VERSION ""

NS_ :

BS_:

BU_: ICC DVR EPC BBCM EAMP CMSM SBOX FLZCU_HCU_IC FLZCU_IC HCU_IC FLZCU_Signal_IC CGW TBOX BNCM CWC FRZCU

BO_ 1224 BMS_12: 16 CGW
 SG_ BMS_HvBattCellVoltMax_Num : 23|8@0+ (1,0) [0|250] ""  ICC
 SG_ BMS_HvBattCellVoltMax : 31|16@0+ (0.001,0) [0|15] "V"  ICC
 SG_ BMS_HvBattCellVoltMin_Num : 47|8@0+ (1,0) [0|250] ""  ICC
 SG_ BMS_HvBattCellVoltMin : 55|16@0+ (0.001,0) [0|15] "V"  ICC
 SG_ BMS_Chg_Sts : 87|4@0+ (1,0) [0|15] ""  ICC

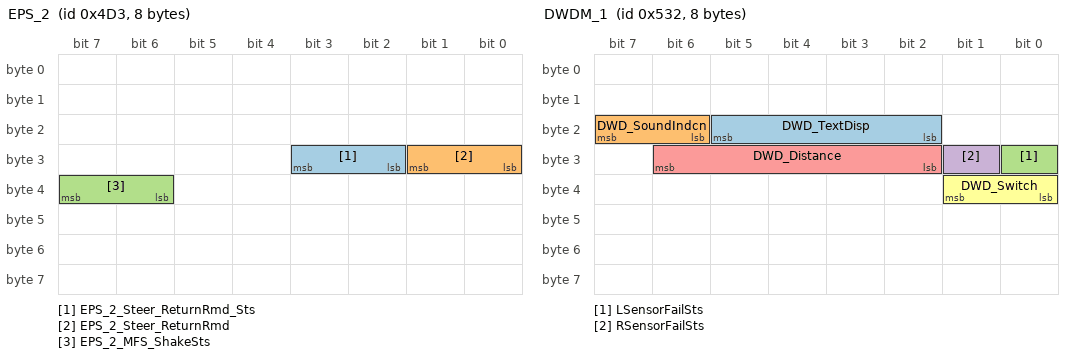
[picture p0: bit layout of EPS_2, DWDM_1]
BO_ 1235 EPS_2: 8 CGW
 SG_ EPS_2_Steer_ReturnRmd_Sts : 27|2@0+ (1,0) [0|3] ""  ICC
 SG_ EPS_2_Steer_ReturnRmd : 25|2@0+ (1,0) [0|3] ""  ICC
 SG_ EPS_2_MFS_ShakeSts : 39|2@0+ (1,0) [0|3] ""  ICC

BO_ 1330 DWDM_1: 8 CGW
 SG_ DWD_TextDisp : 21|4@0+ (1,0) [0|15] ""  ICC
 SG_ DWD_SoundIndcn : 23|2@0+ (1,0) [0|3] ""  ICC
 SG_ LSensorFailSts : 24|1@0+ (1,0) [0|1] ""  ICC
 SG_ RSensorFailSts : 25|1@0+ (1,0) [0|1] ""  ICC
 SG_ DWD_Distance : 30|5@0+ (1,0) [0|31] ""  ICC
 SG_ DWD_Switch : 33|2@0+ (1,0) [0|3] ""  ICC

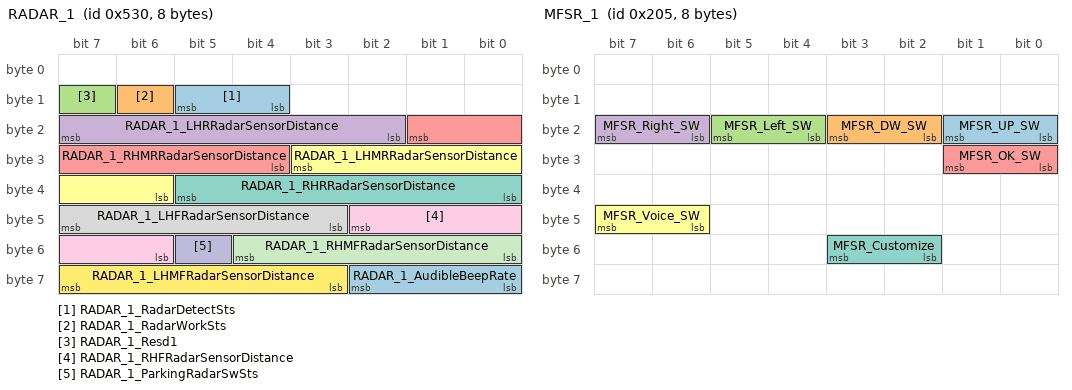
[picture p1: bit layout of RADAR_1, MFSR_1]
BO_ 1328 RADAR_1: 8 CGW
 SG_ RADAR_1_RadarDetectSts : 13|2@0+ (1,0) [0|3] "Bit"  ICC
 SG_ RADAR_1_RadarWorkSts : 14|1@0+ (1,0) [0|1] "Bit"  ICC
 SG_ RADAR_1_Resd1 : 15|1@0+ (1,0) [0|1] ""  ICC
 SG_ RADAR_1_LHRRadarSensorDistance : 23|6@0+ (5,25) [25|180] "Cm"  ICC
 SG_ RADAR_1_RHMRRadarSensorDistance : 17|6@0+ (5,25) [25|180] "Cm"  ICC
 SG_ RADAR_1_LHMRRadarSensorDistance : 27|6@0+ (5,25) [25|180] "Cm"  ICC
 SG_ RADAR_1_RHRRadarSensorDistance : 37|6@0+ (5,25) [25|180] "Cm"  ICC
 SG_ RADAR_1_LHFRadarSensorDistance : 47|5@0+ (5,25) [25|160] "Cm"  ICC
 SG_ RADAR_1_RHFRadarSensorDistance : 42|5@0+ (5,25) [25|160] "Cm"  ICC
 SG_ RADAR_1_ParkingRadarSwSts : 53|1@0+ (1,0) [0|1] "Bit"  ICC
 SG_ RADAR_1_RHMFRadarSensorDistance : 52|5@0+ (5,25) [25|160] "Cm"  ICC
 SG_ RADAR_1_LHMFRadarSensorDistance : 63|5@0+ (5,25) [25|160] "Cm"  ICC
 SG_ RADAR_1_AudibleBeepRate : 58|3@0+ (1,0) [0|7] "Bit"  ICC

BO_ 259 EMS_6: 16 CGW
 SG_ EMS_EngineSpeed_Actual : 39|16@0+ (0.25,0) [0|16383] "rpm"  ICC

BO_ 1234 FRZCU_11: 32 CGW
 SG_ FRZCU_FRSeatHeiFb : 23|7@0+ (1,-1) [-1|100] "%"  ICC,BBCM
 SG_ FRZCU_FRSeatLvlFb : 31|7@0+ (1,-1) [-1|100] "%"  ICC,BBCM
 SG_ FRZCU_FRSeatBackAgFb : 39|7@0+ (1,-1) [-1|100] "%"  ICC,BBCM
 SG_ FRZCU_FRSeatLegSpprtFb : 47|7@0+ (1,-1) [-1|100] "%"  ICC
 SG_ FRZCU_FRWinSts : 55|3@0+ (1,0) [0|7] ""  ICC
 SG_ FRZCU_RRWinSts : 52|3@0+ (1,0) [0|7] ""  ICC
 SG_ FRZCU_FRSeatLegRestAngleFb : 62|7@0+ (1,-1) [-1|100] "%"  ICC
 SG_ FRZCU_FRSeatCushFb : 86|7@0+ (1,-1) [-1|100] "%"  ICC,BBCM
 SG_ FRZCU_FRSeatNeedMemory : 105|2@0+ (1,0) [0|3] ""  ICC
 SG_ FRZCU_FRMemoryFb : 107|2@0+ (1,0) [0|3] ""  ICC
 SG_ FRZCU_FRRecoverFb : 109|2@0+ (1,0) [0|3] ""  ICC
 SG_ FRZCU_EasyEntryExitFb : 111|2@0+ (1,0) [0|3] ""  ICC
 SG_ FRZCU_EnjoyableSeatWarning : 113|2@0+ (1,0) [0|3] ""  ICC
 SG_ FRZCU_EnjoyableSeatSts : 115|2@0+ (1,0) [0|3] ""  ICC
 SG_ SeatHeatLevelsFR : 127|3@0+ (1,0) [0|7] ""  ICC
 SG_ SeatVentLevelsFR : 123|2@0+ (1,0) [0|3] ""  ICC
 SG_ SeatHeatLevelsRR : 151|3@0+ (1,0) [0|7] ""  ICC
 SG_ SeatVentLevelsRR : 147|2@0+ (1,0) [0|3] ""  ICC
 SG_ FRZCU_FRSeatFoldFb : 167|7@0+ (1,-1) [-1|100] "%"  ICC

BO_ 517 MFSR_1: 8 CGW
 SG_ MFSR_UP_SW : 17|2@0+ (1,0) [0|3] ""  ICC
 SG_ MFSR_DW_SW : 19|2@0+ (1,0) [0|3] ""  ICC
 SG_ MFSR_Left_SW : 21|2@0+ (1,0) [0|3] ""  ICC
 SG_ MFSR_Right_SW : 23|2@0+ (1,0) [0|3] ""  ICC
 SG_ MFSR_OK_SW : 25|2@0+ (1,0) [0|3] ""  ICC
 SG_ MFSR_Voice_SW : 47|2@0+ (1,0) [0|3] ""  ICC
 SG_ MFSR_Customize : 51|2@0+ (1,0) [0|3] ""  ICC

BO_ 1096 TMS_11: 32 CGW
 SG_ TMS_AutoDefogActiveSts : 37|1@0+ (1,0) [0|1] ""  ICC
 SG_ TMS_AirPurgeReminderSts : 17|2@0+ (1,0) [0|3] ""  ICC
 SG_ TMS_BT_Reduce_Wind_SpeedSts : 23|2@0+ (1,0) [0|3] "Bit"  ICC
 SG_ TMS_First_BlowingSts : 21|2@0+ (1,0) [0|3] "Bit"  ICC
 SG_ TMS_CirculationInTunnelsSts : 19|2@0+ (1,0) [0|3] "Bit"  ICC
 SG_ TMS_crosscountry_coolingSts : 29|2@0+ (1,0) [0|3] "Bit"  ICC
 SG_ TMS_ParkingAirConditioningStatus : 27|2@0+ (1,0) [0|3] "Bit"  ICC
 SG_ TMS_CoolantFillSts : 25|2@0+ (1,0) [0|3] "Bit"  ICC
 SG_ TMS_UVC_ControlSts : 39|2@0+ (1,0) [0|3] "Bit"  ICC
 SG_ TMS_UVC_LuminanceSts : 36|3@0+ (1,0) [0|7] "Bit"  ICC
 SG_ TMS_ICC_Lightoff_Sts : 33|2@0+ (1,0) [0|3] ""  ICC
 SG_ TMS_ICC_Memoff_Sts : 47|2@0+ (1,0) [0|3] ""  ICC
 SG_ TMS_keepwarmSet_TemperatureSts : 55|8@0+ (1,0) [0|254] "Bit"  ICC
 SG_ TMS_BiochemicalFuncSts : 95|2@0+ (1,0) [0|3] ""  ICC
 SG_ TMS_TimedVentilationSts : 97|2@0+ (1,0) [0|3] ""  ICC

BO_ 1240 TDU_9: 32 CGW
 SG_ TMS_CFSSwitchFb : 17|2@0+ (1,0) [0|3] ""  ICC
 SG_ TDU_CFSPosOneType : 21|4@0+ (1,0) [0|15] ""  ICC
 SG_ TDU_CFSPosTwoType : 27|4@0+ (1,0) [0|15] ""  ICC
 SG_ TDU_CFSPosThreeType : 31|4@0+ (1,0) [0|15] ""  ICC
 SG_ TDU_CFSRunOut : 39|4@0+ (1,0) [0|15] ""  ICC
 SG_ TMS_CFSShortWarn : 43|4@0+ (1,0) [0|15] ""  ICC
 SG_ TMS_CFSLevelSetFb : 47|4@0+ (1,0) [0|15] ""  ICC
 SG_ TMS_CFSPosSetFb : 49|2@0+ (1,0) [0|3] ""  ICC
 SG_ TMS_CFSPosOneLife : 63|8@0+ (1,0) [0|100] "%"  ICC
 SG_ TMS_CFSPosTwoLife : 87|8@0+ (1,0) [0|100] "%"  ICC
 SG_ TMS_CFSPosThreeLife : 95|8@0+ (1,0) [0|100] "%"  ICC
 SG_ TMS_PM25SwitchFb : 97|2@0+ (1,0) [0|3] ""  ICC
 SG_ TMS_ThrModeStsFb : 122|3@0+ (1,0) [0|6] ""  ICC
 SG_ TMS_ThrSetTempFb_C : 127|5@0+ (0.5,15.5) [15.5|30.5] "℃"  ICC
 SG_ TMS_ThrCLMSwitchFb : 145|2@0+ (1,0) [0|3] ""  ICC
 SG_ TMS_ThrAutoSwitchFb : 147|2@0+ (1,0) [0|3] ""  ICC
 SG_ TMS_ThrBlowSpeedLevelKeyStsFb : 151|4@0+ (1,0) [0|15] ""  ICC

BO_ 638 FRZCU_9: 16 CGW
 SG_ FRZCU_HoodSts : 45|2@0+ (1,0) [0|3] ""  ICC
 SG_ FRZCU_AuthenResult : 48|1@0+ (1,0) [0|1] ""  ICC
 SG_ FRZCU_PowerMode : 51|2@0+ (1,0) [0|3] ""  ICC
 SG_ FRZCU_TrunkSts : 53|2@0+ (1,0) [0|3] ""  ICC
 SG_ FRZCU_HandleSwitchStsFL : 57|2@0+ (1,0) [0|3] ""  ICC,BBCM
 SG_ FRZCU_HandleSwitchStsFR : 59|2@0+ (1,0) [0|3] ""  ICC,BBCM
 SG_ FRZCU_HandleSwitchStsRR : 61|2@0+ (1,0) [0|3] ""  ICC
 SG_ FRZCU_HandleSwitchStsRL : 63|2@0+ (1,0) [0|3] ""  ICC
 SG_ SeatLength_target_Passenger : 87|4@0+ (1,0) [0|15] ""  ICC
 SG_ SeatBackrest_target_Passenger : 95|5@0+ (1,0) [0|15] ""  ICC
 SG_ FRZCU_TrunkLockSts : 89|2@0+ (1,0) [0|3] ""  ICC
 SG_ FRZCU_HoodLockSts : 103|2@0+ (1,0) [0|3] ""  ICC
 SG_ FrontBackSpeedAdj_Cmd : 101|3@0+ (1,0) [0|7] ""  ICC
 SG_ FRZCU_GloveboxSW : 98|1@0+ (1,0) [0|1] ""  ICC
 SG_ FRZCU_FRReleaseLockSts : 111|3@0+ (1,0) [0|7] ""  ICC
 SG_ FRZCU_RRReleaseLockSts : 108|3@0+ (1,0) [0|7] ""  ICC
 SG_ FRZCU_PELockInKeyWarning : 105|1@0+ (1,0) [0|1] ""  ICC
 SG_ FRZCU_PowerOFFWarning : 118|1@0+ (1,0) [0|1] ""  ICC
 SG_ FRZCU_KeylessWarning : 116|1@0+ (1,0) [0|1] ""  ICC
 SG_ FRZCU_OTAPwrDwnReqFb : 113|2@0+ (1,0) [0|3] ""  ICC
 SG_ FRZCU_OTAPwrOnReqFb : 127|2@0+ (1,0) [0|3] ""  ICC

BO_ 949 PEPS_1: 16 CGW
 SG_ PEPS_InformationSource : 23|2@0+ (1,0) [0|3] ""  ICC,BBCM
 SG_ PEPS_OrderInformation : 21|4@0+ (1,0) [0|15] ""  ICC,BBCM
 SG_ PEPS_IDInformation : 31|4@0+ (1,0) [0|15] ""  ICC,BBCM
 SG_ PEPS_KeySts : 27|3@0+ (1,0) [0|7] ""  ICC,BBCM
 SG_ PEPS_ETRUnLockReq : 39|2@0+ (1,0) [0|3] ""  ICC,BBCM

BO_ 1028 PEPS_2: 16 CGW
 SG_ PEPS_WelcomeON : 17|2@0+ (1,0) [0|3] ""  ICC,BBCM
 SG_ PEPS_VehicleSearchReq : 19|2@0+ (1,0) [0|3] ""  ICC,BBCM
 SG_ PEPS_SATOReminder : 21|2@0+ (1,0) [0|3] ""  ICC,BBCM
 SG_ PEPS_PLGUnlockReq : 23|2@0+ (1,0) [0|3] ""  ICC,BBCM
 SG_ PEPS_RKETrunkSts : 25|2@0+ (1,0) [0|3] ""  ICC,BBCM
 SG_ PEPS_SSBInhibitCWCSts : 27|2@0+ (1,0) [0|3] ""  ICC,BBCM
 SG_ PEPS_WirelessChargingCtrSts : 29|2@0+ (1,0) [0|3] ""  ICC,BBCM
 SG_ PEPS_EmgyShutdown : 35|2@0+ (1,0) [0|3] ""  ICC,BBCM
 SG_ PEPS_SSBInputFailure : 37|2@0+ (1,0) [0|3] ""  ICC,BBCM
 SG_ PEPS_SmartSystemWarning1_1 : 39|2@0+ (1,0) [0|3] ""  ICC,BBCM
 SG_ PEPS_SmartSystemWarning2_2 : 41|2@0+ (1,0) [0|3] ""  ICC,BBCM
 SG_ PEPS_SmartSystemWarning3_1 : 43|2@0+ (1,0) [0|3] ""  ICC,BBCM
 SG_ PEPS_SmartSystemWarning3_2 : 45|2@0+ (1,0) [0|3] ""  ICC,BBCM
 SG_ PEPS_SmartSystemWarning4_2 : 47|2@0+ (1,0) [0|3] ""  ICC,BBCM
 SG_ PEPS_SmartSystemWarning4_3 : 49|2@0+ (1,0) [0|3] ""  ICC,BBCM
 SG_ PEPS_SystemWarning : 51|2@0+ (1,0) [0|3] ""  ICC,BBCM
 SG_ PEPS_BLTKeyPESts : 53|2@0+ (1,0) [0|3] ""  ICC,BBCM

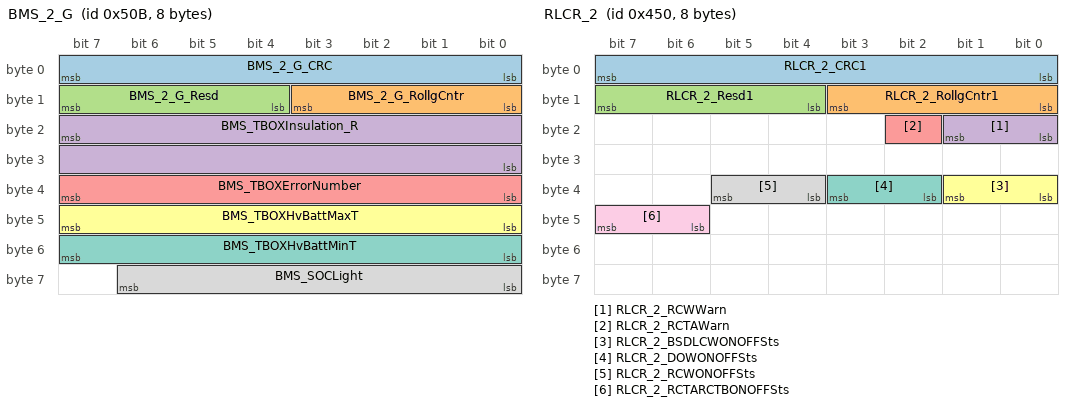
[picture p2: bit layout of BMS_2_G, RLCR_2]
BO_ 1291 BMS_2_G: 8 CGW
 SG_ BMS_2_G_CRC : 7|8@0+ (1,0) [0|255] ""  ICC
 SG_ BMS_2_G_RollgCntr : 11|4@0+ (1,0) [0|14] ""  ICC
 SG_ BMS_2_G_Resd : 15|4@0+ (1,0) [0|15] ""  ICC
 SG_ BMS_TBOXInsulation_R : 23|16@0+ (1,0) [0|60000] "kiloohm(kΩ)"  ICC
 SG_ BMS_TBOXErrorNumber : 39|8@0+ (1,0) [0|255] ""  ICC
 SG_ BMS_TBOXHvBattMaxT : 47|8@0+ (1,-40) [-40|210] "gradcelsius(°C)"  ICC
 SG_ BMS_TBOXHvBattMinT : 55|8@0+ (1,-40) [-40|210] "gradcelsius(°C)"  ICC
 SG_ BMS_SOCLight : 62|7@0+ (1,0) [0|100] "%"  ICC

BO_ 1104 RLCR_2: 8 CGW
 SG_ RLCR_2_CRC1 : 7|8@0+ (1,0) [0|255] ""  ICC
 SG_ RLCR_2_RollgCntr1 : 11|4@0+ (1,0) [0|14] ""  ICC
 SG_ RLCR_2_Resd1 : 15|4@0+ (1,0) [0|15] ""  ICC
 SG_ RLCR_2_RCWWarn : 17|2@0+ (1,0) [0|3] ""  ICC
 SG_ RLCR_2_RCTAWarn : 18|1@0+ (1,0) [0|1] ""  ICC
 SG_ RLCR_2_BSDLCWONOFFSts : 33|2@0+ (1,0) [0|3] ""  ICC
 SG_ RLCR_2_DOWONOFFSts : 35|2@0+ (1,0) [0|3] ""  ICC
 SG_ RLCR_2_RCWONOFFSts : 37|2@0+ (1,0) [0|3] ""  ICC
 SG_ RLCR_2_RCTARCTBONOFFSts : 47|2@0+ (1,0) [0|3] ""  ICC

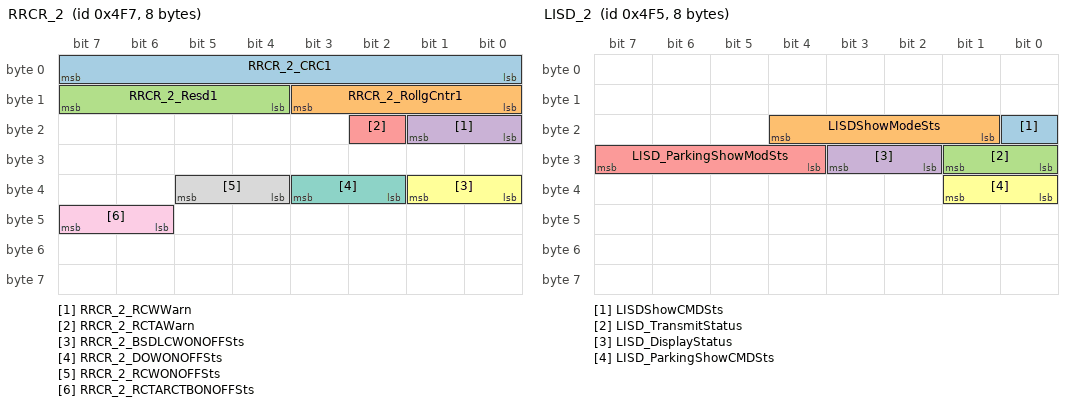
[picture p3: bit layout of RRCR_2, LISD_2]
BO_ 1271 RRCR_2: 8 CGW
 SG_ RRCR_2_CRC1 : 7|8@0+ (1,0) [0|255] ""  ICC
 SG_ RRCR_2_RollgCntr1 : 11|4@0+ (1,0) [0|14] ""  ICC
 SG_ RRCR_2_Resd1 : 15|4@0+ (1,0) [0|15] ""  ICC
 SG_ RRCR_2_RCWWarn : 17|2@0+ (1,0) [0|3] ""  ICC
 SG_ RRCR_2_RCTAWarn : 18|1@0+ (1,0) [0|1] ""  ICC
 SG_ RRCR_2_BSDLCWONOFFSts : 33|2@0+ (1,0) [0|3] ""  ICC
 SG_ RRCR_2_DOWONOFFSts : 35|2@0+ (1,0) [0|3] ""  ICC
 SG_ RRCR_2_RCWONOFFSts : 37|2@0+ (1,0) [0|3] ""  ICC
 SG_ RRCR_2_RCTARCTBONOFFSts : 47|2@0+ (1,0) [0|3] ""  ICC

BO_ 587 ONEBOX_4: 48 CGW
 SG_ IPB_SandABSSwSts_24Bh : 279|2@0+ (1,0) [0|3] ""  ICC
 SG_ IPB_SandABSAvl_24Bh : 277|2@0+ (1,0) [0|3] ""  ICC
 SG_ ONEBOX_4_LHFWheelSpeedRPM : 23|16@0+ (0.0625,0) [0|4095.875] "rpm"  ICC
 SG_ ONEBOX_4_RHFWheelSpeedRPM : 39|16@0+ (0.0625,0) [0|4095.875] "rpm"  ICC
 SG_ LHRWheelSpeedRPM : 55|16@0+ (0.0625,0) [0|4095.875] "rpm"  ICC
 SG_ RHRWheelSpeedRPM : 87|16@0+ (0.0625,0) [0|4095.875] "rpm"  ICC
 SG_ LHRPulseCounterFailSts : 106|1@0+ (1,0) [0|1] ""  ICC
 SG_ LHRPulseCounter : 103|13@0+ (1,0) [0|8191] "pulse"  ICC
 SG_ RHRPulseCounterFailSts : 122|1@0+ (1,0) [0|1] ""  ICC
 SG_ RHRPulseCounter : 119|13@0+ (1,0) [0|8191] "pulse"  ICC
 SG_ RHFPulseCounterFailSts : 154|1@0+ (1,0) [0|1] ""  ICC
 SG_ RHFPulseCounter : 151|13@0+ (1,0) [0|8191] "pulse"  ICC
 SG_ LHFPulseCounterFailSts : 170|1@0+ (1,0) [0|1] ""  ICC
 SG_ LHFPulseCounter : 167|13@0+ (1,0) [0|8191] "pulse"  ICC
 SG_ LHFWheelDriveDirection : 187|3@0+ (1,0) [0|7] ""  ICC
 SG_ RHFWheelDriveDirection : 219|3@0+ (1,0) [0|7] ""  ICC
 SG_ LHRWheelDriveDirection : 235|3@0+ (1,0) [0|7] ""  ICC
 SG_ RHRWheelDriveDirection : 251|3@0+ (1,0) [0|7] ""  ICC

BO_ 1338 FMCU_1_G: 8 CGW
 SG_ FMCU_ErrLvlDis : 19|3@0+ (1,0) [0|7] ""  ICC
 SG_ FMCU_SpdAct_EDR : 39|16@0+ (1,-32767) [-32767|32766] "rpm"  ICC

BO_ 777 ISGF_2: 8 CGW
 SG_ ISGF_ErrLvl : 20|4@0+ (1,0) [0|6] ""  ICC

BO_ 1403 RMCU_1_G: 8 CGW
 SG_ RMCU_ErrLvlDis : 19|3@0+ (1,0) [0|7] ""  ICC
 SG_ RMCU_Speed_EDR : 39|16@0+ (1,-32767) [-32767|32766] "rpm"  ICC

BO_ 1299 BMS_1_G: 8 CGW
 SG_ BMS_PackVoltageDis : 23|16@0+ (0.1,0) [0|1000] "volt(V)"  ICC
 SG_ BMS_PackCurrentDis : 39|16@0+ (0.1,-2047) [-2047|2047] "ampere(A)"  ICC

BO_ 1099 ISGF_4: 8 CGW
 SG_ ISGF_SysTempOvrInd : 40|1@0+ (1,0) [0|1] ""  ICC

BO_ 1130 TCU_23: 64 CGW
 SG_ TCU_23_GBFaultstatus : 23|2@0+ (1,0) [0|3] ""  ICC
 SG_ TCU_23_TeachInState : 30|3@0+ (1,0) [0|7] ""  ICC

BO_ 1180 ACU_1: 8 CGW
 SG_ New_Signal_49C_8 : 32|25@0+ (1,0) [0|33554431] ""  ICC
 SG_ New_Signal_49C_7 : 37|4@0+ (1,0) [0|15] ""  ICC
 SG_ New_Signal_49C_6 : 27|1@0+ (1,0) [0|1] ""  ICC
 SG_ New_Signal_49C_5 : 29|1@0+ (1,0) [0|1] ""  ICC
 SG_ New_Signal_49C_4 : 31|1@0+ (1,0) [0|1] ""  ICC
 SG_ New_Signal_49C_3 : 19|2@0+ (1,0) [0|3] ""  ICC
 SG_ New_Signal_49C_2 : 21|1@0+ (1,0) [0|1] ""  ICC
 SG_ New_Signal_49C_1 : 23|1@0+ (1,0) [0|1] ""  ICC
 SG_ ABM_1_Rollover_Status : 33|1@0+ (1,0) [0|1] ""  ICC
 SG_ ACU_1_Resd1 : 15|4@0+ (1,0) [0|15] ""  ICC
 SG_ ACU_1_RollgCntr1 : 11|4@0+ (1,0) [0|14] ""  ICC
 SG_ ACU_1_CRC1 : 7|8@0+ (1,0) [0|255] ""  ICC
 SG_ ACU_1_AirBagFailSts : 17|2@0+ (1,0) [0|3] ""  ICC
 SG_ ACU_1_ThdRowLBeltWarning : 20|1@0+ (1,0) [0|1] ""  ICC
 SG_ ACU_1_ThdRowRBeltWarning : 22|1@0+ (1,0) [0|1] ""  ICC
 SG_ ACU_1_PsngrSeatBeltWarning : 25|2@0+ (1,0) [0|3] ""  ICC
 SG_ ACU_1_SecRowLBeltWarning : 26|1@0+ (1,0) [0|1] ""  ICC
 SG_ ACU_1_SecRowMBeltWarning : 28|1@0+ (1,0) [0|1] ""  ICC
 SG_ ACU_1_SecRowRBeltWarning : 30|1@0+ (1,0) [0|1] ""  ICC
 SG_ ACU_1_PsngrSeatOccupiedSts : 39|2@0+ (1,0) [0|3] ""  ICC

BO_ 1248 FRZCU_TO_FLZCU: 48 CGW

BO_ 1341 BMS_44: 48 CGW
 SG_ BMS_44_PackPowerRealTime : 23|15@0+ (0.1,-1024) [-1024|1024] "kW"  ICC

BO_ 811 BMS_6: 16 CGW
 SG_ BMS_Chg_Sts : 87|4@0+ (1,0) [0|15] ""  ICC

BO_ 1269 LISD_2: 8 CGW
 SG_ LISDShowCMDSts : 16|1@0+ (1,0) [0|1] ""  ICC
 SG_ LISDShowModeSts : 20|4@0+ (1,0) [0|15] ""  ICC
 SG_ LISD_TransmitStatus : 25|2@0+ (1,0) [0|3] ""  ICC
 SG_ LISD_DisplayStatus : 27|2@0+ (1,0) [0|3] ""  ICC
 SG_ LISD_ParkingShowModSts : 31|4@0+ (1,0) [0|15] ""  ICC
 SG_ LISD_ParkingShowCMDSts : 33|2@0+ (1,0) [0|3] ""  ICC

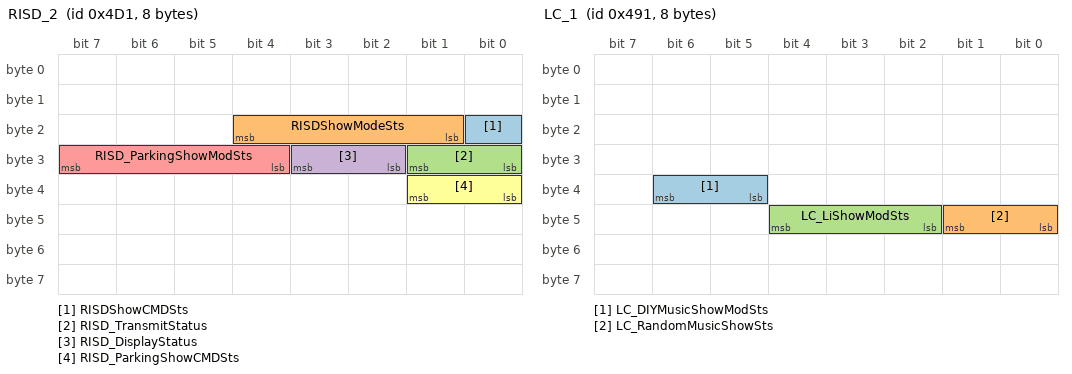
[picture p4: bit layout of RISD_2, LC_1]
BO_ 1233 RISD_2: 8 CGW
 SG_ RISDShowCMDSts : 16|1@0+ (1,0) [0|1] ""  ICC
 SG_ RISDShowModeSts : 20|4@0+ (1,0) [0|15] ""  ICC
 SG_ RISD_TransmitStatus : 25|2@0+ (1,0) [0|3] ""  ICC
 SG_ RISD_DisplayStatus : 27|2@0+ (1,0) [0|3] ""  ICC
 SG_ RISD_ParkingShowModSts : 31|4@0+ (1,0) [0|15] ""  ICC
 SG_ RISD_ParkingShowCMDSts : 33|2@0+ (1,0) [0|3] ""  ICC

BO_ 1169 LC_1: 8 CGW
 SG_ LC_DIYMusicShowModSts : 38|2@0+ (1,0) [0|3] ""  ICC
 SG_ LC_RandomMusicShowSts : 41|2@0+ (1,0) [0|3] ""  ICC
 SG_ LC_LiShowModSts : 44|3@0+ (1,0) [0|7] ""  ICC

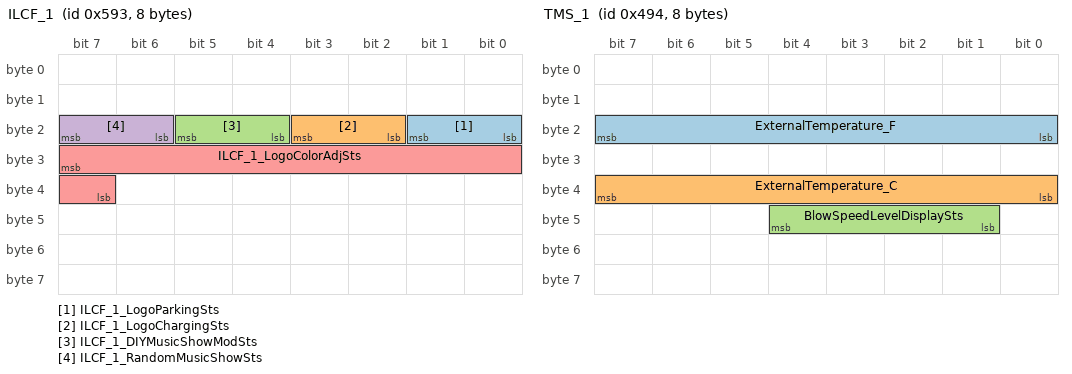
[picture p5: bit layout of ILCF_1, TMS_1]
BO_ 1427 ILCF_1: 8 CGW
 SG_ ILCF_1_LogoParkingSts : 17|2@0+ (1,0) [0|3] ""  ICC
 SG_ ILCF_1_LogoChargingSts : 19|2@0+ (1,0) [0|3] ""  ICC
 SG_ ILCF_1_DIYMusicShowModSts : 21|2@0+ (1,0) [0|3] ""  ICC
 SG_ ILCF_1_RandomMusicShowSts : 23|2@0+ (1,0) [0|3] ""  ICC
 SG_ ILCF_1_LogoColorAdjSts : 31|9@0+ (1,0) [0|511] ""  ICC

BO_ 821 ADS_5: 48 CGW
 SG_ ADS_5_CRC1 : 7|8@0+ (1,0) [0|255] ""  ICC
 SG_ ADS_5_RollgCntr1 : 11|4@0+ (1,0) [0|14] ""  ICC
 SG_ ADS_5_Resd1 : 15|4@0+ (1,0) [0|15] ""  ICC
 SG_ ADS_5_ILOASts : 18|3@0+ (1,0) [0|7] ""  ICC
 SG_ ADS_5_ICAQuitReason : 21|3@0+ (1,0) [0|7] ""  ICC
 SG_ ADS_5_ISLISt : 23|2@0+ (1,0) [0|3] ""  ICC
 SG_ ADS_5_ILOATextInfo : 28|2@0+ (1,0) [0|3] ""  ICC
 SG_ ADS_5_ILOAActdirection : 30|2@0+ (1,0) [0|3] ""  ICC
 SG_ ADS_5_LKS_warning : 31|1@0+ (1,0) [0|1] ""  ICC
 SG_ ADS_5_ISLIOverSpeedWarn : 34|2@0+ (1,0) [0|3] ""  ICC
 SG_ ADS_5_ISLISpeedLimitSign : 26|8@0+ (1,0) [0|255] ""  ICC
 SG_ ADS_5_EgoLeftLineHeatgAg : 32|9@0+ (0.004,-1.02) [-1.02|1.02] "Rad"  ICC
 SG_ ADS_5_EgoLeLineID : 51|1@0+ (1,0) [0|1] ""  ICC
 SG_ ADS_5_EgoLeLineColor : 53|2@0+ (1,0) [0|3] ""  ICC
 SG_ ADS_5_EgoLeLineTyp : 55|2@0+ (1,0) [0|3] ""  ICC
 SG_ ADS_5_EgoLeLineHozlDst : 48|9@0+ (0.1,-25) [-25|25] "m"  ICC
 SG_ ADS_5_CRC2 : 71|8@0+ (1,0) [0|255] ""  ICC
 SG_ ADS_5_RollgCntr2 : 75|4@0+ (1,0) [0|14] ""  ICC
 SG_ ADS_5_Resd2 : 79|4@0+ (1,0) [0|15] ""  ICC
 SG_ ADS_5_NeborLeLineID : 89|1@0+ (1,0) [0|1] ""  ICC
 SG_ ADS_5_NeborLeLineColor : 91|2@0+ (1,0) [0|3] ""  ICC
 SG_ ADS_5_NeborLeLineTyp : 93|2@0+ (1,0) [0|3] ""  ICC
 SG_ ADS_5_EgoLeLineCrvt : 87|10@0+ (6E-005,-0.0156) [-0.0156|0.0156] "1/m"  ICC
 SG_ ADS_5_NeborLeLineHozlDst : 88|9@0+ (0.1,-25) [-25|25] "m"  ICC
 SG_ ADS_5_NeborRiLineID : 113|1@0+ (1,0) [0|1] ""  ICC
 SG_ ADS_5_NeborRiLineColor : 115|2@0+ (1,0) [0|3] ""  ICC
 SG_ ADS_5_NeborRiLineTyp : 117|2@0+ (1,0) [0|3] ""  ICC
 SG_ ADS_5_NeborLeLineCrvt : 111|10@0+ (6E-005,-0.0156) [-0.0156|0.0156] "1/m"  ICC
 SG_ ADS_5_NeborRiLineHozlDst : 112|9@0+ (0.1,-25) [-25|25] "m"  ICC
 SG_ ADS_5_CRC3 : 135|8@0+ (1,0) [0|255] ""  ICC
 SG_ ADS_5_RollgCntr3 : 139|4@0+ (1,0) [0|14] ""  ICC
 SG_ ADS_5_Resd3 : 143|4@0+ (1,0) [0|15] ""  ICC
 SG_ ADS_5_ELKSettingSt : 153|2@0+ (1,0) [0|3] ""  ICC
 SG_ ADS_5_LDWLDPSnvtySet : 155|2@0+ (1,0) [0|3] ""  ICC
 SG_ ADS_5_LDWWarnType : 157|2@0+ (1,0) [0|3] ""  ICC
 SG_ ADS_5_NeborRiLineCrvt : 151|10@0+ (6E-005,-0.0156) [-0.0156|0.0156] "1/m"  ICC
 SG_ ADS_5_IESSwtSet : 161|2@0+ (1,0) [0|3] ""  ICC
 SG_ ADS_5_IHCSettingSt : 163|2@0+ (1,0) [0|3] ""  ICC
 SG_ ADS_5_ISLIWarningMod : 165|2@0+ (1,0) [0|3] ""  ICC
 SG_ ADS_5_ICAEnableBtnSts : 167|2@0+ (1,0) [0|3] ""  ICC
 SG_ ADS_5_FCM_Camera_textinfo : 175|2@0+ (1,0) [0|3] ""  ICC
 SG_ ADS_5_EgoRiLineID : 183|2@0+ (1,0) [0|1] ""  ICC
 SG_ ADS_5_EgoRiLineTyp : 169|2@0+ (1,0) [0|3] ""  ICC
 SG_ ADS_5_EgoRiLineColor : 181|2@0+ (1,0) [0|3] ""  ICC
 SG_ ADS_5_EgoRiLineHozlDst : 179|9@0+ (0.1,-25) [-25|25] "m"  ICC
 SG_ ADS_5_CRC4 : 199|8@0+ (1,0) [0|255] ""  ICC
 SG_ ADS_5_RollgCntr4 : 203|4@0+ (1,0) [0|14] ""  ICC
 SG_ ADS_5_Resd4 : 207|4@0+ (1,0) [0|15] ""  ICC
 SG_ ADS_5_EgoRightLineHeatgAg : 215|9@0+ (0.004,-1.02) [-1.02|1.02] "Rad"  ICC
 SG_ ADS_5_EgoRiLineCrvt : 222|10@0+ (6E-005,-0.0156) [-0.0156|0.0156] "1/m"  ICC
 SG_ ADS_5_NeborLeftLineHeatgAg : 228|9@0+ (0.004,-1.02) [-1.02|1.02] "Rad"  ICC
 SG_ ADS_5_NeborRightLineHeatgAg : 235|9@0+ (0.004,-1.02) [-1.02|1.02] "Rad"  ICC

BO_ 819 ADS_4: 48 CGW
 SG_ ADS_4_CRC1 : 7|8@0+ (1,0) [0|255] ""  ICC
 SG_ ADS_4_RollgCntr1 : 11|4@0+ (1,0) [0|14] ""  ICC
 SG_ ADS_4_Resd1 : 15|4@0+ (1,0) [0|15] ""  ICC
 SG_ ADS_4_AEBStatus : 19|3@0+ (1,0) [0|7] ""  ICC
 SG_ ADS_4_ACCSts : 23|4@0+ (1,0) [0|15] ""  ICC
 SG_ ADS_4_TimeGapSet : 26|3@0+ (1,0) [0|7] ""  ICC
 SG_ ADS_4_FcwMode : 29|3@0+ (1,0) [0|7] ""  ICC
 SG_ ADS_4_AEBReqType : 16|3@0+ (1,0) [0|7] ""  ICC
 SG_ ADS_4_SetSpd : 39|8@0+ (1,0) [0|255] "kph"  ICC
 SG_ ADS_4_DAIStatus : 41|2@0+ (1,0) [0|3] ""  ICC
 SG_ ADS_4_ACCTextMessage : 45|4@0+ (1,0) [0|15] ""  ICC
 SG_ ADS_4_LongiTakeOverReq : 46|1@0+ (1,0) [0|1] ""  ICC
 SG_ ADS_4_SetSpdUnit : 47|1@0+ (1,0) [0|1] ""  ICC
 SG_ ADS_4_GoNotifier : 50|3@0+ (1,0) [0|7] ""  ICC
 SG_ ADS_4_DAISts : 52|2@0+ (1,0) [0|3] ""  ICC
 SG_ ADS_4_Radar_textinfo : 55|3@0+ (1,0) [0|7] ""  ICC
 SG_ ADS_4_SCF_PopoverReq : 57|1@0+ (1,0) [0|1] ""  ICC
 SG_ ADS_4_DrvrCfmSCFDispFb : 58|1@0+ (1,0) [0|1] ""  ICC
 SG_ ADS_4_SCF_SpdLimUnit : 60|2@0+ (1,0) [0|3] ""  ICC
 SG_ ADS_4_SCF_SpdLimSts : 63|3@0+ (1,0) [0|7] ""  ICC
 SG_ ADS_4_CRC2 : 71|8@0+ (1,0) [0|255] ""  ICC
 SG_ ADS_4_RollgCntr2 : 75|4@0+ (1,0) [0|14] ""  ICC
 SG_ ADS_4_Resd2 : 79|4@0+ (1,0) [0|15] ""  ICC
 SG_ ADS_4_ACCObjTyp : 83|4@0+ (1,0) [0|15] ""  ICC
 SG_ ADS_4_FrntFarObjTyp : 87|4@0+ (1,0) [0|15] ""  ICC
 SG_ ADS_4_ACCObjLgtDstX : 95|8@0+ (0.5,0) [0|127] "m"  ICC
 SG_ ADS_4_FrntFarObjID : 107|1@0+ (1,0) [0|1] ""  ICC
 SG_ ADS_4_Resd : 108|1@0+ (1,0) [0|1] ""  ICC
 SG_ ADS_4_ACCObjID : 109|1@0+ (1,0) [0|1] ""  ICC
 SG_ ADS_4_ACCObjHozDstY : 103|10@0+ (0.1,-50) [-50|50] "m"  ICC
 SG_ ADS_4_FrntFarObjHozDstY : 105|10@0+ (0.1,-50) [-50|50] "m"  ICC
 SG_ ADS_4_FrntFarObjLgtDstX : 127|8@0+ (0.5,0) [0|127] "m"  ICC
 SG_ ADS_4_CRC3 : 135|8@0+ (1,0) [0|255] ""  ICC
 SG_ ADS_4_RollgCntr3 : 139|4@0+ (1,0) [0|14] ""  ICC
 SG_ ADS_4_Resd3 : 143|4@0+ (1,0) [0|15] ""  ICC
 SG_ ADS_4_Resd_1 : 146|1@0+ (1,0) [0|1] ""  ICC
 SG_ ADS_4_LeObjID : 147|1@0+ (1,0) [0|1] ""  ICC
 SG_ ADS_4_LeObjTyp : 151|4@0+ (1,0) [0|15] ""  ICC
 SG_ ADS_4_LeObjHozDstY : 145|10@0+ (0.1,-50) [-50|50] "m"  ICC
 SG_ ADS_4_LeObjLgtDstX : 167|8@0+ (0.5,0) [0|127] "m"  ICC
 SG_ ADS_4_RiObjID : 171|1@0+ (1,0) [0|1] ""  ICC
 SG_ ADS_4_RiObjTyp : 175|4@0+ (1,0) [0|15] ""  ICC
 SG_ ADS_4_RiObjHozDstY : 169|10@0+ (0.1,-50) [-50|50] "m"  ICC
 SG_ ADS_4_RiObjLgtDstX : 191|8@0+ (0.5,0) [0|127] "m"  ICC
 SG_ ADS_4_CRC4 : 199|8@0+ (1,0) [0|255] ""  ICC
 SG_ ADS_4_RollgCntr4 : 203|4@0+ (1,0) [0|14] ""  ICC
 SG_ ADS_4_Resd4 : 207|4@0+ (1,0) [0|15] ""  ICC
 SG_ ADS_4_SCFSwtSet : 210|2@0+ (1,0) [0|3] ""  ICC
 SG_ ADS_4_AEBSettingSt : 212|2@0+ (1,0) [0|3] ""  ICC
 SG_ ADS_4_FCWSettingSt : 215|3@0+ (1,0) [0|7] ""  ICC
 SG_ ADS_4_DAISwtSet : 223|2@0+ (1,0) [0|3] ""  ICC
 SG_ ADS_4_CruiseAccelerateSts : 221|2@0+ (1,0) [0|3] ""  ICC

BO_ 1172 TMS_1: 8 CGW
 SG_ ExternalTemperature_F : 23|8@0+ (1,-67) [-67|158] "°F"  ICC,EPC
 SG_ ExternalTemperature_C : 39|8@0+ (0.5,-40) [-40|85] "°C"  ICC,EPC
 SG_ BlowSpeedLevelDisplaySts : 44|4@0+ (1,0) [0|15] ""  ICC,EAMP

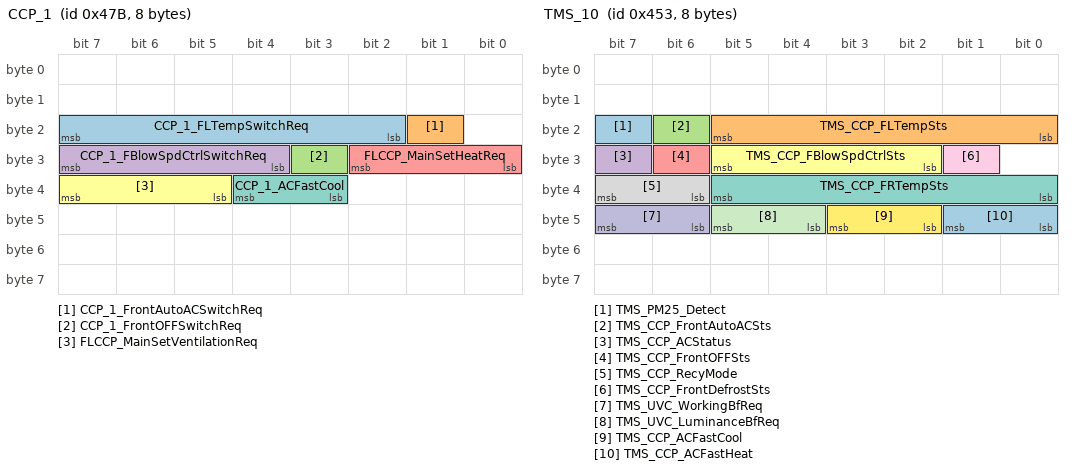
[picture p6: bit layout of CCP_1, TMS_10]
BO_ 1147 CCP_1: 8 CGW
 SG_ CCP_1_FLTempSwitchReq : 23|6@0+ (0.5,15.5) [15.5|30.5] "℃"  ICC
 SG_ CCP_1_FrontAutoACSwitchReq : 17|1@0+ (1,0) [0|1] ""  ICC
 SG_ CCP_1_FrontOFFSwitchReq : 27|1@0+ (1,0) [0|1] ""  ICC
 SG_ CCP_1_FBlowSpdCtrlSwitchReq : 31|4@0+ (1,0) [0|15] ""  ICC
 SG_ FLCCP_MainSetHeatReq : 26|3@0+ (1,0) [0|7] ""  ICC
 SG_ FLCCP_MainSetVentilationReq : 39|3@0+ (1,0) [0|7] ""  ICC
 SG_ CCP_1_ACFastCool : 36|2@0+ (1,0) [0|3] ""  ICC

BO_ 1107 TMS_10: 8 CGW
 SG_ TMS_PM25_Detect : 23|1@0+ (1,0) [0|1] ""  ICC
 SG_ TMS_CCP_FLTempSts : 21|6@0+ (0.5,15.5) [15.5|30.5] "℃"  ICC
 SG_ TMS_CCP_FrontAutoACSts : 22|1@0+ (1,0) [0|1] ""  ICC
 SG_ TMS_CCP_ACStatus : 31|1@0+ (1,0) [0|1] ""  ICC
 SG_ TMS_CCP_FrontOFFSts : 30|1@0+ (1,0) [0|1] ""  ICC
 SG_ TMS_CCP_FBlowSpdCtrlSts : 29|4@0+ (1,0) [0|15] ""  ICC
 SG_ TMS_CCP_FRTempSts : 37|6@0+ (0.5,15.5) [15.5|30.5] "℃"  ICC
 SG_ TMS_CCP_RecyMode : 39|2@0+ (1,0) [0|3] ""  ICC
 SG_ TMS_CCP_FrontDefrostSts : 25|1@0+ (1,0) [0|1] ""  ICC
 SG_ TMS_UVC_WorkingBfReq : 47|2@0+ (1,0) [0|3] ""  ICC
 SG_ TMS_UVC_LuminanceBfReq : 45|2@0+ (1,0) [0|3] ""  ICC
 SG_ TMS_CCP_ACFastCool : 43|2@0+ (1,0) [0|3] ""  ICC
 SG_ TMS_CCP_ACFastHeat : 41|2@0+ (1,0) [0|3] ""  ICC

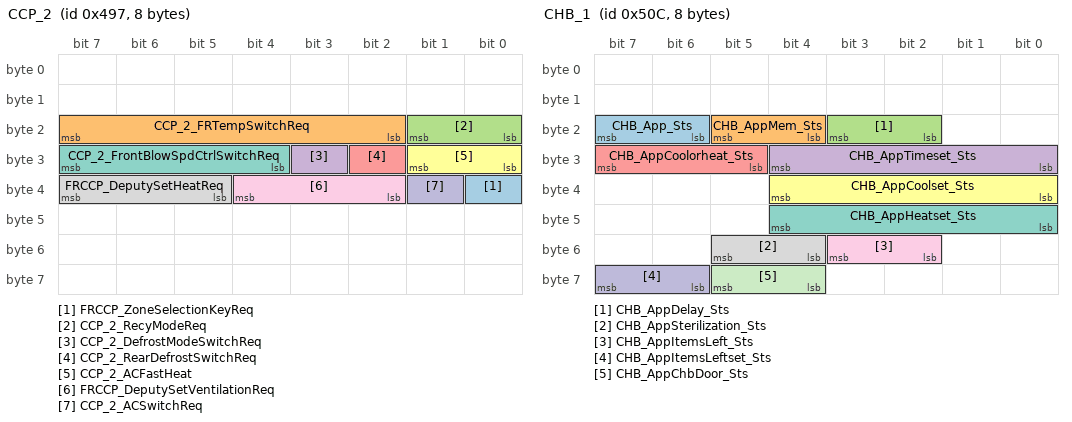
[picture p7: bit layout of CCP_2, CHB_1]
BO_ 1175 CCP_2: 8 CGW
 SG_ FRCCP_ZoneSelectionKeyReq : 32|1@0+ (1,0) [0|1] ""  ICC
 SG_ CCP_2_FRTempSwitchReq : 23|6@0+ (0.5,15.5) [15.5|30.5] "℃"  ICC
 SG_ CCP_2_RecyModeReq : 17|2@0+ (1,0) [0|3] ""  ICC
 SG_ CCP_2_DefrostModeSwitchReq : 27|1@0+ (1,0) [0|1] ""  ICC
 SG_ CCP_2_RearDefrostSwitchReq : 26|1@0+ (1,0) [0|1] ""  ICC
 SG_ CCP_2_ACFastHeat : 25|2@0+ (1,0) [0|3] ""  ICC
 SG_ CCP_2_FrontBlowSpdCtrlSwitchReq : 31|4@0+ (1,0) [0|15] ""  ICC
 SG_ FRCCP_DeputySetHeatReq : 39|3@0+ (1,0) [0|7] ""  ICC
 SG_ FRCCP_DeputySetVentilationReq : 36|3@0+ (1,0) [0|7] ""  ICC
 SG_ CCP_2_ACSwitchReq : 33|1@0+ (1,0) [0|1] ""  ICC

BO_ 1292 CHB_1: 8 CGW
 SG_ CHB_App_Sts : 23|2@0+ (1,0) [0|3] ""  ICC
 SG_ CHB_AppMem_Sts : 21|2@0+ (1,0) [0|3] ""  ICC
 SG_ CHB_AppDelay_Sts : 19|2@0+ (1,0) [0|3] ""  ICC
 SG_ CHB_AppTimeset_Sts : 28|5@0+ (1,0) [0|31] "h"  ICC
 SG_ CHB_AppCoolorheat_Sts : 31|3@0+ (1,0) [0|7] ""  ICC
 SG_ CHB_AppCoolset_Sts : 36|5@0+ (1,0) [0|31] ""  ICC
 SG_ CHB_AppHeatset_Sts : 44|5@0+ (1,0) [0|31] ""  ICC
 SG_ CHB_AppSterilization_Sts : 53|2@0+ (1,0) [0|3] ""  ICC
 SG_ CHB_AppItemsLeft_Sts : 51|2@0+ (1,0) [0|3] ""  ICC
 SG_ CHB_AppItemsLeftset_Sts : 63|2@0+ (1,0) [0|3] ""  ICC
 SG_ CHB_AppChbDoor_Sts : 61|2@0+ (1,0) [0|3] ""  ICC

BO_ 1241 EMS_4_G: 8 CGW
 SG_ FuelTankLidSystemFailureSts : 43|1@0+ (1,0) [0|1] ""  ICC
 SG_ FuelTankPressureConditionReached : 45|2@0+ (1,0) [0|3] ""  ICC

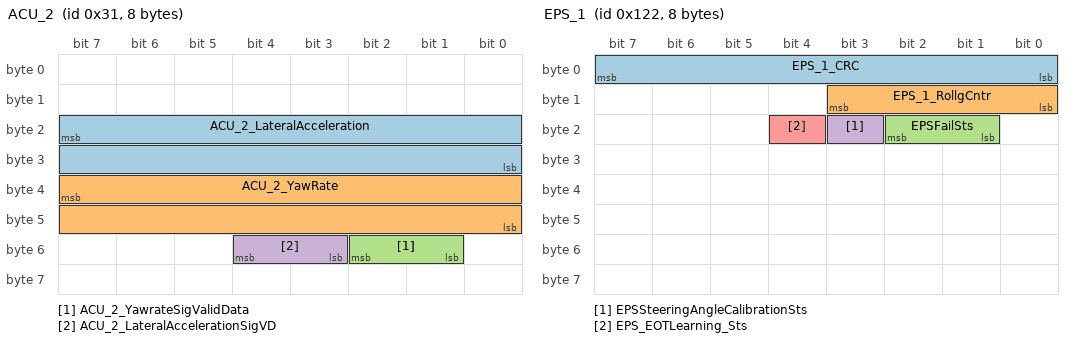
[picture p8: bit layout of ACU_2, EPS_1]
BO_ 49 ACU_2: 8 CGW
 SG_ ACU_2_LateralAcceleration : 23|16@0+ (0.001,-2) [-2|2] "g"  ICC
 SG_ ACU_2_YawRate : 39|16@0+ (0.01,-180) [-180|180] "deg/sec"  ICC
 SG_ ACU_2_YawrateSigValidData : 50|2@0+ (1,0) [0|3] ""  ICC
 SG_ ACU_2_LateralAccelerationSigVD : 52|2@0+ (1,0) [0|3] ""  ICC

BO_ 1024 FRZCU_13: 64 CGW
 SG_ FRZCU_QueenSeatPosSts : 80|1@0+ (1,0) [0|1] ""  ICC
 SG_ FRZCU_ADSLightFltSts : 63|2@0+ (1,0) [0|3] ""  ICC
 SG_ FRZCU_ADSLightSts : 49|2@0+ (1,0) [0|3] ""  ICC
 SG_ FRZCU_QueenSeatEnterSts : 57|2@0+ (1,0) [0|3] ""  ICC
 SG_ FRZCU_QueenSeatMovFailCause : 87|4@0+ (1,0) [0|15] ""  ICC
 SG_ FRZCU_QueenSeatSts : 83|2@0+ (1,0) [0|3] ""  BBCM,ICC
 SG_ FRZCU_PasgerSeatMovFailCause : 61|4@0+ (1,0) [0|15] ""  ICC
 SG_ CSunshadeSts : 23|3@0+ (1,0) [0|7] ""  ICC
 SG_ CSunshadePercentSts : 20|4@0+ (1,0) [0|15] ""  ICC
 SG_ FRZCU_SeatHeatLvlFR2 : 31|4@0+ (1,0) [0|15] ""  ICC
 SG_ FRZCU_SeatVentLvlFR2 : 27|4@0+ (1,0) [0|15] ""  ICC
 SG_ FRZCU_SeatVentLvlRR2 : 39|4@0+ (1,0) [0|15] ""  ICC
 SG_ FRZCU_SeatHeatLvlRR2 : 35|4@0+ (1,0) [0|15] ""  ICC
 SG_ FRZCU_ContainerlightSts : 47|2@0+ (1,0) [0|3] ""  ICC
 SG_ FRZCU_FRWinThermalSts : 45|1@0+ (1,0) [0|1] ""  ICC
 SG_ FRZCU_RRWinThermalSts : 44|1@0+ (1,0) [0|1] ""  ICC
 SG_ FRZCU_CSunshadeThermalSts : 43|1@0+ (1,0) [0|1] ""  ICC

BO_ 1182 CDU_OBC_3: 48 CGW
 SG_ OBC_InnerDischgVolt : 348|13@0+ (0.1,0) [0|800] "V"  ICC
 SG_ OBC_InnerDischgCurr : 343|10@0+ (0.1,0) [0|100] "A"  ICC
 SG_ OBC_ElectronicLockSts : 242|3@0+ (1,0) [0|4] ""  ICC
 SG_ OBC_WorkingMode : 251|4@0+ (1,0) [0|15] ""  ICC
 SG_ OBC_OutDischgCurr : 367|10@0+ (0.1,0) [0|100] "A"  ICC
 SG_ OBC_OutDischgVolt : 372|13@0+ (0.1,0) [0|800] "V"  ICC

BO_ 290 EPS_1: 8 CGW
 SG_ EPS_1_CRC : 7|8@0+ (1,0) [0|255] ""  ICC
 SG_ EPS_1_RollgCntr : 11|4@0+ (1,0) [0|14] ""  ICC
 SG_ EPSFailSts : 18|2@0+ (1,0) [0|3] ""  ICC
 SG_ EPSSteeringAngleCalibrationSts : 19|1@0+ (1,0) [0|1] ""  ICC
 SG_ EPS_EOTLearning_Sts : 20|1@0+ (1,0) [0|1] ""  ICC

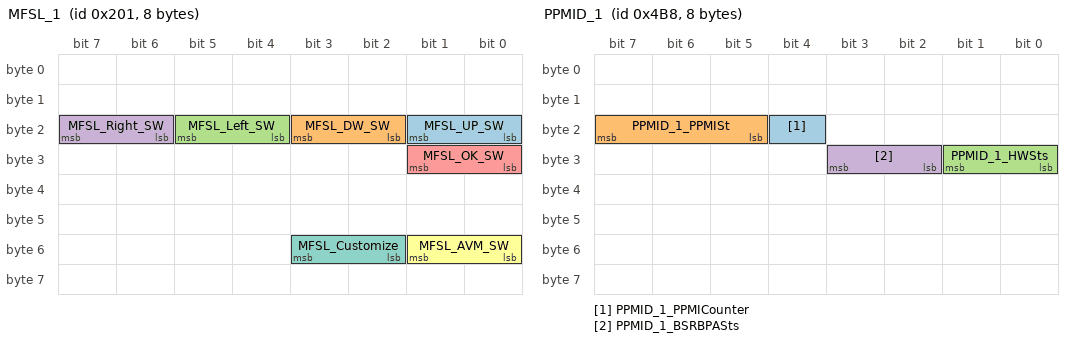
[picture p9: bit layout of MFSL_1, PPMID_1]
BO_ 513 MFSL_1: 8 CGW
 SG_ MFSL_UP_SW : 17|2@0+ (1,0) [0|3] ""  ICC
 SG_ MFSL_DW_SW : 19|2@0+ (1,0) [0|3] ""  ICC
 SG_ MFSL_Left_SW : 21|2@0+ (1,0) [0|3] ""  ICC
 SG_ MFSL_Right_SW : 23|2@0+ (1,0) [0|3] ""  ICC
 SG_ MFSL_OK_SW : 25|2@0+ (1,0) [0|3] ""  ICC
 SG_ MFSL_AVM_SW : 49|2@0+ (1,0) [0|3] ""  ICC
 SG_ MFSL_Customize : 51|2@0+ (1,0) [0|3] ""  ICC

BO_ 1152 TBOX_8: 16 CGW
 SG_ TBOX_PetmodeSetTemperature : 118|5@0+ (0.5,15.5) [15.5|30.5] "℃"  ICC

BO_ 1208 PPMID_1: 8 CGW
 SG_ PPMID_1_PPMICounter : 20|1@0+ (1,0) [0|1] ""  ICC
 SG_ PPMID_1_PPMISt : 23|3@0+ (1,0) [0|7] ""  ICC
 SG_ PPMID_1_HWSts : 25|2@0+ (1,0) [0|3] ""  ICC
 SG_ PPMID_1_BSRBPASts : 27|2@0+ (1,0) [0|3] ""  ICC

BO_ 794 ADS_COM_3: 24 CGW
 SG_ ADS_3_ICAStatus : 23|3@0+ (1,0) [0|7] ""  ICC
 SG_ ADS_3_ICATextinfo : 19|4@0+ (1,0) [0|15] ""  ICC
 SG_ ADS_3_ACCSts : 31|4@0+ (1,0) [0|15] ""  ICC
 SG_ ADS_3_DriverHandsoffWarning : 27|3@0+ (1,0) [0|7] ""  ICC
 SG_ ADS_3_LKSMod : 36|2@0+ (1,0) [0|3] ""  ICC
 SG_ ADS_3_LKSSts : 34|3@0+ (1,0) [0|7] ""  ICC
 SG_ ADS_3_ELKSts : 47|3@0+ (1,0) [0|7] ""  ICC
 SG_ ADS_3_LKSLeftTrackingSt : 44|2@0+ (1,0) [0|3] ""  ICC
 SG_ ADS_3_LKSRightTrackingSt : 42|2@0+ (1,0) [0|3] ""  ICC
 SG_ ADS_3_ELKLeftActiveSt : 55|2@0+ (1,0) [0|3] ""  ICC
 SG_ ADS_3_ELKRightActiveSt : 53|2@0+ (1,0) [0|3] ""  ICC

BO_ 1155 ASU_3: 16 CGW
 SG_ ASU_3_horizontalSts : 55|2@0+ (1,0) [0|3] ""  ICC
 SG_ ASU_3_horizontalmodeFb : 58|3@0+ (1,0) [0|7] ""  ICC

BO_ 1164 CDU_5: 64 CGW
 SG_ OBC_DischgSts : 123|3@0+ (1,0) [0|3] ""  ICC

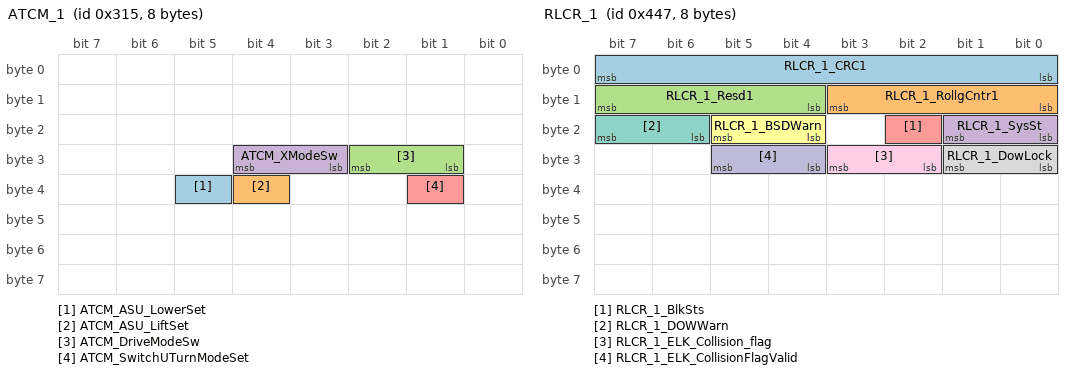
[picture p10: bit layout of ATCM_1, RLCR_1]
BO_ 789 ATCM_1: 8 CGW
 SG_ ATCM_ASU_LowerSet : 37|1@0+ (1,0) [0|1] ""  ICC
 SG_ ATCM_ASU_LiftSet : 36|1@0+ (1,0) [0|1] ""  ICC
 SG_ ATCM_DriveModeSw : 26|2@0+ (1,0) [0|3] ""  ICC
 SG_ ATCM_XModeSw : 28|2@0+ (1,0) [0|3] ""  ICC
 SG_ ATCM_SwitchUTurnModeSet : 33|1@0+ (1,0) [0|1] ""  ICC

BO_ 1214 BNCM_16: 32 CGW
 SG_ BNCM_16_CRC1 : 7|8@0+ (1,0) [0|255] ""  ICC
 SG_ BNCM_16_RollgCntr1 : 11|4@0+ (1,0) [0|14] ""  ICC
 SG_ BNCM_16_Resd1 : 15|4@0+ (1,0) [0|15] ""  ICC
 SG_ BNCM_16_CMD : 23|16@0+ (1,0) [0|65535] ""  ICC
 SG_ BNCM_16_PDU1 : 39|64@0+ (1,0) [0|1.84467440737096E+019] ""  ICC
 SG_ BNCM_16_PDU2 : 103|64@0+ (1,0) [0|1.84467440737096E+019] ""  ICC
 SG_ BNCM_16_PDU3 : 167|64@0+ (1,0) [0|1.84467440737096E+019] ""  ICC
 SG_ BNCM_16_PDU4 : 231|32@0+ (1,0) [0|4294967295] ""  ICC

BO_ 1095 RLCR_1: 8 CGW
 SG_ RLCR_1_CRC1 : 7|8@0+ (1,0) [0|255] ""  ICC
 SG_ RLCR_1_RollgCntr1 : 11|4@0+ (1,0) [0|14] ""  ICC
 SG_ RLCR_1_Resd1 : 15|4@0+ (1,0) [0|15] ""  ICC
 SG_ RLCR_1_SysSt : 17|2@0+ (1,0) [0|3] ""  ICC
 SG_ RLCR_1_BlkSts : 18|1@0+ (1,0) [0|1] ""  ICC
 SG_ RLCR_1_BSDWarn : 21|2@0+ (1,0) [0|3] ""  ICC
 SG_ RLCR_1_DOWWarn : 23|2@0+ (1,0) [0|3] ""  ICC
 SG_ RLCR_1_DowLock : 25|2@0+ (1,0) [0|3] ""  ICC
 SG_ RLCR_1_ELK_Collision_flag : 27|2@0+ (1,0) [0|3] ""  ICC
 SG_ RLCR_1_ELK_CollisionFlagValid : 29|2@0+ (1,0) [0|3] ""  ICC

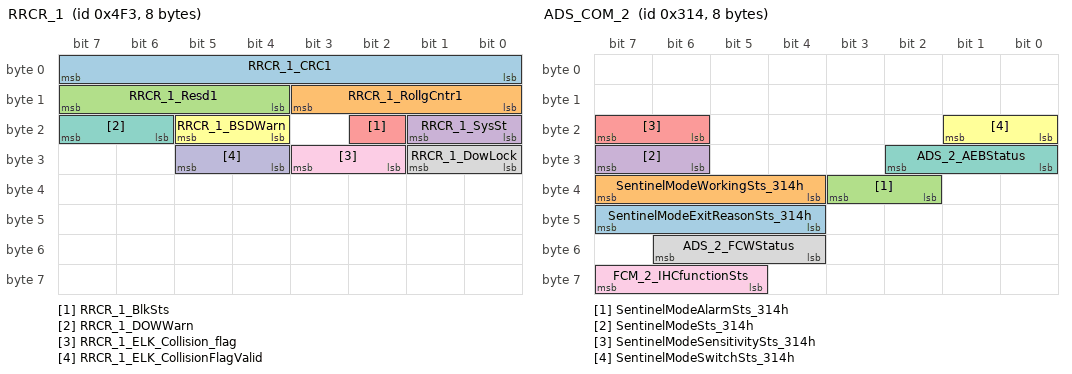
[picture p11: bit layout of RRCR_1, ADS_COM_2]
BO_ 1267 RRCR_1: 8 CGW
 SG_ RRCR_1_CRC1 : 7|8@0+ (1,0) [0|255] ""  ICC
 SG_ RRCR_1_RollgCntr1 : 11|4@0+ (1,0) [0|14] ""  ICC
 SG_ RRCR_1_Resd1 : 15|4@0+ (1,0) [0|15] ""  ICC
 SG_ RRCR_1_SysSt : 17|2@0+ (1,0) [0|3] ""  ICC
 SG_ RRCR_1_BlkSts : 18|1@0+ (1,0) [0|1] ""  ICC
 SG_ RRCR_1_BSDWarn : 21|2@0+ (1,0) [0|3] ""  ICC
 SG_ RRCR_1_DOWWarn : 23|2@0+ (1,0) [0|3] ""  ICC
 SG_ RRCR_1_DowLock : 25|2@0+ (1,0) [0|3] ""  ICC
 SG_ RRCR_1_ELK_Collision_flag : 27|2@0+ (1,0) [0|3] ""  ICC
 SG_ RRCR_1_ELK_CollisionFlagValid : 29|2@0+ (1,0) [0|3] ""  ICC

BO_ 788 ADS_COM_2: 8 CGW
 SG_ SentinelModeExitReasonSts_314h : 47|4@0+ (1,0) [0|15] ""  ICC
 SG_ SentinelModeWorkingSts_314h : 39|4@0+ (1,0) [0|15] ""  ICC
 SG_ SentinelModeAlarmSts_314h : 35|2@0+ (1,0) [0|3] ""  ICC
 SG_ SentinelModeSts_314h : 31|2@0+ (1,0) [0|3] ""  ICC
 SG_ SentinelModeSensitivitySts_314h : 23|2@0+ (1,0) [0|3] ""  ICC
 SG_ SentinelModeSwitchSts_314h : 17|2@0+ (1,0) [0|3] ""  ICC
 SG_ ADS_2_AEBStatus : 26|3@0+ (1,0) [0|6] ""  ICC
 SG_ ADS_2_FCWStatus : 54|3@0+ (1,0) [0|7] ""  ICC
 SG_ FCM_2_IHCfunctionSts : 63|3@0+ (1,0) [0|7] ""  ICC

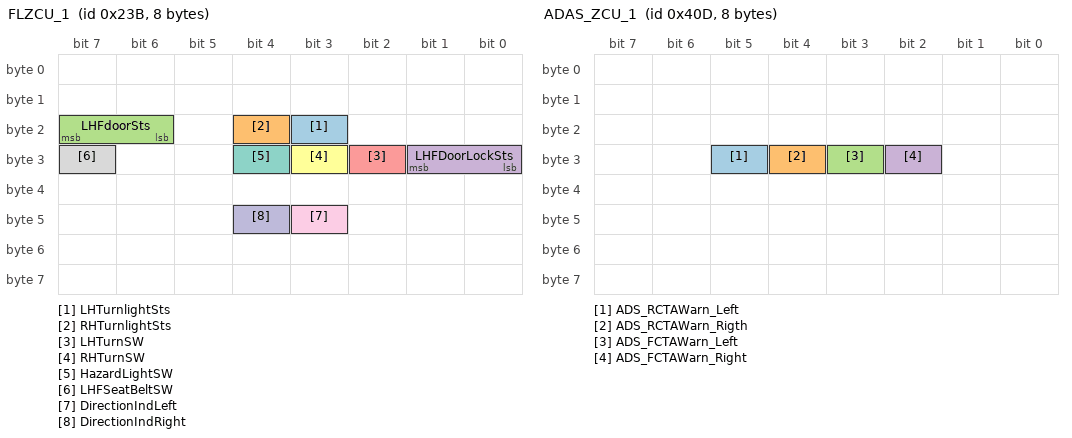
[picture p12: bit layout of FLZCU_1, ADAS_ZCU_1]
BO_ 571 FLZCU_1: 8 FLZCU_HCU_IC
 SG_ LHTurnlightSts : 19|1@0+ (1,0) [0|1] ""  ICC,DVR
 SG_ RHTurnlightSts : 20|1@0+ (1,0) [0|1] ""  ICC,DVR
 SG_ LHFdoorSts : 23|2@0+ (1,0) [0|3] ""  ICC,EPC,BBCM,CMSM
 SG_ LHFDoorLockSts : 25|2@0+ (1,0) [0|3] ""  ICC,EPC,BBCM
 SG_ LHTurnSW : 26|1@0+ (1,0) [0|1] ""  ICC
 SG_ RHTurnSW : 27|1@0+ (1,0) [0|1] ""  ICC
 SG_ HazardLightSW : 28|1@0+ (1,0) [0|1] ""  ICC
 SG_ LHFSeatBeltSW : 31|1@0+ (1,0) [0|1] ""  ICC
 SG_ DirectionIndLeft : 43|1@0+ (1,0) [0|1] ""  ICC
 SG_ DirectionIndRight : 44|1@0+ (1,0) [0|1] ""  ICC

BO_ 699 RZCU_2: 8 FLZCU_HCU_IC
 SG_ LHRdoorSts : 21|2@0+ (1,0) [0|3] ""  ICC,EPC,BBCM,CMSM

BO_ 787 FRZCU_14: 16 CGW
 SG_ ChrgHoodSts : 23|1@0+ (1,0) [0|1] ""  ICC
 SG_ FRZCU_FRSitPosnSts : 22|2@0+ (1,0) [0|3] ""  ICC

BO_ 524 ADS_6: 48 CGW
 SG_ New_Signal_20C_1 : 28|37@0+ (1,0) [0|137438953471] ""  ICC
 SG_ New_Signal_20C : 16|1@0+ (1,0) [0|0] ""  ICC
 SG_ ADS_6_CRC1 : 7|8@0+ (1,0) [0|255] ""  ICC
 SG_ ADS_6_RollgCntr1 : 11|4@0+ (1,0) [0|14] ""  ICC
 SG_ ADS_6_Resd1 : 15|4@0+ (1,0) [0|15] ""  ICC
 SG_ ADS_6_AVM_FuncSts : 23|2@0+ (1,0) [0|3] ""  ICC
 SG_ ADS_6_AVM_ButtonClick : 21|2@0+ (1,0) [0|1] ""  ICC
 SG_ ADS_6_Customize_buttonsFB : 19|3@0+ (1,0) [0|7] ""  ICC
 SG_ ADS_6_PAS_AudioTone : 31|3@0+ (1,0) [0|7] ""  ICC

BO_ 572 ONEBOX_7: 48 CGW
 SG_ ONEBOX_7_TAB_HighTemp : 49|1@0+ (1,0) [0|1] ""  ICC
 SG_ ONEBOX_7_TAB_Active : 51|2@0+ (1,0) [0|3] ""  ICC
 SG_ ONEBOX_7_BSW_Active : 60|2@0+ (1,0) [0|3] ""  ICC
 SG_ ONEBOX_7_iCCO_TgtVel : 151|8@0+ (0.1,0) [0|20] ""  ICC

BO_ 1212 VCU_3_G: 8 FLZCU_HCU_IC
 SG_ VCU_3_G_ActWheelTorqueFA : 23|16@0+ (1,-32768) [-32768|32767] "NM"  ICC
 SG_ VCU_3_G_ActWheelTorqueRA : 39|16@0+ (1,-32768) [-32768|32767] "NM"  ICC

BO_ 783 ADS_COM_1: 8 CGW
 SG_ ADCC_SysReadySts : 43|1@0+ (1,0) [0|1] ""  ICC

BO_ 1110 IMMO_ICC_11: 8 CGW
 SG_ IMMO_Chall_ICC : 7|64@0+ (1,0) [0|1.84467440737096E+019] ""  ICC

BO_ 1149 IMMO_VCC_12: 8 CGW
 SG_ IMMO_Teach_VCC : 7|64@0+ (1,0) [0|1.84467440737096E+019] ""  ICC

BO_ 1037 ADAS_ZCU_1: 8 CGW
 SG_ ADS_RCTAWarn_Left : 29|1@0+ (1,0) [0|1] ""  ICC
 SG_ ADS_RCTAWarn_Rigth : 28|1@0+ (1,0) [0|1] ""  ICC
 SG_ ADS_FCTAWarn_Left : 27|1@0+ (1,0) [0|1] ""  ICC
 SG_ ADS_FCTAWarn_Right : 26|1@0+ (1,0) [0|1] ""  ICC

BO_ 943 CSA_3: 32 CGW
 SG_ Fraxlebearingrate : 199|8@0+ (1,0) [0|100] "%"  ICC
 SG_ CSA_3_CRC1 : 7|8@0+ (1,0) [0|255] ""  ICC
 SG_ CSA_3_RollgCntr1 : 11|4@0+ (1,0) [0|14] ""  ICC
 SG_ CSA_3_Resd1 : 15|4@0+ (1,0) [0|15] ""  ICC
 SG_ FlwheelBearing : 23|12@0+ (0.001,0) [0|4.095] "t"  ICC
 SG_ FrwheelBearing : 27|12@0+ (0.001,0) [0|4.095] "t"  ICC
 SG_ BlwheelBearing : 47|12@0+ (0.001,0) [0|4.095] "t"  ICC
 SG_ BrwheelBearing : 51|12@0+ (0.001,0) [0|4.095] "t"  ICC
 SG_ CSA_3_CRC2 : 71|8@0+ (1,0) [0|255] ""  ICC
 SG_ CSA_3_RollgCntr2 : 75|4@0+ (1,0) [0|14] ""  ICC
 SG_ VehicleBearing_kg : 87|12@0+ (1,0) [0|4095] "kg"  ICC
 SG_ VehicleBearing_lb : 91|14@0+ (1,0) [0|16383] "lb"  ICC
 SG_ GoodsWeight_kg : 109|12@0+ (1,0) [0|4095] "kg"  ICC
 SG_ Goods_Weight_Ratio : 113|10@0+ (0.1,0) [0|100] "%"  ICC
 SG_ CSA_3_CRC3 : 135|8@0+ (1,0) [0|255] ""  ICC
 SG_ CSA_3_RollgCntr3 : 139|4@0+ (1,0) [0|14] ""  ICC
 SG_ CSA_3_Resd3 : 143|4@0+ (1,0) [0|15] ""  ICC
 SG_ GoodsWeight_lb : 151|14@0+ (1,0) [0|16383] "lb"  ICC
 SG_ OverWeightValue_kg : 153|12@0+ (1,0) [0|4095] "kg"  ICC
 SG_ OverWeightValue_lb : 173|14@0+ (1,0) [0|16383] "lb"  ICC
 SG_ OverWeightRatio : 191|3@0+ (1,0) [0|7] "%"  ICC
 SG_ OverWeightWarning : 188|1@0+ (1,0) [0|1] ""  ICC
 SG_ OverLoadWarnShieldSetFed : 187|2@0+ (1,0) [0|3] ""  ICC

BO_ 1120 FLZCU_3: 8 FLZCU_HCU_IC
 SG_ RLHS_2_AmbBrightness : 19|12@0+ (20,0) [0|81880] "Lux"  ICC
 SG_ RLHS_LiSwithReason : 49|2@0+ (1,0) [0|3] ""  ICC

BO_ 850 ASU_6: 32 CGW
 SG_ ASU_trekthrough_352h : 47|2@0+ (1,0) [0|3] ""  ICC
 SG_ ASU_undergroundmode_352h : 45|2@0+ (1,0) [0|3] ""  ICC
 SG_ ASU_inflate_352h : 43|2@0+ (1,0) [0|3] ""  ICC
 SG_ ASU_6_HMIFailFb_JT : 23|4@0+ (1,0) [0|15] ""  ICC

BO_ 1199 TCM_1: 8 CGW
 SG_ TCM_1_TrailerSts : 16|1@0+ (1,0) [0|1] ""  ICC

BO_TX_BU_ 571 : FLZCU_HCU_IC,FLZCU_IC,FLZCU_Signal_IC;
BO_TX_BU_ 699 : FLZCU_HCU_IC,FLZCU_IC,FLZCU_Signal_IC;
BO_TX_BU_ 787 : CGW,FRZCU;
BO_TX_BU_ 1212 : FLZCU_HCU_IC,HCU_IC;
BO_TX_BU_ 1120 : FLZCU_HCU_IC,FLZCU_IC,FLZCU_Signal_IC;
CM_ SG_ 1224 BMS_HvBattCellVoltMax_Num "highest voltage cell number";
CM_ SG_ 1224 BMS_HvBattCellVoltMax "highest cell voltage";
CM_ SG_ 1224 BMS_HvBattCellVoltMin_Num "lowest voltage cell number";
CM_ SG_ 1224 BMS_HvBattCellVoltMin "lowest cell voltage";
CM_ SG_ 1224 BMS_Chg_Sts "BMS_Chg_Sts";
CM_ SG_ 1235 EPS_2_Steer_ReturnRmd_Sts "Steer  wheeel return Sts(捷途D01）";
CM_ SG_ 1235 EPS_2_Steer_ReturnRmd "Steer  wheeel return remind(捷途D01）";
CM_ SG_ 1235 EPS_2_MFS_ShakeSts "方向盘震动反馈(捷途D01）";
CM_ SG_ 1330 DWD_TextDisp "报警提示内容";
CM_ SG_ 1330 DWD_SoundIndcn "报警声音提示";
CM_ SG_ 1330 LSensorFailSts "0x0：传感器正常
0x1：传感器故障";
CM_ SG_ 1330 RSensorFailSts "0x0：传感器正常
0x1：传感器故障";
CM_ SG_ 1330 DWD_Distance "报警距离分段";
CM_ SG_ 1330 DWD_Switch "涉水雷达开关状态";
CM_ SG_ 1328 RADAR_1_RadarDetectSts "雷达探测状态
当发01，IHU_以前探头音讯蜂鸣扬声器；
当发10，IHU_以后探头音讯蜂鸣扬声器
ICM_接收此信号，但前_后探头均用一种音讯蜂鸣。";
CM_ SG_ 1328 RADAR_1_RadarWorkSts "雷达系统工作状态
1、Active:当打开PAS_开关或打到倒文件，雷达模块开始工作，此时发1，
IHU_接收到后即便用户未打开IHU，也会通过此信号自动点亮屏幕；
2、Not_Active:当不在倒档且PAS_开关关闭，或者车速大于15km_h_时，发0(Not_Active)。
3、自检提示音:雷达工作状态位由0_变化为1_时，仪表根据探头状态信息发出相应提示音，如果探头有故障则长鸣2_秒提示探头故障，如果探头没有故障则鸣叫，0.5_秒提示雷达进入工作状态。";
CM_ SG_ 1328 RADAR_1_Resd1 "Profile1A:E2E Reserved";
CM_ SG_ 1328 RADAR_1_LHRRadarSensorDistance "左后探头信息
自检故障:发送Sensor_Err
自检正常或雷达待机:发送0x3
E正常测距:距离=(D)*5+25
无障碍物:发送0x3E
0x20~0x3D:无效数据";
CM_ SG_ 1328 RADAR_1_RHMRRadarSensorDistance "右中后探头信息
自检故障:发送Sensor_Err
自检正常或雷达待机:发送0x3
E正常测距:距离=(D)*5+25
无障碍物:发送0x3E
0x20~0x3D:无效数据";
CM_ SG_ 1328 RADAR_1_LHMRRadarSensorDistance "左中后探头信息
自检故障:发送Sensor_Err
自检正常或雷达待机:发送0x3
E正常测距:距离=(D)*5+25
无障碍物:发送0x3E
0x20~0x3D:无效数据";
CM_ SG_ 1328 RADAR_1_RHRRadarSensorDistance "右后探头信息
自检故障:发送Sensor_Err
自检正常或雷达待机:发送0x3
E正常测距:距离=(D)*5+25
无障碍物:发送0x3E
0x20~0x3D:无效数据";
CM_ SG_ 1328 RADAR_1_LHFRadarSensorDistance "左前探头信息
自检故障:发送Sensor_Err
自检正常或雷达待机:发送0x3
E正常测距:距离=(D)*5+25
无障碍物:发送0x1E
0x20~0x3D:无效数据";
CM_ SG_ 1328 RADAR_1_RHFRadarSensorDistance "右前探头信息
自检故障:发送Sensor_Err
自检正常或雷达待机:发送0x3
E正常测距:距离=(D)*5+25
无障碍物:发送0x1E
0x20~0x3D:无效数据";
CM_ SG_ 1328 RADAR_1_RHMFRadarSensorDistance "右中前探头信息
自检故障:发送Sensor_Err
自检正常或雷达待机:发送0x1E
正常测距:距离=(D)*5+25
无障碍物:发送0x1E
低配雷达(后4_探头):发送0x1E
0x1C~0x1D:无效数据";
CM_ SG_ 1328 RADAR_1_LHMFRadarSensorDistance "左中前探头信息
自检故障:发送Sensor_Err
自检正常或雷达待机:发送0x1E
正常测距:距离=(D)*5+25
无障碍物:发送0x1E
低配雷达(后4_探头):发送0x1E
0x1C~0x1D:无效数据";
CM_ SG_ 1328 RADAR_1_AudibleBeepRate "报警频率
1、自检过程或雷达待机时发送Startup
2、进入测距模式后:发送频率信息
3、自检提示音见
RadarWorkSts_详细说明";
CM_ SG_ 259 EMS_EngineSpeed_Actual "PHEV:Actual Engine speed send by EMS to HCU";
CM_ SG_ 1234 FRZCU_FRSeatHeiFb "副驾座椅高度调节目标位置";
CM_ SG_ 1234 FRZCU_FRSeatLvlFb "副驾座椅水平调节目标值";
CM_ SG_ 1234 FRZCU_FRSeatBackAgFb "副驾座椅靠背角度调节目标值";
CM_ SG_ 1234 FRZCU_FRSeatLegSpprtFb "副驾座椅腿托";
CM_ SG_ 1234 FRZCU_FRWinSts "右前车窗运行状态反馈";
CM_ SG_ 1234 FRZCU_RRWinSts "右后车窗运行状态反馈";
CM_ SG_ 1234 FRZCU_FRSeatLegRestAngleFb "副驾座椅腿托延伸调节目标";
CM_ SG_ 1234 FRZCU_FRSeatCushFb "副驾座椅坐垫角度调节目标";
CM_ SG_ 1234 FRZCU_FRSeatNeedMemory "副驾座椅记忆弹框请求";
CM_ SG_ 1234 FRZCU_FRMemoryFb "副驾记忆保存状态";
CM_ SG_ 1234 FRZCU_FRRecoverFb "副驾记忆恢复状态";
CM_ SG_ 1234 FRZCU_EasyEntryExitFb "副驾便捷进入\离车";
CM_ SG_ 1234 FRZCU_EnjoyableSeatWarning "一键尊享警示提示";
CM_ SG_ 1234 FRZCU_EnjoyableSeatSts "一键尊享状态反馈";
CM_ SG_ 1234 SeatHeatLevelsFR "座椅加热-副驾";
CM_ SG_ 1234 SeatVentLevelsFR "座椅通风-副驾";
CM_ SG_ 1234 SeatHeatLevelsRR "座椅加热-二排右侧";
CM_ SG_ 1234 SeatVentLevelsRR "座椅通风-二排右侧";
CM_ SG_ 1234 FRZCU_FRSeatFoldFb "副驾座椅放倒调节目标";
CM_ SG_ 517 MFSR_Voice_SW "语音唤醒";
CM_ SG_ 1096 TMS_AirPurgeReminderSts "空气净化提醒开关状态";
CM_ SG_ 1096 TMS_BT_Reduce_Wind_SpeedSts "蓝牙通话降低风速状态";
CM_ SG_ 1096 TMS_First_BlowingSts "空调启动时第一口风状态";
CM_ SG_ 1096 TMS_CirculationInTunnelsSts "隧道内循环状态";
CM_ SG_ 1096 TMS_crosscountry_coolingSts "越野散热状态";
CM_ SG_ 1096 TMS_ParkingAirConditioningStatus "驻车空调状态工作状态";
CM_ SG_ 1096 TMS_CoolantFillSts "一键除气";
CM_ SG_ 1096 TMS_UVC_ControlSts "UVC控制反馈";
CM_ SG_ 1096 TMS_UVC_LuminanceSts "UVC亮度反馈";
CM_ SG_ 1096 TMS_ICC_Lightoff_Sts "香氛氛围灯开关状态";
CM_ SG_ 1096 TMS_ICC_Memoff_Sts "香氛记忆开关状态";
CM_ SG_ 1096 TMS_keepwarmSet_TemperatureSts "恒温模式温度设置";
CM_ SG_ 1096 TMS_BiochemicalFuncSts "生化功能开关反馈";
CM_ SG_ 1096 TMS_TimedVentilationSts "大屏定时换气开关状态反馈";
CM_ SG_ 1240 TMS_CFSSwitchFb "香氛系统开关设置反馈";
CM_ SG_ 1240 TDU_CFSPosOneType "香氛位置1香型";
CM_ SG_ 1240 TDU_CFSPosTwoType "香氛位置2香型";
CM_ SG_ 1240 TDU_CFSPosThreeType "香氛位置3香型";
CM_ SG_ 1240 TDU_CFSRunOut "香氛已用完提醒";
CM_ SG_ 1240 TMS_CFSShortWarn "香氛不足提醒";
CM_ SG_ 1240 TMS_CFSLevelSetFb "香氛工作浓度";
CM_ SG_ 1240 TMS_CFSPosSetFb "香氛工作位置反馈";
CM_ SG_ 1240 TMS_CFSPosOneLife "通道一香氛寿命";
CM_ SG_ 1240 TMS_CFSPosTwoLife "通道二香氛寿命";
CM_ SG_ 1240 TMS_CFSPosThreeLife "通道三香氛寿命";
CM_ SG_ 1240 TMS_PM25SwitchFb "PM2.5状态反馈";
CM_ SG_ 1240 TMS_ThrModeStsFb "三排模式反馈";
CM_ SG_ 1240 TMS_ThrSetTempFb_C "三排温度反馈";
CM_ SG_ 1240 TMS_ThrCLMSwitchFb "三排空调状态反馈";
CM_ SG_ 1240 TMS_ThrAutoSwitchFb "空调自动状态显示";
CM_ SG_ 1240 TMS_ThrBlowSpeedLevelKeyStsFb "三排鼓风机档位";
CM_ SG_ 638 FRZCU_HoodSts "前舱盖状态";
CM_ SG_ 638 FRZCU_PowerMode "低压电源状态";
CM_ SG_ 638 SeatLength_target_Passenger "座椅水平位置调节";
CM_ SG_ 638 SeatBackrest_target_Passenger "座椅靠背角度调节";
CM_ SG_ 638 FrontBackSpeedAdj_Cmd "Front_Back_Speed_Adjust_Command
座椅前后调节速度信号";
CM_ SG_ 638 FRZCU_GloveboxSW "上报手套箱开关状态";
CM_ SG_ 638 FRZCU_FRReleaseLockSts "右前电释放状态
0x0:None
0x1:已释放
0x2:释放中
0x3:已复位
0x4:复位中";
CM_ SG_ 638 FRZCU_RRReleaseLockSts "右后电释放状态
0x0:None
0x1:已释放
0x2:释放中
0x3:已复位
0x4:复位中";
CM_ SG_ 638 FRZCU_PELockInKeyWarning "PE闭锁车内有钥匙提醒";
CM_ SG_ 638 FRZCU_PowerOFFWarning "电源下电提醒";
CM_ SG_ 638 FRZCU_KeylessWarning "无合法钥匙提醒";
CM_ SG_ 638 FRZCU_OTAPwrDwnReqFb "OTA_Power_Down_Request_FeedBack";
CM_ SG_ 638 FRZCU_OTAPwrOnReqFb "OTA_Power_On_Request_FeedBack";
CM_ SG_ 949 PEPS_InformationSource "To_show_the_lock/unlock_information_is_from_Smart_or_RKE_.";
CM_ SG_ 949 PEPS_OrderInformation "PEPS_do_not_add_any_additional_logic._Just_reflect_the_status_of_the_switch_state.";
CM_ SG_ 949 PEPS_KeySts "PEPS钥匙位置状态";
CM_ SG_ 949 PEPS_ETRUnLockReq "尾门靠近解锁请求";
CM_ SG_ 1028 PEPS_WelcomeON "welcome_light_request
迎宾开启请求";
CM_ SG_ 1028 PEPS_VehicleSearchReq "寻车请VehicleSearchRequest
寻车请求";
CM_ SG_ 1028 PEPS_SATOReminder "Easy_trunk_function_start_light
进入后备箱区域激活ETR功能闪灯信号";
CM_ SG_ 1028 PEPS_PLGUnlockReq "PLG解锁指令";
CM_ SG_ 1028 PEPS_RKETrunkSts "实体钥匙尾门按键";
CM_ SG_ 1028 PEPS_SSBInhibitCWCSts "OFF档时点按SSB，发送1值。
OFF档，CWC接收到SSBInhibitCWCSts=1后屏蔽无线充电功能；";
CM_ SG_ 1028 PEPS_WirelessChargingCtrSts "发送1时，PEPS处于搜索遥控钥匙的状态，无线充电功能应关闭";
CM_ SG_ 1028 PEPS_EmgyShutdown "Emergency_shut_down._If_happen_,Send_three_frame_continuous_signal_1
此信号代表发生过紧急熄火功能。如果没发生都是发0，如果发生了，连续发3帧1出来。";
CM_ SG_ 1028 PEPS_SSBInputFailure "The_warning_indicator_the_SSB_is_faulty";
CM_ SG_ 1028 PEPS_SmartSystemWarning1_1 "非OFF档关门钥匙不在车内报警";
CM_ SG_ 1028 PEPS_SmartSystemWarning2_2 "车速无钥匙报警";
CM_ SG_ 1028 PEPS_SmartSystemWarning3_1 "钥匙电池电量低报警";
CM_ SG_ 1028 PEPS_SmartSystemWarning3_2 "用于SSB启动时，非P档时启动报警";
CM_ SG_ 1028 PEPS_SmartSystemWarning4_2 "用于SSB启动时，未踩刹车提醒报警";
CM_ SG_ 1028 PEPS_SmartSystemWarning4_3 "下电不在P档报警";
CM_ SG_ 1028 PEPS_SystemWarning "PEPS系统故障提醒";
CM_ SG_ 1028 PEPS_BLTKeyPESts "蓝牙钥匙的PE功能开启关闭状态信号";
CM_ SG_ 1291 BMS_2_G_CRC "Profile1A:E2E CRC (SAE J1850 CRC-8) for 8 Bytes
DataID:0x0075";
CM_ SG_ 1291 BMS_2_G_RollgCntr "Profile1A:E2E Rolling message counter(the maximum value of Alive counter is 14)";
CM_ SG_ 1291 BMS_2_G_Resd "Profile1A:E2E Reserved";
CM_ SG_ 1291 BMS_TBOXInsulation_R "insulation resistance";
CM_ SG_ 1291 BMS_TBOXErrorNumber "BMS Error Numbers";
CM_ SG_ 1291 BMS_TBOXHvBattMaxT "battery max temperature";
CM_ SG_ 1291 BMS_TBOXHvBattMinT "battery min temperature";
CM_ SG_ 1291 BMS_SOCLight "BMS_SOCLight
SOC电量显示（仪表显示）";
CM_ SG_ 1104 RLCR_2_CRC1 "Profile1A:E2E CRC (SAE J1850 CRC-8) for 8 Bytes
DataID:0x0045";
CM_ SG_ 1104 RLCR_2_RollgCntr1 "Profile1A:E2E Rolling message counter(the maximum value of Alive counter is 14)";
CM_ SG_ 1104 RLCR_2_Resd1 "Profile1A:E2E Reserved";
CM_ SG_ 1104 RLCR_2_RCWWarn "Rear Collision Warning Warning";
CM_ SG_ 1104 RLCR_2_RCTAWarn "RCTA Warning（高配不发）";
CM_ SG_ 1104 RLCR_2_BSDLCWONOFFSts "BSD/LCA Switch status";
CM_ SG_ 1104 RLCR_2_DOWONOFFSts "Door open warning Switch status";
CM_ SG_ 1104 RLCR_2_RCWONOFFSts "Rear Collision Warning Switch Status";
CM_ SG_ 1104 RLCR_2_RCTARCTBONOFFSts "RCTA/RCTB Switch status（高配不发，低配无0x2）";
CM_ SG_ 1271 RRCR_2_CRC1 "Profile1A:E2E CRC (SAE J1850 CRC-8) for 8 Bytes
DataID:0x0047";
CM_ SG_ 1271 RRCR_2_RollgCntr1 "Profile1A:E2E Rolling message counter(the maximum value of Alive counter is 14)";
CM_ SG_ 1271 RRCR_2_Resd1 "Profile1A:E2E Reserved";
CM_ SG_ 1271 RRCR_2_RCWWarn "Rear Collision Warning Warning";
CM_ SG_ 1271 RRCR_2_RCTAWarn "FCTA Warning";
CM_ SG_ 1271 RRCR_2_BSDLCWONOFFSts "BSD/LCA Switch status";
CM_ SG_ 1271 RRCR_2_DOWONOFFSts "Door open warning Switch status";
CM_ SG_ 1271 RRCR_2_RCWONOFFSts "Rear Collision Warning Switch Status";
CM_ SG_ 1271 RRCR_2_RCTARCTBONOFFSts "RCTA/RCTB Switch status";
CM_ SG_ 587 ONEBOX_4_LHFWheelSpeedRPM "left front Wheel Speed(the unit is RPM)";
CM_ SG_ 587 ONEBOX_4_RHFWheelSpeedRPM "right front  Wheel Speed(the unit is RPM)";
CM_ SG_ 587 LHRWheelSpeedRPM "Left Rear Wheel Speed(the unit is RPM)";
CM_ SG_ 587 RHRWheelSpeedRPM "right Rear  Wheel Speed(the unit is RPM)";
CM_ SG_ 587 LHRPulseCounterFailSts "left rear wheel Pulse Counter Fail Status";
CM_ SG_ 587 LHRPulseCounter "left rear wheel Pulse Counter";
CM_ SG_ 587 RHRPulseCounterFailSts "right rear wheel Pulse Counter FailSts";
CM_ SG_ 587 RHRPulseCounter "right rear wheel Pulse Counter";
CM_ SG_ 587 RHFPulseCounterFailSts "right front wheel Pulse Counter FailSts";
CM_ SG_ 587 RHFPulseCounter "right front wheel Pulse Counter";
CM_ SG_ 587 LHFPulseCounterFailSts "left front wheel Pulse Counter FailSts";
CM_ SG_ 587 LHFPulseCounter "left front wheel Pulse Counter";
CM_ SG_ 587 LHFWheelDriveDirection "left front Wheel Drive Direction";
CM_ SG_ 587 RHFWheelDriveDirection "right front Wheel Speed Drive Direction";
CM_ SG_ 587 LHRWheelDriveDirection "left rear Wheel Speed Drive Direction";
CM_ SG_ 587 RHRWheelDriveDirection "right rear Wheel Speed Drive Direction";
CM_ SG_ 1338 FMCU_ErrLvlDis "Error Level";
CM_ SG_ 1338 FMCU_SpdAct_EDR "FMCU motor actual speed";
CM_ SG_ 777 ISGF_ErrLvl "Error Level";
CM_ SG_ 1403 RMCU_ErrLvlDis "Error Level";
CM_ SG_ 1403 RMCU_Speed_EDR "RMCU motor actual speed";
CM_ SG_ 1299 BMS_PackVoltageDis "Battery Voltage（高压后的表显电压，不上高压发0）";
CM_ SG_ 1299 BMS_PackCurrentDis "Battery Current(direction:discharge+ charge -)";
CM_ SG_ 1099 ISGF_SysTempOvrInd "Indicator of overheat warning lamp（捷途D01不使用）";
CM_ SG_ 1130 TCU_23_GBFaultstatus "Activation gearbox error Lamp, only for ICM including LCD to light LED and LCD. This signal should be sent with “AGErrorLamp” simultaneously";
CM_ SG_ 1130 TCU_23_TeachInState "TCU自学习状态";
CM_ SG_ 1180 ACU_1_ThdRowLBeltWarning "With Occupancy detection：
Third row (left) safety belt status
0x0:not occupied/occupied and fastened
0x1:occupied and not fastened 
Without Occupancy detection：
0x0:Seat belt is fastened
0x1:Seat belt is not fastened";
CM_ SG_ 1180 ACU_1_ThdRowRBeltWarning "With Occupancy detection：
Third row (right) safety belt status
0x0:not occupied/occupied and fastened
0x1:occupied and not fastened 
Without Occupancy detection：
0x0:Seat belt is fastened
0x1:Seat belt is not fastened";
CM_ SG_ 1180 ACU_1_PsngrSeatBeltWarning "In addition to the corresponding value sent by ACU with copilot safety belt alarm, the signal sent by ACU without alarm configuration sends the startup value.
The signal is judged in combination with SBR";
CM_ SG_ 1180 ACU_1_SecRowLBeltWarning "With Occupancy detection：
Second row (left) safety belt status
0x0:not occupied/occupied and fastened
0x1:occupied and not fastened 
Without Occupancy detection：
0x0:Seat belt is fastened
0x1:Seat belt is not fastened";
CM_ SG_ 1180 ACU_1_SecRowMBeltWarning "With Occupancy detection：
Second row (middle) safety belt status
0x0:not occupied/occupied and fastened
0x1:occupied and not fastened 
Without Occupancy detection：
0x0:Seat belt is fastened
0x1:Seat belt is not fastened";
CM_ SG_ 1180 ACU_1_SecRowRBeltWarning "With Occupancy detection：
Second row (right) safety belt status
0x0:not occupied/occupied and fastened
0x1:occupied and not fastened 
Without Occupancy detection：
0x0:Seat belt is fastened
0x1:Seat belt is not fastened";
CM_ SG_ 1180 ACU_1_PsngrSeatOccupiedSts "副驾座椅占位状态，0为未占位，1为占位
E03：国内\国际非欧盟一、二阶段都体现，类欧盟\欧盟不分阶段都体现；
E0Y：国内\国际非欧盟，类欧盟\欧盟都体现；
0x2:open circuit (03仅欧盟、类欧盟做，0Y都做)
0x3:short circuit (03仅欧盟、类欧盟做，0Y都做)";
CM_ SG_ 1341 BMS_44_PackPowerRealTime "捷途新增动力电池包实时功率";
CM_ SG_ 811 BMS_Chg_Sts "BMS_Chg_Sts";
CM_ SG_ 1269 LISDShowCMDSts "ISD灯光开启状态";
CM_ SG_ 1269 LISDShowModeSts "ISD灯光模式状态";
CM_ SG_ 1269 LISD_TransmitStatus "灯具反馈信息：反馈当前数据帧是否接收成功、数据校验是否正确、图片显示是否成功。";
CM_ SG_ 1269 LISD_DisplayStatus "灯具反馈信息：反馈当前图片显示状态。";
CM_ SG_ 1269 LISD_ParkingShowModSts "LISD驻车动画状态反馈";
CM_ SG_ 1269 LISD_ParkingShowCMDSts "驻车动画开关反馈";
CM_ SG_ 1233 RISDShowCMDSts "ISD灯光开启状态";
CM_ SG_ 1233 RISDShowModeSts "ISD灯光模式状态";
CM_ SG_ 1233 RISD_TransmitStatus "灯具反馈信息：反馈当前数据帧是否接收成功、数据校验是否正确、图片显示是否成功。";
CM_ SG_ 1233 RISD_DisplayStatus "灯具反馈信息：反馈当前图片显示状态。";
CM_ SG_ 1233 RISD_ParkingShowModSts "RISD驻车动画状态反馈";
CM_ SG_ 1233 RISD_ParkingShowCMDSts "驻车动画开关反馈";
CM_ SG_ 1169 LC_DIYMusicShowModSts "固定灯光秀状态反馈信号";
CM_ SG_ 1169 LC_RandomMusicShowSts "随机灯光秀状态反馈信号";
CM_ SG_ 1169 LC_LiShowModSts "解闭锁模式状态反馈信号";
CM_ SG_ 1427 ILCF_1_LogoParkingSts "前LOGO驻车点亮开关状态反馈";
CM_ SG_ 1427 ILCF_1_LogoChargingSts "前LOGO充电灯效开关状态反馈";
CM_ SG_ 1427 ILCF_1_DIYMusicShowModSts "固定灯光秀状态反馈信号";
CM_ SG_ 1427 ILCF_1_RandomMusicShowSts "随机灯光秀状态反馈信号";
CM_ SG_ 1427 ILCF_1_LogoColorAdjSts "Logo灯颜色设置反馈，1-256分别对应256种颜色";
CM_ SG_ 821 ADS_5_CRC1 "Profile1A:E2E CRC (SAE J1850 CRC-8) for 8 Bytes
DataID:No ASIL requirements.Not configure
CRC Reserved.";
CM_ SG_ 821 ADS_5_RollgCntr1 "Profile1A:E2E Rolling message counter(the maximum value of Alive counter is 14)";
CM_ SG_ 821 ADS_5_Resd1 "Profile1A:E2E Reserved";
CM_ SG_ 821 ADS_5_ILOASts "智慧躲闪功能执行状态";
CM_ SG_ 821 ADS_5_ICAQuitReason "ICA 退出原因";
CM_ SG_ 821 ADS_5_ISLISt "超速报警功能状态";
CM_ SG_ 821 ADS_5_ILOATextInfo "智慧躲闪提示信息";
CM_ SG_ 821 ADS_5_ILOAActdirection "智慧躲闪方向";
CM_ SG_ 821 ADS_5_LKS_warning "LKS声音报警信号";
CM_ SG_ 821 ADS_5_ISLIOverSpeedWarn "超速报警状态";
CM_ SG_ 821 ADS_5_ISLISpeedLimitSign "限速标志值";
CM_ SG_ 821 ADS_5_EgoLeftLineHeatgAg "自车中心线与本车道
 车道线的夹角";
CM_ SG_ 821 ADS_5_EgoLeLineID "左侧车道线有效信号";
CM_ SG_ 821 ADS_5_EgoLeLineColor "本车道左侧车道线颜色";
CM_ SG_ 821 ADS_5_EgoLeLineTyp "本车道左侧车道线类型";
CM_ SG_ 821 ADS_5_EgoLeLineHozlDst "自车中心线与本车道左侧车道线横向距离";
CM_ SG_ 821 ADS_5_CRC2 "Profile1A:E2E CRC (SAE J1850 CRC-8) for 8 Bytes
DataID:No ASIL requirements.Not configure
CRC Reserved.";
CM_ SG_ 821 ADS_5_RollgCntr2 "Profile1A:E2E Rolling message counter(the maximum value of Alive counter is 14)";
CM_ SG_ 821 ADS_5_Resd2 "Profile1A:E2E Reserved";
CM_ SG_ 821 ADS_5_NeborLeLineID "左侧相邻车道线有效信号";
CM_ SG_ 821 ADS_5_NeborLeLineColor "左侧相邻车道线颜色";
CM_ SG_ 821 ADS_5_NeborLeLineTyp "左侧相邻车道线类型";
CM_ SG_ 821 ADS_5_EgoLeLineCrvt "本车道左侧车道线曲率";
CM_ SG_ 821 ADS_5_NeborLeLineHozlDst "自车中心线与左侧相邻车 
 道线横向距离";
CM_ SG_ 821 ADS_5_NeborRiLineID "右侧相邻车道线有效信号";
CM_ SG_ 821 ADS_5_NeborRiLineColor "右侧相邻车道线颜色";
CM_ SG_ 821 ADS_5_NeborRiLineTyp "右侧相邻车道线类型";
CM_ SG_ 821 ADS_5_NeborLeLineCrvt "左侧相邻车道线曲率";
CM_ SG_ 821 ADS_5_NeborRiLineHozlDst "自车中心线与右侧相邻车 
 道线横向距离";
CM_ SG_ 821 ADS_5_CRC3 "Profile1A:E2E CRC (SAE J1850 CRC-8) for 8 Bytes
DataID:No ASIL requirements.Not configure
CRC Reserved.";
CM_ SG_ 821 ADS_5_RollgCntr3 "Profile1A:E2E Rolling message counter(the maximum value of Alive counter is 14)";
CM_ SG_ 821 ADS_5_Resd3 "Profile1A:E2E Reserved";
CM_ SG_ 821 ADS_5_ELKSettingSt "ELK功能设置状态反馈";
CM_ SG_ 821 ADS_5_LDWLDPSnvtySet "车道偏离敏感度反馈";
CM_ SG_ 821 ADS_5_LDWWarnType "LDW/LDP报警方式反馈";
CM_ SG_ 821 ADS_5_NeborRiLineCrvt "右侧相邻车道线曲率";
CM_ SG_ 821 ADS_5_IESSwtSet "智慧躲闪反馈开关（预留默认开）";
CM_ SG_ 821 ADS_5_IHCSettingSt "智能远光辅助开关反馈";
CM_ SG_ 821 ADS_5_ISLIWarningMod "智能限速提醒方式反馈";
CM_ SG_ 821 ADS_5_ICAEnableBtnSts "ICA功能使能开关反馈（车道居中辅助）";
CM_ SG_ 821 ADS_5_EgoRiLineID "右侧车道线有效信号";
CM_ SG_ 821 ADS_5_EgoRiLineTyp "本车道右侧车道线类型";
CM_ SG_ 821 ADS_5_EgoRiLineColor "本车道右侧车道线颜色";
CM_ SG_ 821 ADS_5_EgoRiLineHozlDst "自车中心线与本车道右侧车道线横向距离";
CM_ SG_ 821 ADS_5_CRC4 "Profile1A:E2E CRC (SAE J1850 CRC-8) for 8 Bytes
DataID:No ASIL requirements.Not configure
CRC Reserved.";
CM_ SG_ 821 ADS_5_RollgCntr4 "Profile1A:E2E Rolling message counter(the maximum value of Alive counter is 14)";
CM_ SG_ 821 ADS_5_Resd4 "Profile1A:E2E Reserved";
CM_ SG_ 821 ADS_5_EgoRightLineHeatgAg "自车中心线与本车道右侧车道线的夹角";
CM_ SG_ 821 ADS_5_EgoRiLineCrvt "本车道右侧车道线曲率";
CM_ SG_ 821 ADS_5_NeborLeftLineHeatgAg "自车中心线与相邻车道左侧车道线的夹角";
CM_ SG_ 821 ADS_5_NeborRightLineHeatgAg "自车中心线与相邻车道右侧车道线的夹角";
CM_ SG_ 819 ADS_4_CRC1 "Profile1A:E2E CRC (SAE J1850 CRC-8) for 8 Bytes
DataID:No ASIL requirements.Not configure
CRC Reserved.";
CM_ SG_ 819 ADS_4_RollgCntr1 "Profile1A:E2E Rolling message counter(the maximum value of Alive counter is 14)";
CM_ SG_ 819 ADS_4_Resd1 "Profile1A:E2E Reserved";
CM_ SG_ 819 ADS_4_AEBStatus "AEB功能状态";
CM_ SG_ 819 ADS_4_ACCSts "ACC功能状态";
CM_ SG_ 819 ADS_4_TimeGapSet "跟车时距";
CM_ SG_ 819 ADS_4_FcwMode "FCW功能状态";
CM_ SG_ 819 ADS_4_AEBReqType "AEB请求类型";
CM_ SG_ 819 ADS_4_SetSpd "巡航车速";
CM_ SG_ 819 ADS_4_DAIStatus "起步提醒功能状态";
CM_ SG_ 819 ADS_4_ACCTextMessage "ACC提示信息";
CM_ SG_ 819 ADS_4_LongiTakeOverReq "接管请求";
CM_ SG_ 819 ADS_4_SetSpdUnit "巡航车速单位";
CM_ SG_ 819 ADS_4_GoNotifier "起步提醒文言";
CM_ SG_ 819 ADS_4_DAISts "起步提醒功能执行状态";
CM_ SG_ 819 ADS_4_Radar_textinfo "雷达提示信息";
CM_ SG_ 819 ADS_4_SCF_PopoverReq "智能限速辅助弹窗提醒";
CM_ SG_ 819 ADS_4_DrvrCfmSCFDispFb "SCF 驾驶员确认信号 （确认后，setspeed变为摄像头限速值）";
CM_ SG_ 819 ADS_4_SCF_SpdLimUnit "智能限速辅助单位";
CM_ SG_ 819 ADS_4_SCF_SpdLimSts "智能限速辅助功能状态";
CM_ SG_ 819 ADS_4_CRC2 "Profile1A:E2E CRC (SAE J1850 CRC-8) for 8 Bytes
DataID:No ASIL requirements.Not configure
CRC Reserved.";
CM_ SG_ 819 ADS_4_RollgCntr2 "Profile1A:E2E Rolling message counter(the maximum value of Alive counter is 14)";
CM_ SG_ 819 ADS_4_Resd2 "Profile1A:E2E Reserved";
CM_ SG_ 819 ADS_4_ACCObjTyp "跟车目标类型";
CM_ SG_ 819 ADS_4_FrntFarObjTyp "前前车目标类型";
CM_ SG_ 819 ADS_4_ACCObjLgtDstX "跟车目标纵向距离";
CM_ SG_ 819 ADS_4_FrntFarObjID "前前车有效性";
CM_ SG_ 819 ADS_4_ACCObjID "跟车目标有效性";
CM_ SG_ 819 ADS_4_ACCObjHozDstY "跟车目标横向距离";
CM_ SG_ 819 ADS_4_FrntFarObjHozDstY "前前车横向距离";
CM_ SG_ 819 ADS_4_FrntFarObjLgtDstX "前前车纵向距离";
CM_ SG_ 819 ADS_4_CRC3 "Profile1A:E2E CRC (SAE J1850 CRC-8) for 8 Bytes
DataID:No ASIL requirements.Not configure
CRC Reserved.";
CM_ SG_ 819 ADS_4_RollgCntr3 "Profile1A:E2E Rolling message counter(the maximum value of Alive counter is 14)";
CM_ SG_ 819 ADS_4_Resd3 "Profile1A:E2E Reserved";
CM_ SG_ 819 ADS_4_LeObjID "左边车辆类型有效性";
CM_ SG_ 819 ADS_4_LeObjTyp "左边车辆类型";
CM_ SG_ 819 ADS_4_LeObjHozDstY "左边车辆横向距离";
CM_ SG_ 819 ADS_4_LeObjLgtDstX "左边车辆纵向距离";
CM_ SG_ 819 ADS_4_RiObjID "右边车辆类型有效性";
CM_ SG_ 819 ADS_4_RiObjTyp "右边车辆类型";
CM_ SG_ 819 ADS_4_RiObjHozDstY "右边车辆横向距离";
CM_ SG_ 819 ADS_4_RiObjLgtDstX "右边车辆纵向距离";
CM_ SG_ 819 ADS_4_CRC4 "Profile1A:E2E CRC (SAE J1850 CRC-8) for 8 Bytes
DataID:No ASIL requirements.Not configure
CRC Reserved.";
CM_ SG_ 819 ADS_4_RollgCntr4 "Profile1A:E2E Rolling message counter(the maximum value of Alive counter is 14)";
CM_ SG_ 819 ADS_4_Resd4 "Profile1A:E2E Reserved";
CM_ SG_ 819 ADS_4_SCFSwtSet "智能限速辅助反馈开关（预留默认开）";
CM_ SG_ 819 ADS_4_AEBSettingSt "AEB功能设置状态反馈";
CM_ SG_ 819 ADS_4_FCWSettingSt "FCW功能设置状态反馈";
CM_ SG_ 819 ADS_4_DAISwtSet "驶离提醒开关（预留默认开）";
CM_ SG_ 819 ADS_4_CruiseAccelerateSts "巡航跟车加减速状态指示，低配用于HMI显示";
CM_ SG_ 1172 ExternalTemperature_F "External_temperature（F）（外部温度（华氏度））";
CM_ SG_ 1172 ExternalTemperature_C "External_temperature（℃）
Invalid:_When_external_temperature_is_fail,_the_signal_value_is_0xFE.";
CM_ SG_ 1172 BlowSpeedLevelDisplaySts "Blow_Speed_Level_feedback
鼓风机档位
0xB:Auto后面要加这个属性";
CM_ SG_ 1147 CCP_1_FLTempSwitchReq "按下触摸到抬起一次，20ms信号有效的时候连发3帧，后期周期间隔100ms，按照当前状态发送";
CM_ SG_ 1147 CCP_1_FrontAutoACSwitchReq "前排自动功能";
CM_ SG_ 1147 CCP_1_FrontOFFSwitchReq "前排空调关闭";
CM_ SG_ 1147 CCP_1_FBlowSpdCtrlSwitchReq "前排风速";
CM_ SG_ 1147 FLCCP_MainSetHeatReq "主驾座椅加热";
CM_ SG_ 1147 FLCCP_MainSetVentilationReq "主驾座椅通风";
CM_ SG_ 1147 CCP_1_ACFastCool "一键制冷请求";
CM_ SG_ 1107 TMS_CCP_FLTempSts "前排左侧温度设置";
CM_ SG_ 1107 TMS_CCP_FrontAutoACSts "前排自动功能";
CM_ SG_ 1107 TMS_CCP_ACStatus "ACStatus
AC_状态";
CM_ SG_ 1107 TMS_CCP_FrontOFFSts "空调关闭";
CM_ SG_ 1107 TMS_CCP_FBlowSpdCtrlSts "前排风速设置";
CM_ SG_ 1107 TMS_CCP_FRTempSts "前排右侧温度设置";
CM_ SG_ 1107 TMS_CCP_RecyMode "内外循环";
CM_ SG_ 1107 TMS_CCP_FrontDefrostSts "前除霜";
CM_ SG_ 1107 TMS_UVC_WorkingBfReq "紫外线杀菌灯请求";
CM_ SG_ 1107 TMS_UVC_LuminanceBfReq "紫外线杀菌灯强度请求";
CM_ SG_ 1107 TMS_CCP_ACFastCool "一键制冷反馈";
CM_ SG_ 1107 TMS_CCP_ACFastHeat "一键制热反馈";
CM_ SG_ 1175 CCP_2_FRTempSwitchReq "同上";
CM_ SG_ 1175 CCP_2_RecyModeReq "内外循环";
CM_ SG_ 1175 CCP_2_DefrostModeSwitchReq "前除霜";
CM_ SG_ 1175 CCP_2_RearDefrostSwitchReq "后除霜请求";
CM_ SG_ 1175 CCP_2_ACFastHeat "一键制热请求";
CM_ SG_ 1175 CCP_2_FrontBlowSpdCtrlSwitchReq "前排风速";
CM_ SG_ 1175 FRCCP_DeputySetHeatReq "副驾座椅加热";
CM_ SG_ 1175 FRCCP_DeputySetVentilationReq "副驾座椅通风";
CM_ SG_ 1175 CCP_2_ACSwitchReq "AC开关请求";
CM_ SG_ 1292 CHB_App_Sts "冰箱开关状态（捷途预留）";
CM_ SG_ 1292 CHB_AppMem_Sts "记忆开关状态";
CM_ SG_ 1292 CHB_AppDelay_Sts "延时开关状态";
CM_ SG_ 1292 CHB_AppTimeset_Sts "延时时间设置";
CM_ SG_ 1292 CHB_AppCoolorheat_Sts "制冷制热选择状态
冰箱工作模式（捷途使用）
0x0：无请求
0x1：制冷
0x2：制热
0x3：关
0x4：冷饮模式
0x5：冰淇淋模式
0x6：温奶模式
0x7：热饮模式";
CM_ SG_ 1292 CHB_AppCoolset_Sts "制冷温度设置
0xE~0x19:-18℃~-7℃（捷途预留）
0x1~0xD:-6℃~6℃（捷途使用）";
CM_ SG_ 1292 CHB_AppHeatset_Sts "制热温度调节设置";
CM_ SG_ 1292 CHB_AppSterilization_Sts "杀菌开关状态";
CM_ SG_ 1292 CHB_AppItemsLeft_Sts "物品遗留开关状态";
CM_ SG_ 1292 CHB_AppItemsLeftset_Sts "冰箱是否检测到物品的状态";
CM_ SG_ 1292 CHB_AppChbDoor_Sts "冰箱是门开关状态反馈信号";
CM_ SG_ 1241 FuelTankLidSystemFailureSts "加油小门系统故障信号";
CM_ SG_ 1241 FuelTankPressureConditionReached "油箱压力状态信号";
CM_ SG_ 49 ACU_2_LateralAcceleration "Lateral acceleration signal
Sensor accuracy：0.0027680342857143g";
CM_ SG_ 49 ACU_2_YawRate "Yaw rate signal
Sensor accuracy：0.122189236 deg/s";
CM_ SG_ 49 ACU_2_YawrateSigValidData "Signal state for yawrate";
CM_ SG_ 49 ACU_2_LateralAccelerationSigVD "If hasn’t been calibrated, after initialization, this signal ‘s value is always 10(invalid).";
CM_ SG_ 1024 CSunshadeSts "天幕遮阳帘实际状态
(大屏动效-可显示开启和关闭的动画)";
CM_ SG_ 1024 CSunshadePercentSts "天幕遮阳帘开度百分比状态";
CM_ SG_ 1024 FRZCU_SeatHeatLvlFR2 "副驾座椅加热状态--捷途使用";
CM_ SG_ 1024 FRZCU_SeatVentLvlFR2 "副驾座椅通风状态--捷途使用";
CM_ SG_ 1024 FRZCU_SeatVentLvlRR2 "二排右侧座椅通风状态--捷途使用";
CM_ SG_ 1024 FRZCU_SeatHeatLvlRR2 "二排右侧座椅加热状态--捷途使用";
CM_ SG_ 1024 FRZCU_ContainerlightSts "货箱灯状态反馈（D01P)";
CM_ SG_ 1024 FRZCU_FRWinThermalSts "右前车窗热保护状态
0：未触发热保护
1：热保护触发中";
CM_ SG_ 1024 FRZCU_RRWinThermalSts "右后车窗热保护状态
0：未触发热保护
1：热保护触发中";
CM_ SG_ 1024 FRZCU_CSunshadeThermalSts "天幕遮阳帘热保护状态
0：未触发热保护
1：热保护触发中";
CM_ SG_ 1182 OBC_ElectronicLockSts "Electronic Lock Sts";
CM_ SG_ 1182 OBC_WorkingMode "OBC working states";
CM_ SG_ 290 EPS_1_CRC "Profile1A:E2E CRC (SAE J1850 CRC-8) for 8 Bytes
DataID:0x002E";
CM_ SG_ 290 EPS_1_RollgCntr "Profile1A:E2E Rolling message counter(the maximum value of Alive counter is 14)";
CM_ SG_ 290 EPSFailSts "EPS Fail Status";
CM_ SG_ 290 EPSSteeringAngleCalibrationSts "EPS Steering Angle Calibration Status";
CM_ SG_ 290 EPS_EOTLearning_Sts "Indicates the status of EPS EOT(end of travel) learning, displayed on the DMC(ICM)";
CM_ SG_ 1152 TBOX_PetmodeSetTemperature "宠物模式远程空调温度设置";
CM_ SG_ 1208 PPMID_1_PPMICounter "PPMI counter/寿命计数状态";
CM_ SG_ 1208 PPMID_1_PPMISt "PPMI status/ PPMI是否有故障";
CM_ SG_ 1208 PPMID_1_HWSts "Haptic Warning(HWA) /  震动触觉提醒";
CM_ SG_ 1208 PPMID_1_BSRBPASts "Belt slack reduction(BSR) / 织带间隙消除
Belt parking assist(BPA) / 织带辅助回收";
CM_ SG_ 794 ADS_3_ICAStatus "ICA状态信号";
CM_ SG_ 794 ADS_3_ICATextinfo "ICA状态信号（文本提示）";
CM_ SG_ 794 ADS_3_ACCSts "ACC状态信号";
CM_ SG_ 794 ADS_3_DriverHandsoffWarning "驾驶员脱手报警请求";
CM_ SG_ 794 ADS_3_LKSMod "LDW LDP激活模式状态";
CM_ SG_ 794 ADS_3_LKSSts "LKS状态信号";
CM_ SG_ 794 ADS_3_ELKSts "ELK状态信号";
CM_ SG_ 794 ADS_3_LKSLeftTrackingSt "LDW LDP左侧车道线激活状态";
CM_ SG_ 794 ADS_3_LKSRightTrackingSt "LDW LDP右侧车道线激活状态";
CM_ SG_ 794 ADS_3_ELKLeftActiveSt "ELK左侧车道线激活状态";
CM_ SG_ 794 ADS_3_ELKRightActiveSt "ELK右侧车道线激活状态";
CM_ SG_ 1155 ASU_3_horizontalSts "露营找平开关状态
0x1:ON开关开启
0x2:OFF开关关闭";
CM_ SG_ 1155 ASU_3_horizontalmodeFb "露营找平模式反馈
0x0:Not Active条件不满足，未激活
0x1:Working找平中
0x2:Complete找平完成
0x3:Abort找平中断
0x4:Failure找平失败";
CM_ SG_ 1164 OBC_DischgSts "（新增OBC中控屏使用外放电电流显示）
0x0:NoDischarge
0x1:Discharging(外放电)
0x2:Discharging-Interior(内放电)
0x3:Discharging_AND_Discharging-Interior(内外放电同时进行)";
CM_ SG_ 789 ATCM_DriveModeSw "驾驶模式状态
（正旋一次共发送4帧信号：
三帧0×1加一帧0×0
反旋一次共发送4帧信号：
三帧0×2加一帧0×0
信号周期20ms/帧）";
CM_ SG_ 789 ATCM_XModeSw "X模式状态";
CM_ SG_ 789 ATCM_SwitchUTurnModeSet "极限掉头开关/坦克掉头
（点击一次共发送3帧信号：
三帧0×1）";
CM_ SG_ 1214 BNCM_16_CRC1 "Profile1A:E2E CRC (SAE J1850 CRC-8) for 8 Bytes
DataID:No ASIL requirements.Not configure
CRC Reserved.";
CM_ SG_ 1214 BNCM_16_RollgCntr1 "Profile1A:E2E Rolling message counter(the maximum value of Alive counter is 14)要求启动计数，每发一帧计数一次，到最大值14之后从0重新计数，防止有两个连续单帧的情况发生";
CM_ SG_ 1214 BNCM_16_Resd1 "Profile1A:E2E Reserved";
CM_ SG_ 1095 RLCR_1_CRC1 "Profile1A:E2E CRC (SAE J1850 CRC-8) for 8 Bytes
DataID:0x0044";
CM_ SG_ 1095 RLCR_1_RollgCntr1 "Profile1A:E2E Rolling message counter(the maximum value of Alive counter is 14)";
CM_ SG_ 1095 RLCR_1_Resd1 "Profile1A:E2E Reserved";
CM_ SG_ 1095 RLCR_1_SysSt "System self-test State";
CM_ SG_ 1095 RLCR_1_BlkSts "Blockage Status";
CM_ SG_ 1095 RLCR_1_BSDWarn "BSD/LCA Warning";
CM_ SG_ 1095 RLCR_1_DOWWarn "Door open warning Warning";
CM_ SG_ 1095 RLCR_1_DowLock "Door locking Warning（功能预留不发）";
CM_ SG_ 1267 RRCR_1_CRC1 "Profile1A:E2E CRC (SAE J1850 CRC-8) for 8 Bytes
DataID:0x0046";
CM_ SG_ 1267 RRCR_1_RollgCntr1 "Profile1A:E2E Rolling message counter(the maximum value of Alive counter is 14)";
CM_ SG_ 1267 RRCR_1_Resd1 "Profile1A:E2E Reserved";
CM_ SG_ 1267 RRCR_1_SysSt "System self-test State";
CM_ SG_ 1267 RRCR_1_BlkSts "Blockage Status";
CM_ SG_ 1267 RRCR_1_BSDWarn "BSD/LCA Warning";
CM_ SG_ 1267 RRCR_1_DOWWarn "Door open warning Warning";
CM_ SG_ 1267 RRCR_1_DowLock "Door locking Warning（功能预留不发）";
CM_ SG_ 788 ADS_2_AEBStatus "AEB状态信号
以下为平台化库数据内容
0x0:OFF
0x1:ON
0x2:Failure
0x3:no_active(0x3:available捷途使用)
0x4:active
0x5:pre-fill
0x6 blindness(捷途使用)";
CM_ SG_ 788 ADS_2_FCWStatus "FCW状态信号";
CM_ SG_ 788 FCM_2_IHCfunctionSts "远近光自动切换功能状态";
CM_ SG_ 571 LHTurnlightSts "转向灯-左";
CM_ SG_ 571 RHTurnlightSts "转向灯-右";
CM_ SG_ 571 LHFDoorLockSts "主驾门锁";
CM_ SG_ 571 LHTurnSW "左转向开关，打开发1；关闭发0，默认发0";
CM_ SG_ 571 RHTurnSW "右转向开关，打开发1；关闭发0，默认发0";
CM_ SG_ 571 HazardLightSW "带自锁的开关，按照危险灯状态发送；不带自锁的开关，发送危险灯状态";
CM_ SG_ 571 LHFSeatBeltSW "安全带检测开关，0为未插入，1为插入";
CM_ SG_ 571 DirectionIndLeft "当左转向灯闪烁时一直发1，转向灯熄灭时一直发0.";
CM_ SG_ 571 DirectionIndRight "当右转向灯闪烁时一直发1，转向灯熄灭时一直发0.";
CM_ SG_ 699 LHRdoorSts "左后门状态";
CM_ SG_ 787 ChrgHoodSts "充电口盖状态反馈
股份FLZCU0x33E发，捷途由FRZCU发";
CM_ SG_ 787 FRZCU_FRSitPosnSts "副驾座椅记忆位置反馈";
CM_ SG_ 524 ADS_6_CRC1 "Profile1A:E2E CRC (SAE J1850 CRC-8) for 8 Bytes
DataID:0x00F9";
CM_ SG_ 524 ADS_6_RollgCntr1 "Profile1A:E2E Rolling message counter(the maximum value of Alive counter is 14)";
CM_ SG_ 524 ADS_6_Resd1 "Profile1A:E2E Reserved";
CM_ SG_ 524 ADS_6_AVM_FuncSts "AVM当前激活状态";
CM_ SG_ 524 ADS_6_AVM_ButtonClick "AVM按键音请求";
CM_ SG_ 524 ADS_6_Customize_buttonsFB "自定义按键大屏设置设置项反馈
0x4:记忆泊车";
CM_ SG_ 524 ADS_6_PAS_AudioTone "倒车雷达报警声音";
CM_ SG_ 572 ONEBOX_7_TAB_HighTemp "坦克转弯工作温度过高";
CM_ SG_ 572 ONEBOX_7_TAB_Active "IPB反馈TAB状态";
CM_ SG_ 572 ONEBOX_7_BSW_Active "智能擦盘状态反馈信号";
CM_ SG_ 572 ONEBOX_7_iCCO_TgtVel "iCCO功能目标车速";
CM_ SG_ 1212 VCU_3_G_ActWheelTorqueFA "Actual wheel torque at FA前轮轮端实际扭矩";
CM_ SG_ 1212 VCU_3_G_ActWheelTorqueRA "Actual wheel torque at RA后轮轮端实际扭矩";
CM_ SG_ 783 ADCC_SysReadySts "ADAS系统状态";
CM_ SG_ 943 CSA_3_CRC1 "Profile1A:E2E CRC (SAE J1850 CRC-8) for 8 Bytes
DataID:Reserved";
CM_ SG_ 943 CSA_3_RollgCntr1 "Profile1A:E2E Rolling message counter(the maximum value of Alive counter is 14)";
CM_ SG_ 943 CSA_3_Resd1 "Profile1A:E2E Reserved";
CM_ SG_ 943 FlwheelBearing "持续发送左前轮载荷值(吨)";
CM_ SG_ 943 FrwheelBearing "持续发送右前轮载荷值(吨)";
CM_ SG_ 943 BlwheelBearing "持续发送左后轮载荷值(吨)";
CM_ SG_ 943 BrwheelBearing "持续发送右后轮载荷值(吨)";
CM_ SG_ 943 CSA_3_CRC2 "Profile1A:E2E CRC (SAE J1850 CRC-8) for 8 Bytes
DataID:Reserved";
CM_ SG_ 943 CSA_3_RollgCntr2 "Profile1A:E2E Rolling message counter(the maximum value of Alive counter is 14)";
CM_ SG_ 943 VehicleBearing_kg "持续发送整车重量(kg)";
CM_ SG_ 943 VehicleBearing_lb "持续发送整车重量(lb)";
CM_ SG_ 943 GoodsWeight_kg "持续发送货物重量(kg)";
CM_ SG_ 943 Goods_Weight_Ratio "持续发送货物重量百分比(%)";
CM_ SG_ 943 CSA_3_CRC3 "Profile1A:E2E CRC (SAE J1850 CRC-8) for 8 Bytes
DataID:Reserved";
CM_ SG_ 943 CSA_3_RollgCntr3 "Profile1A:E2E Rolling message counter(the maximum value of Alive counter is 14)";
CM_ SG_ 943 CSA_3_Resd3 "Profile1A:E2E Reserved";
CM_ SG_ 943 GoodsWeight_lb "持续发送货物重量(lb)";
CM_ SG_ 943 OverWeightValue_kg "持续发送超重值（kg)";
CM_ SG_ 943 OverWeightValue_lb "持续发送超重值（lb)";
CM_ SG_ 943 OverWeightRatio "持续发送超重百公比(%)";
CM_ SG_ 943 OverWeightWarning "超重时发送超重报警信号";
CM_ SG_ 943 OverLoadWarnShieldSetFed "大屏重量报警屏蔽软开关反馈信号";
CM_ SG_ 1120 RLHS_2_AmbBrightness "顶向光";
CM_ SG_ 1120 RLHS_LiSwithReason "开关灯切换原因
RLS_ LightSwithReason";
CM_ SG_ 850 ASU_6_HMIFailFb_JT "0x0:无状态，不显示
0x1:悬架调节已锁定，请先解除锁定
0x2:尾门未关闭，载物模式已退出
0x3:悬架高度调节已禁用
0x4:悬架软硬调节已禁用
0x5:当前海拔过高，悬架高度调节已禁用
0x6~0xF:reserved";
CM_ SG_ 1199 TCM_1_TrailerSts "Trailer Status send by TCM. Vehicle can use this information to turn off/on some assistance like Park Distance Control. Furthermore it might be used to turn off the fog light on the vehicle when a trailer is connected (at least in germany, there is a law saying that the vehicles fog lamp must not be turned on when a trailer is connected - only the fog of the trailer should be turned on).";
BA_DEF_ BO_  "GenMsgCycleTimeFast" INT 0 50000;
BA_DEF_ BO_  "GenMsgNrOfRepetition" INT 0 999999;
BA_DEF_ BO_  "GenMsgDelayTime" INT 0 1000;
BA_DEF_ BO_  "VFrameFormat" ENUM  "StandardCAN","ExtendedCAN","reserved","reserved","reserved","reserved","reserved","reserved","reserved","reserved","reserved","reserved","reserved","reserved","StandardCAN_FD","ExtendedCAN_FD";
BA_DEF_ BO_  "GenMsgILSupport" ENUM  "No","Yes";
BA_DEF_ BO_  "NmMessage" ENUM  "No","Yes";
BA_DEF_ BO_  "GenMsgSendType" ENUM  "Cycle","Event","IfActive","CE","CA","NoMsgSendType";
BA_DEF_ BO_  "GenMsgCycleTime" INT 0 50000;
BA_DEF_ BO_  "CANFD_BRS" INT 0 1;
BA_DEF_ BO_  "NmAsrMessage" ENUM  "No","Yes";
BA_DEF_ BO_  "GRC_ASIL" ENUM  "vector_leerstring","QM","A","B","C","D";
BA_DEF_ BO_  "GRC_History" STRING ;
BA_DEF_ SG_  "GenSigStartValue" FLOAT 0 100000000000;
BA_DEF_ SG_  "GenSigInactiveValue" INT 0 100000;
BA_DEF_ SG_  "GenSigInvalidValue" INT 0 251610920;
BA_DEF_ SG_  "GenSigSendType" ENUM  "Cycle","OnChange","OnWrite","IfActive","OnChangeWithRepetition","OnWriteWithRepetition","IfActiveWithRepetition","NoSigSendType","OnChangeAndIfActive","OnChangeAndIfActiveWithRepetition","CA","CE","Event";
BA_DEF_ SG_  "GRC_Sig_ASIL" ENUM  "vector_leerstring","QM","A","B","C","D";
BA_DEF_ SG_  "E2EDataId" INT 0 0;
BA_DEF_ SG_  "E2EProfile" STRING ;
BA_DEF_ SG_  "E2EDataLength" INT 0 512;
BA_DEF_DEF_  "GenMsgCycleTimeFast" 0;
BA_DEF_DEF_  "GenMsgNrOfRepetition" 0;
BA_DEF_DEF_  "GenMsgDelayTime" 0;
BA_DEF_DEF_  "VFrameFormat" "StandardCAN";
BA_DEF_DEF_  "GenMsgILSupport" "No";
BA_DEF_DEF_  "NmMessage" "No";
BA_DEF_DEF_  "GenMsgSendType" "NoMsgSendType";
BA_DEF_DEF_  "GenMsgCycleTime" 0;
BA_DEF_DEF_  "CANFD_BRS" 0;
BA_DEF_DEF_  "NmAsrMessage" "No";
BA_DEF_DEF_  "GRC_ASIL" "";
BA_DEF_DEF_  "GRC_History" "";
BA_DEF_DEF_  "GenSigStartValue" 0;
BA_DEF_DEF_  "GenSigInactiveValue" 0;
BA_DEF_DEF_  "GenSigInvalidValue" 0;
BA_DEF_DEF_  "GenSigSendType" "NoSigSendType";
BA_DEF_DEF_  "GRC_Sig_ASIL" "";
BA_DEF_DEF_  "E2EDataId" 0;
BA_DEF_DEF_  "E2EProfile" "";
BA_DEF_DEF_  "E2EDataLength" 0;
BA_ "GRC_History" BO_ 1224 "[{'approvedBy':'贾少辉','author':'吴慧','changesComments':'同步EP网段，补充BMS_Chg_Sts初始值为0x0','date':'2024/12/14','ecu':'BMS_12(0x4C8)','ecuName':'ICC','reviewedBy':'杨华','revision':'V2.1'}]";
BA_ "GenMsgILSupport" BO_ 1224 1;
BA_ "GenMsgCycleTime" BO_ 1224 100;
BA_ "GenMsgSendType" BO_ 1224 0;
BA_ "CANFD_BRS" BO_ 1224 1;
BA_ "VFrameFormat" BO_ 1224 14;
BA_ "GRC_History" BO_ 1235 "[{'approvedBy':'贾少辉','author':'吴慧','changesComments':'同步CH网段，补充所有未填写的初始值,补充为0x0','date':'2024/12/13','ecu':'EPS_2(0x4D3)','ecuName':'CGW','reviewedBy':'杨华','revision':'V2.1'}]";
BA_ "GenMsgILSupport" BO_ 1235 1;
BA_ "GenMsgCycleTime" BO_ 1235 100;
BA_ "GenMsgSendType" BO_ 1235 0;
BA_ "CANFD_BRS" BO_ 1235 1;
BA_ "VFrameFormat" BO_ 1235 14;
BA_ "GenMsgILSupport" BO_ 1330 1;
BA_ "GenMsgCycleTime" BO_ 1330 100;
BA_ "GenMsgSendType" BO_ 1330 0;
BA_ "CANFD_BRS" BO_ 1330 1;
BA_ "VFrameFormat" BO_ 1330 14;
BA_ "GRC_History" BO_ 1328 "[{'approvedBy':'贾少辉','author':'吴慧','changesComments':'新增一列信息：E2E SignalGroup功能安全信号组','date':'2025/1/13','ecu':'RADAR_1(0x530)','ecuName':'ICC','reviewedBy':'杨华','revision':'V2.1.1'}]";
BA_ "GenMsgILSupport" BO_ 1328 1;
BA_ "GenMsgCycleTime" BO_ 1328 100;
BA_ "GenMsgSendType" BO_ 1328 0;
BA_ "CANFD_BRS" BO_ 1328 1;
BA_ "VFrameFormat" BO_ 1328 14;
BA_ "GRC_History" BO_ 259 "[{'approvedBy':'贾少辉','author':'吴慧','changesComments':'同步PT网段，补充所有未填写的初始值,补充为0x0和0x12C','date':'2024/12/14','ecu':'EMS_6(0x103)','ecuName':'CGW','reviewedBy':'杨华','revision':'V2.1'},{'approvedBy':'贾少辉','author':'吴慧','change";
BA_ "GenMsgILSupport" BO_ 259 1;
BA_ "GenMsgCycleTime" BO_ 259 10;
BA_ "GenMsgSendType" BO_ 259 0;
BA_ "CANFD_BRS" BO_ 259 1;
BA_ "VFrameFormat" BO_ 259 14;
BA_ "GRC_History" BO_ 1234 "[{'approvedBy':'贾少辉','author':'吴慧','changesComments':'李思思BBCM新增接收FRZCU_FRSeatHeiFb和FRZCU_FRSeatLvlFb和FRZCU_FRSeatBackAgFb和FRZCU_FRSeatCushFb因一、二排座椅会有干涉的区间','date':'2024/12/23','ecu':'FRZCU_11(0x4D2)','ecuName':'CGW,BBCM','rev";
BA_ "GenMsgILSupport" BO_ 1234 1;
BA_ "GenMsgCycleTime" BO_ 1234 100;
BA_ "GenMsgSendType" BO_ 1234 0;
BA_ "CANFD_BRS" BO_ 1234 1;
BA_ "VFrameFormat" BO_ 1234 14;
BA_ "GenMsgILSupport" BO_ 517 1;
BA_ "GenMsgCycleTime" BO_ 517 20;
BA_ "GenMsgSendType" BO_ 517 0;
BA_ "CANFD_BRS" BO_ 517 1;
BA_ "VFrameFormat" BO_ 517 14;
BA_ "GRC_History" BO_ 1096 "[{'approvedBy':'贾少辉','author':'吴慧','changesComments':'信号名称过长，史文妍TMS_DVD_SET_Circulation_intunnels_SpeedSts信号名称改成TMS_CirculationInTunnelsSts','date':'2024/11/5','ecu':'TMS_11(0x448)','ecuName':'ICC','reviewedBy':'杨华','revision':'V1.";
BA_ "GenMsgILSupport" BO_ 1096 1;
BA_ "GenMsgCycleTime" BO_ 1096 100;
BA_ "GenMsgSendType" BO_ 1096 0;
BA_ "CANFD_BRS" BO_ 1096 1;
BA_ "VFrameFormat" BO_ 1096 14;
BA_ "GenMsgILSupport" BO_ 1240 1;
BA_ "GenMsgCycleTime" BO_ 1240 100;
BA_ "GenMsgSendType" BO_ 1240 0;
BA_ "CANFD_BRS" BO_ 1240 1;
BA_ "VFrameFormat" BO_ 1240 14;
BA_ "GenMsgILSupport" BO_ 638 1;
BA_ "GenMsgCycleTime" BO_ 638 20;
BA_ "GenMsgSendType" BO_ 638 0;
BA_ "CANFD_BRS" BO_ 638 1;
BA_ "VFrameFormat" BO_ 638 14;
BA_ "GenMsgILSupport" BO_ 949 1;
BA_ "GenMsgDelayTime" BO_ 949 5;
BA_ "GenMsgNrOfRepetition" BO_ 949 3;
BA_ "GenMsgCycleTimeFast" BO_ 949 50;
BA_ "GenMsgCycleTime" BO_ 949 50;
BA_ "GenMsgSendType" BO_ 949 3;
BA_ "CANFD_BRS" BO_ 949 1;
BA_ "VFrameFormat" BO_ 949 14;
BA_ "GRC_History" BO_ 1028 "[{'approvedBy':'贾少辉','author':'吴慧','changesComments':'史文妍PEPS_WelcomeON和PEPS_VehicleSearchReq物理最大值应为3','date':'2024/11/5','ecu':'PEPS_2(0x404)','ecuName':'ICC,BBCM','reviewedBy':'杨华','revision':'V1.3.1'}]";
BA_ "GenMsgILSupport" BO_ 1028 1;
BA_ "GenMsgDelayTime" BO_ 1028 5;
BA_ "GenMsgNrOfRepetition" BO_ 1028 3;
BA_ "GenMsgCycleTimeFast" BO_ 1028 50;
BA_ "GenMsgCycleTime" BO_ 1028 100;
BA_ "GenMsgSendType" BO_ 1028 3;
BA_ "CANFD_BRS" BO_ 1028 1;
BA_ "VFrameFormat" BO_ 1028 14;
BA_ "GRC_History" BO_ 1291 "[{'approvedBy':'贾少辉','author':'吴慧','changesComments':'同步EP网段，补充所有未填写的初始值,补充为0x0','date':'2024/12/14','ecu':'BMS_2_G(0x50B)','ecuName':'ICC','reviewedBy':'杨华','revision':'V2.1'},{'approvedBy':'贾少辉','author':'吴慧','changesComm";
BA_ "GenMsgILSupport" BO_ 1291 1;
BA_ "GenMsgCycleTime" BO_ 1291 500;
BA_ "GenMsgSendType" BO_ 1291 0;
BA_ "CANFD_BRS" BO_ 1291 1;
BA_ "VFrameFormat" BO_ 1291 14;
BA_ "GRC_History" BO_ 1104 "[{'approvedBy':'贾少辉','author':'吴慧','changesComments':'刘标ICC接收端更新：整帧接收','date':'2024/12/3','ecu':'RLCR_2(0x450)','ecuName':'ICC','reviewedBy':'杨华','revision':'V2.1'},{'approvedBy':'贾少辉','author':'吴慧','changesComments':'新增一列信息";
BA_ "GenMsgILSupport" BO_ 1104 1;
BA_ "GenMsgCycleTime" BO_ 1104 100;
BA_ "GenMsgSendType" BO_ 1104 0;
BA_ "CANFD_BRS" BO_ 1104 1;
BA_ "VFrameFormat" BO_ 1104 14;
BA_ "GRC_History" BO_ 1271 "[{'approvedBy':'贾少辉','author':'吴慧','changesComments':'刘标ICC接收端更新：整帧接收','date':'2024/12/3','ecu':'RRCR_2(0x4F7)','ecuName':'ICC','reviewedBy':'杨华','revision':'V2.1'},{'approvedBy':'贾少辉','author':'吴慧','changesComments':'新增一列信息";
BA_ "GenMsgILSupport" BO_ 1271 1;
BA_ "GenMsgCycleTime" BO_ 1271 100;
BA_ "GenMsgSendType" BO_ 1271 0;
BA_ "CANFD_BRS" BO_ 1271 1;
BA_ "VFrameFormat" BO_ 1271 14;
BA_ "GRC_History" BO_ 587 "[{'approvedBy':'贾少辉','author':'吴慧','changesComments':'ICC新增接收LHFWheelDriveDirection和RHFWheelDriveDirection和LHRWheelDriveDirection和RHRWheelDriveDirection和ONEBOX_4_LHFWheelSpeedRPM和ONEBOX_4_RHFWheelSpeedRPM和LHRWheelSpeedRPM和RHRWheelSpeedRPM";
BA_ "GRC_ASIL" BO_ 587 5;
BA_ "GenMsgILSupport" BO_ 587 1;
BA_ "GenMsgCycleTime" BO_ 587 20;
BA_ "GenMsgSendType" BO_ 587 0;
BA_ "CANFD_BRS" BO_ 587 1;
BA_ "VFrameFormat" BO_ 587 14;
BA_ "GRC_History" BO_ 1338 "[{'approvedBy':'贾少辉','author':'吴慧','changesComments':'同步PT网段，补充所有未填写的初始值,补充为0x0和0x7FFF','date':'2024/12/14','ecu':'FMCU_1_G(0x53A)','ecuName':'ICC','reviewedBy':'杨华','revision':'V2.1'},{'approvedBy':'贾少辉','author':'吴慧','ch";
BA_ "GenMsgILSupport" BO_ 1338 1;
BA_ "GenMsgCycleTime" BO_ 1338 500;
BA_ "GenMsgSendType" BO_ 1338 0;
BA_ "CANFD_BRS" BO_ 1338 1;
BA_ "VFrameFormat" BO_ 1338 14;
BA_ "GRC_History" BO_ 777 "[{'approvedBy':'贾少辉','author':'吴慧','changesComments':'同步PT网段，补充所有未填写的初始值,补充为0x0和0x7FFF和0x28','date':'2024/12/14','ecu':'ISGF_2(0x309)','ecuName':'ICC','reviewedBy':'杨华','revision':'V2.1'}]";
BA_ "GenMsgILSupport" BO_ 777 1;
BA_ "GenMsgCycleTime" BO_ 777 50;
BA_ "GenMsgSendType" BO_ 777 0;
BA_ "CANFD_BRS" BO_ 777 1;
BA_ "VFrameFormat" BO_ 777 14;
BA_ "GRC_History" BO_ 1403 "[{'approvedBy':'贾少辉','author':'吴慧','changesComments':'同步PT网段，补充所有未填写的初始值,补充为0x0','date':'2024/12/14','ecu':'RMCU_1_G(0x57B)','ecuName':'ICC','reviewedBy':'杨华','revision':'V2.1'}]";
BA_ "GenMsgILSupport" BO_ 1403 1;
BA_ "GenMsgCycleTime" BO_ 1403 500;
BA_ "GenMsgSendType" BO_ 1403 0;
BA_ "CANFD_BRS" BO_ 1403 1;
BA_ "VFrameFormat" BO_ 1403 14;
BA_ "GenMsgILSupport" BO_ 1299 1;
BA_ "GenMsgCycleTime" BO_ 1299 500;
BA_ "GenMsgSendType" BO_ 1299 0;
BA_ "CANFD_BRS" BO_ 1299 1;
BA_ "VFrameFormat" BO_ 1299 14;
BA_ "GRC_History" BO_ 1099 "[{'approvedBy':'贾少辉','author':'吴慧','changesComments':'同步PT网段，补充所有未填写的初始值,补充为0x0和0x28','date':'2024/12/14','ecu':'ISGF_4(0x44B)','ecuName':'ICC','reviewedBy':'杨华','revision':'V2.1'},{'approvedBy':'贾少辉','author':'吴慧','change";
BA_ "GenMsgILSupport" BO_ 1099 1;
BA_ "GenMsgCycleTime" BO_ 1099 100;
BA_ "GenMsgSendType" BO_ 1099 0;
BA_ "CANFD_BRS" BO_ 1099 1;
BA_ "VFrameFormat" BO_ 1099 14;
BA_ "GRC_History" BO_ 1130 "[{'approvedBy':'贾少辉','author':'吴慧','changesComments':'魏睿ICC新增接收TCU_23_TeachInState\n同步PT网段，补充所有未填写的初始值,补充为0x0','date':'2024/12/12','ecu':'TCU_23(0x46A)','ecuName':'ICC','reviewedBy':'杨华','revision':'V2.1'}]";
BA_ "GenMsgILSupport" BO_ 1130 1;
BA_ "GenMsgCycleTime" BO_ 1130 100;
BA_ "GenMsgSendType" BO_ 1130 0;
BA_ "CANFD_BRS" BO_ 1130 1;
BA_ "VFrameFormat" BO_ 1130 14;
BA_ "GRC_History" BO_ 1180 "[{'approvedBy':'贾少辉','author':'吴慧','changesComments':'同步CH网段源端，补充所有未填写的初始值,补充为0x0','date':'2024/12/12','ecu':'ACU_1(0x49C)','ecuName':'ICC,BBCM','reviewedBy':'杨华','revision':'V2.1'}]";
BA_ "GenMsgILSupport" BO_ 1180 1;
BA_ "GenMsgCycleTime" BO_ 1180 100;
BA_ "GenMsgSendType" BO_ 1180 0;
BA_ "CANFD_BRS" BO_ 1180 1;
BA_ "VFrameFormat" BO_ 1180 14;
BA_ "GRC_History" BO_ 1248 "[{'approvedBy':'贾少辉','author':'吴慧','changesComments':'同步GL网段新增14条信号\n新增FRZCU_RKEButtAct增加信号值描述0x2:RemoteLongPress','date':'2024/11/28','ecu':'FRZCU_TO_FLZCU(0x4E0)','ecuName':'CGW','reviewedBy':'杨华','revision':'V2.0'},{'approvedB";
BA_ "GenMsgILSupport" BO_ 1248 1;
BA_ "GenMsgDelayTime" BO_ 1248 5;
BA_ "GenMsgNrOfRepetition" BO_ 1248 5;
BA_ "GenMsgCycleTimeFast" BO_ 1248 10;
BA_ "GenMsgCycleTime" BO_ 1248 100;
BA_ "GenMsgSendType" BO_ 1248 3;
BA_ "CANFD_BRS" BO_ 1248 1;
BA_ "VFrameFormat" BO_ 1248 14;
BA_ "GRC_History" BO_ 1341 "[{'approvedBy':'贾少辉','author':'吴慧','changesComments':'同步EP网段，补充所有未填写的初始值,补充为0x0和0x2800','date':'2024/12/14','ecu':'BMS_44(0x53D)','ecuName':'ICC','reviewedBy':'杨华','revision':'V2.1'}]";
BA_ "GenMsgILSupport" BO_ 1341 1;
BA_ "GenMsgCycleTime" BO_ 1341 100;
BA_ "GenMsgSendType" BO_ 1341 0;
BA_ "CANFD_BRS" BO_ 1341 1;
BA_ "VFrameFormat" BO_ 1341 14;
BA_ "GRC_History" BO_ 811 "[{'approvedBy':'贾少辉','author':'吴慧','changesComments':'同步EP网段，补充BMS_Chg_Sts初始值为0x0','date':'2024/12/14','ecu':'BMS_6(0x32B)','ecuName':'ICC','reviewedBy':'杨华','revision':'V2.1'},{'approvedBy':'贾少辉','author':'吴慧','changesComments':'�";
BA_ "GenMsgILSupport" BO_ 811 1;
BA_ "GenMsgCycleTime" BO_ 811 50;
BA_ "GenMsgSendType" BO_ 811 0;
BA_ "CANFD_BRS" BO_ 811 1;
BA_ "VFrameFormat" BO_ 811 14;
BA_ "GRC_History" BO_ 1269 "[{'approvedBy':'贾少辉','author':'吴慧','changesComments':'信号名称加下划线LISD_TransmitStatus和LISD_DisplayStatus刘胤翠\nICC新增接收LISDShowCMDSts和LISDShowModeSts刘婷程永芳','date':'2024/11/4','ecu':'LISD_2(0x4F5)','ecuName':'ICC','reviewedBy':'杨华','";
BA_ "GenMsgILSupport" BO_ 1269 1;
BA_ "GenMsgCycleTime" BO_ 1269 100;
BA_ "GenMsgSendType" BO_ 1269 0;
BA_ "CANFD_BRS" BO_ 1269 1;
BA_ "VFrameFormat" BO_ 1269 14;
BA_ "GRC_History" BO_ 1233 "[{'approvedBy':'贾少辉','author':'吴慧','changesComments':'ICC新增接收RISDShowCMDSts和RISDShowModeSts刘婷程永芳','date':'2024/11/4','ecu':'RISD_2(0x4D1)','ecuName':'ICC','reviewedBy':'杨华','revision':'V1.3.1'},{'approvedBy':'贾少辉','author':'吴慧','cha";
BA_ "GenMsgILSupport" BO_ 1233 1;
BA_ "GenMsgCycleTime" BO_ 1233 100;
BA_ "GenMsgSendType" BO_ 1233 0;
BA_ "CANFD_BRS" BO_ 1233 1;
BA_ "VFrameFormat" BO_ 1233 14;
BA_ "GenMsgILSupport" BO_ 1169 1;
BA_ "GenMsgCycleTime" BO_ 1169 100;
BA_ "GenMsgSendType" BO_ 1169 0;
BA_ "CANFD_BRS" BO_ 1169 1;
BA_ "VFrameFormat" BO_ 1169 14;
BA_ "GRC_History" BO_ 1427 "[{'approvedBy':'贾少辉','author':'吴慧','changesComments':'源端ILCF新增信号ILCF_1_LogoColorAdjSts，ICC接收Logo灯256颜色反馈','date':'2024/11/23','ecu':'ILCF_1(0x593)','ecuName':'ICC','reviewedBy':'杨华','revision':'V2.0'},{'approvedBy':'贾少辉','author':";
BA_ "GenMsgILSupport" BO_ 1427 1;
BA_ "GenMsgCycleTime" BO_ 1427 100;
BA_ "GenMsgSendType" BO_ 1427 0;
BA_ "CANFD_BRS" BO_ 1427 1;
BA_ "VFrameFormat" BO_ 1427 14;
BA_ "GRC_History" BO_ 821 "[{'approvedBy':'贾少辉','author':'吴慧','changesComments':'同步DA网段，补充所有未填写的初始值,补充为0x0','date':'2024/12/13','ecu':'ADS_5(0x335)','ecuName':'ICC,DVR','reviewedBy':'杨华','revision':'V2.1'}]";
BA_ "GenMsgILSupport" BO_ 821 1;
BA_ "GenMsgCycleTime" BO_ 821 50;
BA_ "GenMsgSendType" BO_ 821 0;
BA_ "CANFD_BRS" BO_ 821 1;
BA_ "VFrameFormat" BO_ 821 14;
BA_ "GRC_History" BO_ 819 "[{'approvedBy':'贾少辉','author':'吴慧','changesComments':'新增发送ADS_4_CruiseAccelerateSts\nADS_4_ACCTextMessage启用预留位0xF为takeover timeout\n更新ADS_4_DAISts信号状态','date':'2024/11/28','ecu':'ADS_4(0x333)','ecuName':'ICC','reviewedBy':'杨华','rev";
BA_ "GenMsgILSupport" BO_ 819 1;
BA_ "GenMsgCycleTime" BO_ 819 50;
BA_ "GenMsgSendType" BO_ 819 0;
BA_ "CANFD_BRS" BO_ 819 1;
BA_ "VFrameFormat" BO_ 819 14;
BA_ "GRC_History" BO_ 1172 "[{'approvedBy':'贾少辉','author':'吴慧','changesComments':'同步GL网段新增：TMS_1_IncarTemp信号，无接收端','date':'2024/11/28','ecu':'TMS_1（0x494）','ecuName':'CGW','reviewedBy':'杨华','revision':'V2.0'},{'approvedBy':'贾少辉','author':'吴慧','changesCom";
BA_ "GenMsgILSupport" BO_ 1172 1;
BA_ "GenMsgCycleTime" BO_ 1172 100;
BA_ "GenMsgSendType" BO_ 1172 0;
BA_ "CANFD_BRS" BO_ 1172 1;
BA_ "VFrameFormat" BO_ 1172 14;
BA_ "GRC_History" BO_ 1147 "[{'approvedBy':'贾少辉','author':'吴慧','changesComments':'同步GL网段，补充所有未填写的初始值,补充为0x0','date':'2024/12/13','ecu':'CCP_1(0x47B)','ecuName':'ICC','reviewedBy':'杨华','revision':'V2.1'},{'approvedBy':'贾少辉','author':'吴慧','changesCommen";
BA_ "GenMsgILSupport" BO_ 1147 1;
BA_ "GenMsgDelayTime" BO_ 1147 5;
BA_ "GenMsgNrOfRepetition" BO_ 1147 3;
BA_ "GenMsgCycleTimeFast" BO_ 1147 20;
BA_ "GenMsgCycleTime" BO_ 1147 100;
BA_ "GenMsgSendType" BO_ 1147 3;
BA_ "CANFD_BRS" BO_ 1147 1;
BA_ "VFrameFormat" BO_ 1147 14;
BA_ "GRC_History" BO_ 1107 "[{'approvedBy':'贾少辉','author':'吴慧','changesComments':'同步GL网段，补充所有未填写的初始值,补充为0x0','date':'2024/12/13','ecu':'TMS_10(0x453)','ecuName':'ICC','reviewedBy':'杨华','revision':'V2.1'},{'approvedBy':'贾少辉','author':'吴慧','changesComme";
BA_ "GenMsgILSupport" BO_ 1107 1;
BA_ "GenMsgCycleTime" BO_ 1107 100;
BA_ "GenMsgSendType" BO_ 1107 0;
BA_ "CANFD_BRS" BO_ 1107 1;
BA_ "VFrameFormat" BO_ 1107 14;
BA_ "GRC_History" BO_ 1175 "[{'approvedBy':'贾少辉','author':'吴慧','changesComments':'同步GL网段，补充所有未填写的初始值,补充为0x0','date':'2024/12/13','ecu':'CCP_2(0x497)','ecuName':'ICC','reviewedBy':'杨华','revision':'V2.1'},{'approvedBy':'贾少辉','author':'吴慧','changesCommen";
BA_ "GenMsgILSupport" BO_ 1175 1;
BA_ "GenMsgDelayTime" BO_ 1175 5;
BA_ "GenMsgNrOfRepetition" BO_ 1175 3;
BA_ "GenMsgCycleTimeFast" BO_ 1175 20;
BA_ "GenMsgCycleTime" BO_ 1175 100;
BA_ "GenMsgSendType" BO_ 1175 3;
BA_ "CANFD_BRS" BO_ 1175 1;
BA_ "VFrameFormat" BO_ 1175 14;
BA_ "GRC_History" BO_ 1292 "[{'approvedBy':'贾少辉','author':'吴慧','changesComments':'同步GL网段更改：CHB_AppCoolorheat_Sts最大值由0x3改成0x7\n增加CHB_AppChbSoc_Sts信号，整车Soc电量反馈信号，TBOX接收','date':'2024/11/28','ecu':'CHB_1(0x50C)','ecuName':'ICC','reviewedBy':'杨华','re";
BA_ "GenMsgILSupport" BO_ 1292 1;
BA_ "GenMsgCycleTime" BO_ 1292 500;
BA_ "GenMsgSendType" BO_ 1292 0;
BA_ "CANFD_BRS" BO_ 1292 1;
BA_ "VFrameFormat" BO_ 1292 14;
BA_ "GRC_History" BO_ 1241 "[{'approvedBy':'贾少辉','author':'吴慧','changesComments':'冯夏欣EMS新增信号EMS_4_G_KL15Sts,无接收端','date':'2025/2/18','ecu':'EMS_4_G(0x4D9)','ecuName':'CGW','reviewedBy':'杨华','revision':'V2.2'}]";
BA_ "GenMsgILSupport" BO_ 1241 1;
BA_ "GenMsgCycleTime" BO_ 1241 100;
BA_ "GenMsgSendType" BO_ 1241 0;
BA_ "CANFD_BRS" BO_ 1241 1;
BA_ "VFrameFormat" BO_ 1241 14;
BA_ "GRC_History" BO_ 49 "[{'approvedBy':'贾少辉','author':'吴慧','changesComments':'ACU_2_LateralAcceleration、ACU_2_YawRate、ACU_2_YawrateSigValidData、ACU_2_LateralAccelerationSigVD根据ACU工程师确认，更新初始值、无效值(汪苇)','date':'2024/10/23','ecu':'ACU_2(0x031)','ecuName':";
BA_ "GenMsgILSupport" BO_ 49 1;
BA_ "GenMsgCycleTime" BO_ 49 10;
BA_ "GenMsgSendType" BO_ 49 0;
BA_ "CANFD_BRS" BO_ 49 1;
BA_ "VFrameFormat" BO_ 49 14;
BA_ "GRC_History" BO_ 1024 "[{'approvedBy':'贾少辉','author':'吴慧','changesComments':'FLZCU新增FRZCU_FRWinThermalSts右前车窗热保护状态、FRZCU_RRWinThermalSts右后车窗热保护状态、FRZCU_CSunshadeThermalSts天幕遮阳帘热保护状态，ICC接收','date':'2024/12/30','ecu':'FRZCU_13(0x400)','ecu";
BA_ "GenMsgILSupport" BO_ 1024 1;
BA_ "GenMsgCycleTime" BO_ 1024 100;
BA_ "GenMsgSendType" BO_ 1024 0;
BA_ "CANFD_BRS" BO_ 1024 1;
BA_ "VFrameFormat" BO_ 1024 14;
BA_ "GRC_History" BO_ 1182 "[{'approvedBy':'贾少辉','author':'吴慧','changesComments':'同步EP网段，补充所有未填写的初始值,补充为0x0和0x28','date':'2024/12/13','ecu':'CDU_OBC_3(0x49E)','ecuName':'ICC','reviewedBy':'杨华','revision':'V2.1'},{'approvedBy':'贾少辉','author':'吴慧','cha";
BA_ "GenMsgILSupport" BO_ 1182 1;
BA_ "GenMsgCycleTime" BO_ 1182 100;
BA_ "GenMsgSendType" BO_ 1182 0;
BA_ "CANFD_BRS" BO_ 1182 1;
BA_ "VFrameFormat" BO_ 1182 14;
BA_ "GRC_History" BO_ 290 "[{'approvedBy':'贾少辉','author':'吴慧','changesComments':'魏睿ICC需求接收EPS_EOTLearning_Sts信号','date':'2024/12/12','ecu':'EPS_1(0x122)','ecuName':'ICC','reviewedBy':'杨华','revision':'V2.1'},{'approvedBy':'贾少辉','author':'吴慧','changesComments':'�";
BA_ "GenMsgILSupport" BO_ 290 1;
BA_ "GenMsgCycleTime" BO_ 290 10;
BA_ "GenMsgSendType" BO_ 290 0;
BA_ "CANFD_BRS" BO_ 290 1;
BA_ "VFrameFormat" BO_ 290 14;
BA_ "GenMsgILSupport" BO_ 513 1;
BA_ "GenMsgCycleTime" BO_ 513 20;
BA_ "GenMsgSendType" BO_ 513 0;
BA_ "CANFD_BRS" BO_ 513 1;
BA_ "VFrameFormat" BO_ 513 14;
BA_ "GenMsgILSupport" BO_ 1152 1;
BA_ "GenMsgDelayTime" BO_ 1152 5;
BA_ "GenMsgNrOfRepetition" BO_ 1152 3;
BA_ "GenMsgCycleTimeFast" BO_ 1152 100;
BA_ "GenMsgSendType" BO_ 1152 1;
BA_ "CANFD_BRS" BO_ 1152 1;
BA_ "VFrameFormat" BO_ 1152 14;
BA_ "GenMsgILSupport" BO_ 1208 1;
BA_ "GenMsgCycleTime" BO_ 1208 100;
BA_ "GenMsgSendType" BO_ 1208 0;
BA_ "VFrameFormat" BO_ 1208 14;
BA_ "GRC_History" BO_ 794 "[{'approvedBy':'贾少辉','author':'吴慧','changesComments':'同步汪苇更新ADS_3_ICATextinfo新增枚举值0xD:Master switch is off用于HMI显示\n新增发送ADAS_HNOPSts(高速领航状态)、ADAS_CityNOASts(城市记忆领航状态)','date':'2024/11/28','ecu':'ADS_COM_3(0x31A)','ec";
BA_ "GenMsgILSupport" BO_ 794 1;
BA_ "GenMsgCycleTime" BO_ 794 50;
BA_ "GenMsgSendType" BO_ 794 0;
BA_ "CANFD_BRS" BO_ 794 1;
BA_ "VFrameFormat" BO_ 794 14;
BA_ "GenMsgILSupport" BO_ 1155 1;
BA_ "GenMsgCycleTime" BO_ 1155 100;
BA_ "GenMsgSendType" BO_ 1155 0;
BA_ "CANFD_BRS" BO_ 1155 1;
BA_ "VFrameFormat" BO_ 1155 14;
BA_ "GenMsgILSupport" BO_ 1164 1;
BA_ "GenMsgCycleTime" BO_ 1164 100;
BA_ "GenMsgSendType" BO_ 1164 0;
BA_ "CANFD_BRS" BO_ 1164 1;
BA_ "VFrameFormat" BO_ 1164 14;
BA_ "GenMsgILSupport" BO_ 789 1;
BA_ "GenMsgDelayTime" BO_ 789 5;
BA_ "GenMsgNrOfRepetition" BO_ 789 3;
BA_ "GenMsgCycleTimeFast" BO_ 789 20;
BA_ "GenMsgSendType" BO_ 789 1;
BA_ "VFrameFormat" BO_ 789 14;
BA_ "GenMsgILSupport" BO_ 1214 1;
BA_ "GenMsgDelayTime" BO_ 1214 5;
BA_ "GenMsgSendType" BO_ 1214 1;
BA_ "CANFD_BRS" BO_ 1214 1;
BA_ "VFrameFormat" BO_ 1214 14;
BA_ "GRC_History" BO_ 1095 "[{'approvedBy':'贾少辉','author':'吴慧','changesComments':'刘标ICC接收端更新：整帧接收','date':'2024/12/3','ecu':'RLCR_1(0x447)','ecuName':'ICC','reviewedBy':'杨华','revision':'V2.1'},{'approvedBy':'贾少辉','author':'吴慧','changesComments':'新增一列信息";
BA_ "GenMsgILSupport" BO_ 1095 1;
BA_ "GenMsgCycleTime" BO_ 1095 100;
BA_ "GenMsgSendType" BO_ 1095 0;
BA_ "CANFD_BRS" BO_ 1095 1;
BA_ "VFrameFormat" BO_ 1095 14;
BA_ "GRC_History" BO_ 1267 "[{'approvedBy':'贾少辉','author':'吴慧','changesComments':'刘标ICC接收端更新：整帧接收','date':'2024/12/3','ecu':'RRCR_1(0x4F3)','ecuName':'ICC','reviewedBy':'杨华','revision':'V2.1'},{'approvedBy':'贾少辉','author':'吴慧','changesComments':'新增一列信息";
BA_ "GenMsgILSupport" BO_ 1267 1;
BA_ "GenMsgCycleTime" BO_ 1267 100;
BA_ "GenMsgSendType" BO_ 1267 0;
BA_ "CANFD_BRS" BO_ 1267 1;
BA_ "VFrameFormat" BO_ 1267 14;
BA_ "GRC_History" BO_ 788 "[{'approvedBy':'贾少辉','author':'吴慧','changesComments':'ICC新增接收FCM_2_IHCfunctionSts刘标','date':'2024/10/31','ecu':'ADS_COM_2(0x314)','ecuName':'ICC','reviewedBy':'杨华','revision':'V1.3.1'},{'approvedBy':'贾少辉','author':'吴慧','changesComments'";
BA_ "GenMsgILSupport" BO_ 788 1;
BA_ "GenMsgCycleTime" BO_ 788 50;
BA_ "GenMsgSendType" BO_ 788 0;
BA_ "CANFD_BRS" BO_ 788 1;
BA_ "VFrameFormat" BO_ 788 14;
BA_ "GRC_History" BO_ 571 "[{'approvedBy':'贾少辉','author':'吴慧','changesComments':'ICC新增接收DirectionIndLeft和DirectionIndRight和LHTurnSW和RHTurnSW信号','date':'2024/11/29','ecu':'FLZCU_1(0x23B)','ecuName':'FLZCU,ICC','reviewedBy':'杨华','revision':'V2.0'},{'approvedBy':'贾少";
BA_ "GenMsgILSupport" BO_ 571 1;
BA_ "GenMsgCycleTime" BO_ 571 20;
BA_ "GenMsgSendType" BO_ 571 0;
BA_ "CANFD_BRS" BO_ 571 1;
BA_ "VFrameFormat" BO_ 571 14;
BA_ "GRC_History" BO_ 699 "[{'approvedBy':'贾少辉','author':'吴慧','changesComments':'同步DA网段，补充所有未填写的初始值,补充为0x0','date':'2024/12/12','ecu':'RZCU_2(0x2BB)','ecuName':'FLZCU,ICC,BBCM,EPC,CMSM','reviewedBy':'杨华','revision':'V2.1'},{'approvedBy':'贾少辉','author':";
BA_ "GenMsgILSupport" BO_ 699 1;
BA_ "GenMsgCycleTime" BO_ 699 20;
BA_ "GenMsgSendType" BO_ 699 0;
BA_ "CANFD_BRS" BO_ 699 1;
BA_ "VFrameFormat" BO_ 699 14;
BA_ "GRC_History" BO_ 787 "[{'approvedBy':'贾少辉','author':'吴慧','changesComments':'魏睿ICC新增接收ChrgHoodSts信号，充电口盖状态显示','date':'2025/1/6','ecu':'FRZCU_14(0x313)','ecuName':'ICC','reviewedBy':'杨华','revision':'V2.1'}]";
BA_ "GRC_ASIL" BO_ 787 3;
BA_ "GenMsgILSupport" BO_ 787 1;
BA_ "GenMsgCycleTime" BO_ 787 50;
BA_ "GenMsgSendType" BO_ 787 0;
BA_ "CANFD_BRS" BO_ 787 1;
BA_ "VFrameFormat" BO_ 787 14;
BA_ "GRC_History" BO_ 524 "[{'approvedBy':'贾少辉','author':'吴慧','changesComments':'枚举值新增ADS_6_Customize_buttonsFB信号0x4:HPA记忆泊车，ICC接收\n同步新增ADS_6_MEBStatus和ADS_6_MAAStatus无接收端','date':'2024/11/27','ecu':'ADS_6(0x20C)','ecuName':'ICC','reviewedBy':'杨华','re";
BA_ "GenMsgILSupport" BO_ 524 1;
BA_ "GenMsgCycleTime" BO_ 524 20;
BA_ "GenMsgSendType" BO_ 524 0;
BA_ "CANFD_BRS" BO_ 524 1;
BA_ "VFrameFormat" BO_ 524 14;
BA_ "GRC_History" BO_ 572 "[{'approvedBy':'贾少辉','author':'吴慧','changesComments':'变更信号名为ONEOBX_7_iTASAchMaxActTime同步汪苇更新','date':'2024/11/28','ecu':'ONEBOX_7(0x23C)','ecuName':'CGW','reviewedBy':'杨华','revision':'V2.0'},{'approvedBy':'贾少辉','author':'吴慧','chan";
BA_ "GenMsgILSupport" BO_ 572 1;
BA_ "GenMsgCycleTime" BO_ 572 20;
BA_ "GenMsgSendType" BO_ 572 0;
BA_ "CANFD_BRS" BO_ 572 1;
BA_ "VFrameFormat" BO_ 572 14;
BA_ "GRC_History" BO_ 1212 "[{'approvedBy':'贾少辉','author':'吴慧','changesComments':'同步CH网段新增信号，ICC接收VCU_3_G_ActWheelTorqueFA和VCU_3_G_ActWheelTorqueRA刘标朱钊','date':'2024/10/30','ecu':'VCU_3_G(0x4BC)','ecuName':'ICC,FLZCU,HCU','reviewedBy':'杨华','revision':'V1.3.1'";
BA_ "GenMsgILSupport" BO_ 1212 1;
BA_ "GenMsgCycleTime" BO_ 1212 100;
BA_ "GenMsgSendType" BO_ 1212 0;
BA_ "CANFD_BRS" BO_ 1212 1;
BA_ "VFrameFormat" BO_ 1212 14;
BA_ "GRC_History" BO_ 783 "[{'approvedBy':'贾少辉','author':'吴慧','changesComments':'新增路由转发，ICC新增接收ADCC_SysReadySts刘标','date':'2024/10/31','ecu':'ADS_COM_1(0x30F)','ecuName':'ICC','reviewedBy':'杨华','revision':'V1.3.1'},{'approvedBy':'贾少辉','author':'吴慧','change";
BA_ "GenMsgILSupport" BO_ 783 1;
BA_ "GenMsgCycleTime" BO_ 783 50;
BA_ "GenMsgSendType" BO_ 783 0;
BA_ "CANFD_BRS" BO_ 783 1;
BA_ "VFrameFormat" BO_ 783 14;
BA_ "GRC_History" BO_ 1110 "[{'approvedBy':'贾少辉','author':'吴慧','changesComments':'新增路由转发，ICC新增接收防盗信号魏睿','date':'2024/11/4','ecu':'IMMO_ICC_11(0x456)','ecuName':'ICC','reviewedBy':'杨华','revision':'V1.3.1'}]";
BA_ "GenMsgILSupport" BO_ 1110 1;
BA_ "GenMsgSendType" BO_ 1110 1;
BA_ "CANFD_BRS" BO_ 1110 1;
BA_ "VFrameFormat" BO_ 1110 14;
BA_ "GRC_History" BO_ 1149 "[{'approvedBy':'贾少辉','author':'吴慧','changesComments':'新增路由转发，ICC新增接收防盗信号魏睿','date':'2024/11/4','ecu':'IMMO_VCC_12(0x47D)','ecuName':'ICC','reviewedBy':'杨华','revision':'V1.3.1'}]";
BA_ "GenMsgILSupport" BO_ 1149 1;
BA_ "GenMsgSendType" BO_ 1149 1;
BA_ "CANFD_BRS" BO_ 1149 1;
BA_ "VFrameFormat" BO_ 1149 14;
BA_ "GRC_History" BO_ 1037 "[{'approvedBy':'贾少辉','author':'吴慧','changesComments':'新增路由转发，ICC新增接收ADS_RCTAWarn_Left和ADS_RCTAWarn_Rigth和ADS_FCTAWarn_Left和ADS_FCTAWarn_Right刘标','date':'2024/11/4','ecu':'ADAS_ZCU_1(0x40D)','ecuName':'ICC','reviewedBy':'杨华','revisi";
BA_ "GenMsgILSupport" BO_ 1037 1;
BA_ "GenMsgCycleTime" BO_ 1037 100;
BA_ "GenMsgSendType" BO_ 1037 0;
BA_ "CANFD_BRS" BO_ 1037 1;
BA_ "VFrameFormat" BO_ 1037 14;
BA_ "GRC_History" BO_ 943 "[{'approvedBy':'贾少辉','author':'吴慧','changesComments':'新增路由转发，ICC新增接收EGS信号D01P使用刘标','date':'2024/11/28','ecu':'CSA_3(0x3AF)','ecuName':'ICC','reviewedBy':'杨华','revision':'V2.0'}]";
BA_ "GenMsgILSupport" BO_ 943 1;
BA_ "GenMsgCycleTime" BO_ 943 50;
BA_ "GenMsgSendType" BO_ 943 0;
BA_ "CANFD_BRS" BO_ 943 1;
BA_ "VFrameFormat" BO_ 943 14;
BA_ "GRC_History" BO_ 1120 "[{'approvedBy':'贾少辉','author':'吴慧','changesComments':'ICC新增接收RLHS_2_AmbBrightness和RLHS_LiSwithReason，路由新增复制CH网段','date':'2024/11/29','ecu':'FLZCU_3(0x460)','ecuName':'FLZCU,ICC','reviewedBy':'杨华','revision':'V2.0'},{'approvedBy':'贾�";
BA_ "GenMsgILSupport" BO_ 1120 1;
BA_ "GenMsgCycleTime" BO_ 1120 100;
BA_ "GenMsgSendType" BO_ 1120 0;
BA_ "CANFD_BRS" BO_ 1120 1;
BA_ "VFrameFormat" BO_ 1120 14;
BA_ "GRC_History" BO_ 850 "[{'approvedBy':'贾少辉','author':'吴慧','changesComments':'ICC新增接收ASU_6_HMIFailFb_JT信号刘标，新增路由','date':'2024/11/29','ecu':'ASU_6(0x352)','ecuName':'ICC','reviewedBy':'杨华','revision':'V2.0'}]";
BA_ "GenMsgILSupport" BO_ 850 1;
BA_ "GenMsgCycleTime" BO_ 850 50;
BA_ "GenMsgSendType" BO_ 850 0;
BA_ "CANFD_BRS" BO_ 850 1;
BA_ "VFrameFormat" BO_ 850 14;
BA_ "GRC_History" BO_ 1199 "[{'approvedBy':'贾少辉','author':'吴慧','changesComments':'新增路由转发，ICC新增接收TCM_1_TrailerSts程永芳，根据拖挂状态判断屏蔽雷达报警音','date':'2025/1/2','ecu':'TCM_1(0x4AF)','ecuName':'ICC','reviewedBy':'杨华','revision':'V2.1'}]";
BA_ "GRC_ASIL" BO_ 1199 3;
BA_ "GenMsgILSupport" BO_ 1199 1;
BA_ "GenMsgCycleTime" BO_ 1199 100;
BA_ "GenMsgSendType" BO_ 1199 0;
BA_ "VFrameFormat" BO_ 1199 14;
BA_ "GenSigStartValue" SG_ 1224 BMS_HvBattCellVoltMax_Num 255;
BA_ "GenSigSendType" SG_ 1224 BMS_HvBattCellVoltMax_Num 0;
BA_ "GenSigStartValue" SG_ 1224 BMS_HvBattCellVoltMax 65534;
BA_ "GenSigSendType" SG_ 1224 BMS_HvBattCellVoltMax 0;
BA_ "GRC_Sig_ASIL" SG_ 1224 BMS_HvBattCellVoltMax 4;
BA_ "GenSigStartValue" SG_ 1224 BMS_HvBattCellVoltMin_Num 255;
BA_ "GenSigSendType" SG_ 1224 BMS_HvBattCellVoltMin_Num 0;
BA_ "GenSigStartValue" SG_ 1224 BMS_HvBattCellVoltMin 65534;
BA_ "GenSigSendType" SG_ 1224 BMS_HvBattCellVoltMin 0;
BA_ "GRC_Sig_ASIL" SG_ 1224 BMS_HvBattCellVoltMin 4;
BA_ "GenSigSendType" SG_ 1224 BMS_Chg_Sts 0;
BA_ "GenSigSendType" SG_ 1235 EPS_2_Steer_ReturnRmd_Sts 0;
BA_ "GenSigSendType" SG_ 1235 EPS_2_Steer_ReturnRmd 0;
BA_ "GenSigSendType" SG_ 1235 EPS_2_MFS_ShakeSts 0;
BA_ "GenSigSendType" SG_ 1330 DWD_TextDisp 0;
BA_ "GenSigSendType" SG_ 1330 DWD_SoundIndcn 0;
BA_ "GenSigSendType" SG_ 1330 LSensorFailSts 0;
BA_ "GenSigSendType" SG_ 1330 RSensorFailSts 0;
BA_ "GenSigSendType" SG_ 1330 DWD_Distance 0;
BA_ "GenSigSendType" SG_ 1330 DWD_Switch 0;
BA_ "E2EDataLength" SG_ 1328 RADAR_1_RadarDetectSts 64;
BA_ "E2EProfile" SG_ 1328 RADAR_1_RadarDetectSts "P01";
BA_ "E2EDataId" SG_ 1328 RADAR_1_RadarDetectSts 73;
BA_ "GenSigSendType" SG_ 1328 RADAR_1_RadarDetectSts 0;
BA_ "E2EDataLength" SG_ 1328 RADAR_1_RadarWorkSts 64;
BA_ "E2EProfile" SG_ 1328 RADAR_1_RadarWorkSts "P01";
BA_ "E2EDataId" SG_ 1328 RADAR_1_RadarWorkSts 73;
BA_ "GenSigSendType" SG_ 1328 RADAR_1_RadarWorkSts 0;
BA_ "E2EDataLength" SG_ 1328 RADAR_1_Resd1 64;
BA_ "E2EProfile" SG_ 1328 RADAR_1_Resd1 "P01";
BA_ "E2EDataId" SG_ 1328 RADAR_1_Resd1 73;
BA_ "GenSigSendType" SG_ 1328 RADAR_1_Resd1 0;
BA_ "E2EDataLength" SG_ 1328 RADAR_1_LHRRadarSensorDistance 64;
BA_ "E2EProfile" SG_ 1328 RADAR_1_LHRRadarSensorDistance "P01";
BA_ "E2EDataId" SG_ 1328 RADAR_1_LHRRadarSensorDistance 73;
BA_ "GenSigStartValue" SG_ 1328 RADAR_1_LHRRadarSensorDistance 62;
BA_ "GenSigSendType" SG_ 1328 RADAR_1_LHRRadarSensorDistance 0;
BA_ "E2EDataLength" SG_ 1328 RADAR_1_RHMRRadarSensorDistance 64;
BA_ "E2EProfile" SG_ 1328 RADAR_1_RHMRRadarSensorDistance "P01";
BA_ "E2EDataId" SG_ 1328 RADAR_1_RHMRRadarSensorDistance 73;
BA_ "GenSigStartValue" SG_ 1328 RADAR_1_RHMRRadarSensorDistance 62;
BA_ "GenSigSendType" SG_ 1328 RADAR_1_RHMRRadarSensorDistance 0;
BA_ "E2EDataLength" SG_ 1328 RADAR_1_LHMRRadarSensorDistance 64;
BA_ "E2EProfile" SG_ 1328 RADAR_1_LHMRRadarSensorDistance "P01";
BA_ "E2EDataId" SG_ 1328 RADAR_1_LHMRRadarSensorDistance 73;
BA_ "GenSigStartValue" SG_ 1328 RADAR_1_LHMRRadarSensorDistance 62;
BA_ "GenSigSendType" SG_ 1328 RADAR_1_LHMRRadarSensorDistance 0;
BA_ "E2EDataLength" SG_ 1328 RADAR_1_RHRRadarSensorDistance 64;
BA_ "E2EProfile" SG_ 1328 RADAR_1_RHRRadarSensorDistance "P01";
BA_ "E2EDataId" SG_ 1328 RADAR_1_RHRRadarSensorDistance 73;
BA_ "GenSigStartValue" SG_ 1328 RADAR_1_RHRRadarSensorDistance 62;
BA_ "GenSigSendType" SG_ 1328 RADAR_1_RHRRadarSensorDistance 0;
BA_ "E2EDataLength" SG_ 1328 RADAR_1_LHFRadarSensorDistance 64;
BA_ "E2EProfile" SG_ 1328 RADAR_1_LHFRadarSensorDistance "P01";
BA_ "E2EDataId" SG_ 1328 RADAR_1_LHFRadarSensorDistance 73;
BA_ "GenSigStartValue" SG_ 1328 RADAR_1_LHFRadarSensorDistance 30;
BA_ "GenSigSendType" SG_ 1328 RADAR_1_LHFRadarSensorDistance 0;
BA_ "E2EDataLength" SG_ 1328 RADAR_1_RHFRadarSensorDistance 64;
BA_ "E2EProfile" SG_ 1328 RADAR_1_RHFRadarSensorDistance "P01";
BA_ "E2EDataId" SG_ 1328 RADAR_1_RHFRadarSensorDistance 73;
BA_ "GenSigStartValue" SG_ 1328 RADAR_1_RHFRadarSensorDistance 30;
BA_ "GenSigSendType" SG_ 1328 RADAR_1_RHFRadarSensorDistance 0;
BA_ "E2EDataLength" SG_ 1328 RADAR_1_ParkingRadarSwSts 64;
BA_ "E2EProfile" SG_ 1328 RADAR_1_ParkingRadarSwSts "P01";
BA_ "E2EDataId" SG_ 1328 RADAR_1_ParkingRadarSwSts 73;
BA_ "GenSigSendType" SG_ 1328 RADAR_1_ParkingRadarSwSts 0;
BA_ "E2EDataLength" SG_ 1328 RADAR_1_RHMFRadarSensorDistance 64;
BA_ "E2EProfile" SG_ 1328 RADAR_1_RHMFRadarSensorDistance "P01";
BA_ "E2EDataId" SG_ 1328 RADAR_1_RHMFRadarSensorDistance 73;
BA_ "GenSigStartValue" SG_ 1328 RADAR_1_RHMFRadarSensorDistance 30;
BA_ "GenSigSendType" SG_ 1328 RADAR_1_RHMFRadarSensorDistance 0;
BA_ "E2EDataLength" SG_ 1328 RADAR_1_LHMFRadarSensorDistance 64;
BA_ "E2EProfile" SG_ 1328 RADAR_1_LHMFRadarSensorDistance "P01";
BA_ "E2EDataId" SG_ 1328 RADAR_1_LHMFRadarSensorDistance 73;
BA_ "GenSigStartValue" SG_ 1328 RADAR_1_LHMFRadarSensorDistance 30;
BA_ "GenSigSendType" SG_ 1328 RADAR_1_LHMFRadarSensorDistance 0;
BA_ "E2EDataLength" SG_ 1328 RADAR_1_AudibleBeepRate 64;
BA_ "E2EProfile" SG_ 1328 RADAR_1_AudibleBeepRate "P01";
BA_ "E2EDataId" SG_ 1328 RADAR_1_AudibleBeepRate 73;
BA_ "GenSigSendType" SG_ 1328 RADAR_1_AudibleBeepRate 0;
BA_ "GenSigInvalidValue" SG_ 259 EMS_EngineSpeed_Actual 65535;
BA_ "GenSigSendType" SG_ 259 EMS_EngineSpeed_Actual 0;
BA_ "GRC_Sig_ASIL" SG_ 259 EMS_EngineSpeed_Actual 2;
BA_ "GenSigInvalidValue" SG_ 1234 FRZCU_FRSeatHeiFb 127;
BA_ "GenSigSendType" SG_ 1234 FRZCU_FRSeatHeiFb 0;
BA_ "GenSigInvalidValue" SG_ 1234 FRZCU_FRSeatLvlFb 127;
BA_ "GenSigSendType" SG_ 1234 FRZCU_FRSeatLvlFb 0;
BA_ "GenSigInvalidValue" SG_ 1234 FRZCU_FRSeatBackAgFb 127;
BA_ "GenSigSendType" SG_ 1234 FRZCU_FRSeatBackAgFb 0;
BA_ "GenSigInvalidValue" SG_ 1234 FRZCU_FRSeatLegSpprtFb 127;
BA_ "GenSigSendType" SG_ 1234 FRZCU_FRSeatLegSpprtFb 0;
BA_ "GenSigSendType" SG_ 1234 FRZCU_FRWinSts 0;
BA_ "GenSigSendType" SG_ 1234 FRZCU_RRWinSts 0;
BA_ "GenSigInvalidValue" SG_ 1234 FRZCU_FRSeatLegRestAngleFb 127;
BA_ "GenSigSendType" SG_ 1234 FRZCU_FRSeatLegRestAngleFb 0;
BA_ "GenSigInvalidValue" SG_ 1234 FRZCU_FRSeatCushFb 127;
BA_ "GenSigSendType" SG_ 1234 FRZCU_FRSeatCushFb 0;
BA_ "GenSigSendType" SG_ 1234 FRZCU_FRSeatNeedMemory 0;
BA_ "GenSigSendType" SG_ 1234 FRZCU_FRMemoryFb 0;
BA_ "GenSigSendType" SG_ 1234 FRZCU_FRRecoverFb 0;
BA_ "GenSigSendType" SG_ 1234 FRZCU_EasyEntryExitFb 0;
BA_ "GenSigSendType" SG_ 1234 FRZCU_EnjoyableSeatWarning 0;
BA_ "GenSigSendType" SG_ 1234 FRZCU_EnjoyableSeatSts 0;
BA_ "GenSigSendType" SG_ 1234 SeatHeatLevelsFR 0;
BA_ "GenSigSendType" SG_ 1234 SeatVentLevelsFR 0;
BA_ "GenSigSendType" SG_ 1234 SeatHeatLevelsRR 0;
BA_ "GenSigSendType" SG_ 1234 SeatVentLevelsRR 0;
BA_ "GenSigInvalidValue" SG_ 1234 FRZCU_FRSeatFoldFb 127;
BA_ "GenSigSendType" SG_ 1234 FRZCU_FRSeatFoldFb 0;
BA_ "GenSigSendType" SG_ 517 MFSR_UP_SW 0;
BA_ "GenSigSendType" SG_ 517 MFSR_DW_SW 0;
BA_ "GenSigSendType" SG_ 517 MFSR_Left_SW 0;
BA_ "GenSigSendType" SG_ 517 MFSR_Right_SW 0;
BA_ "GenSigSendType" SG_ 517 MFSR_OK_SW 0;
BA_ "GenSigSendType" SG_ 517 MFSR_Voice_SW 0;
BA_ "GenSigSendType" SG_ 517 MFSR_Customize 0;
BA_ "GenSigSendType" SG_ 1096 TMS_AutoDefogActiveSts 0;
BA_ "GenSigSendType" SG_ 1096 TMS_AirPurgeReminderSts 0;
BA_ "GenSigSendType" SG_ 1096 TMS_BT_Reduce_Wind_SpeedSts 0;
BA_ "GenSigSendType" SG_ 1096 TMS_First_BlowingSts 0;
BA_ "GenSigSendType" SG_ 1096 TMS_CirculationInTunnelsSts 0;
BA_ "GenSigSendType" SG_ 1096 TMS_crosscountry_coolingSts 0;
BA_ "GenSigSendType" SG_ 1096 TMS_ParkingAirConditioningStatus 0;
BA_ "GenSigSendType" SG_ 1096 TMS_CoolantFillSts 0;
BA_ "GenSigSendType" SG_ 1096 TMS_UVC_ControlSts 0;
BA_ "GenSigSendType" SG_ 1096 TMS_UVC_LuminanceSts 0;
BA_ "GenSigSendType" SG_ 1096 TMS_ICC_Lightoff_Sts 0;
BA_ "GenSigSendType" SG_ 1096 TMS_ICC_Memoff_Sts 0;
BA_ "GenSigSendType" SG_ 1096 TMS_keepwarmSet_TemperatureSts 0;
BA_ "GenSigSendType" SG_ 1096 TMS_BiochemicalFuncSts 0;
BA_ "GenSigSendType" SG_ 1096 TMS_TimedVentilationSts 0;
BA_ "GenSigSendType" SG_ 1240 TMS_CFSSwitchFb 0;
BA_ "GenSigStartValue" SG_ 1240 TDU_CFSPosOneType 15;
BA_ "GenSigSendType" SG_ 1240 TDU_CFSPosOneType 0;
BA_ "GenSigStartValue" SG_ 1240 TDU_CFSPosTwoType 15;
BA_ "GenSigSendType" SG_ 1240 TDU_CFSPosTwoType 0;
BA_ "GenSigStartValue" SG_ 1240 TDU_CFSPosThreeType 15;
BA_ "GenSigSendType" SG_ 1240 TDU_CFSPosThreeType 0;
BA_ "GenSigStartValue" SG_ 1240 TDU_CFSRunOut 15;
BA_ "GenSigSendType" SG_ 1240 TDU_CFSRunOut 0;
BA_ "GenSigStartValue" SG_ 1240 TMS_CFSShortWarn 15;
BA_ "GenSigSendType" SG_ 1240 TMS_CFSShortWarn 0;
BA_ "GenSigSendType" SG_ 1240 TMS_CFSLevelSetFb 0;
BA_ "GenSigSendType" SG_ 1240 TMS_CFSPosSetFb 0;
BA_ "GenSigInvalidValue" SG_ 1240 TMS_CFSPosOneLife 255;
BA_ "GenSigSendType" SG_ 1240 TMS_CFSPosOneLife 0;
BA_ "GenSigInvalidValue" SG_ 1240 TMS_CFSPosTwoLife 255;
BA_ "GenSigSendType" SG_ 1240 TMS_CFSPosTwoLife 0;
BA_ "GenSigInvalidValue" SG_ 1240 TMS_CFSPosThreeLife 255;
BA_ "GenSigSendType" SG_ 1240 TMS_CFSPosThreeLife 0;
BA_ "GenSigSendType" SG_ 1240 TMS_PM25SwitchFb 0;
BA_ "GenSigStartValue" SG_ 1240 TMS_ThrModeStsFb 7;
BA_ "GenSigSendType" SG_ 1240 TMS_ThrModeStsFb 0;
BA_ "GenSigStartValue" SG_ 1240 TMS_ThrSetTempFb_C 31;
BA_ "GenSigInvalidValue" SG_ 1240 TMS_ThrSetTempFb_C 31;
BA_ "GenSigSendType" SG_ 1240 TMS_ThrSetTempFb_C 0;
BA_ "GenSigSendType" SG_ 1240 TMS_ThrCLMSwitchFb 0;
BA_ "GenSigSendType" SG_ 1240 TMS_ThrAutoSwitchFb 0;
BA_ "GenSigSendType" SG_ 1240 TMS_ThrBlowSpeedLevelKeyStsFb 0;
BA_ "GenSigSendType" SG_ 638 FRZCU_HoodSts 0;
BA_ "GenSigSendType" SG_ 638 FRZCU_AuthenResult 0;
BA_ "GenSigSendType" SG_ 638 FRZCU_PowerMode 0;
BA_ "GenSigSendType" SG_ 638 FRZCU_TrunkSts 0;
BA_ "GenSigSendType" SG_ 638 FRZCU_HandleSwitchStsFL 0;
BA_ "GenSigSendType" SG_ 638 FRZCU_HandleSwitchStsFR 0;
BA_ "GenSigSendType" SG_ 638 FRZCU_HandleSwitchStsRR 0;
BA_ "GenSigSendType" SG_ 638 FRZCU_HandleSwitchStsRL 0;
BA_ "GenSigSendType" SG_ 638 SeatLength_target_Passenger 0;
BA_ "GenSigSendType" SG_ 638 SeatBackrest_target_Passenger 0;
BA_ "GenSigStartValue" SG_ 638 FRZCU_TrunkLockSts 3;
BA_ "GenSigSendType" SG_ 638 FRZCU_TrunkLockSts 0;
BA_ "GenSigStartValue" SG_ 638 FRZCU_HoodLockSts 3;
BA_ "GenSigSendType" SG_ 638 FRZCU_HoodLockSts 0;
BA_ "GenSigSendType" SG_ 638 FrontBackSpeedAdj_Cmd 0;
BA_ "GenSigSendType" SG_ 638 FRZCU_GloveboxSW 0;
BA_ "GenSigSendType" SG_ 638 FRZCU_FRReleaseLockSts 0;
BA_ "GenSigSendType" SG_ 638 FRZCU_RRReleaseLockSts 0;
BA_ "GenSigSendType" SG_ 638 FRZCU_PELockInKeyWarning 0;
BA_ "GenSigSendType" SG_ 638 FRZCU_PowerOFFWarning 0;
BA_ "GenSigSendType" SG_ 638 FRZCU_KeylessWarning 0;
BA_ "GenSigSendType" SG_ 638 FRZCU_OTAPwrDwnReqFb 0;
BA_ "GenSigSendType" SG_ 638 FRZCU_OTAPwrOnReqFb 0;
BA_ "GenSigSendType" SG_ 949 PEPS_InformationSource 0;
BA_ "GenSigSendType" SG_ 949 PEPS_OrderInformation 0;
BA_ "GenSigSendType" SG_ 949 PEPS_IDInformation 0;
BA_ "GenSigSendType" SG_ 949 PEPS_KeySts 0;
BA_ "GenSigSendType" SG_ 949 PEPS_ETRUnLockReq 4;
BA_ "GenSigSendType" SG_ 1028 PEPS_WelcomeON 4;
BA_ "GenSigSendType" SG_ 1028 PEPS_VehicleSearchReq 4;
BA_ "GenSigSendType" SG_ 1028 PEPS_SATOReminder 4;
BA_ "GenSigSendType" SG_ 1028 PEPS_PLGUnlockReq 4;
BA_ "GenSigSendType" SG_ 1028 PEPS_RKETrunkSts 0;
BA_ "GenSigSendType" SG_ 1028 PEPS_SSBInhibitCWCSts 0;
BA_ "GenSigSendType" SG_ 1028 PEPS_WirelessChargingCtrSts 0;
BA_ "GenSigSendType" SG_ 1028 PEPS_EmgyShutdown 0;
BA_ "GenSigSendType" SG_ 1028 PEPS_SSBInputFailure 0;
BA_ "GenSigSendType" SG_ 1028 PEPS_SmartSystemWarning1_1 0;
BA_ "GenSigSendType" SG_ 1028 PEPS_SmartSystemWarning2_2 0;
BA_ "GenSigSendType" SG_ 1028 PEPS_SmartSystemWarning3_1 0;
BA_ "GenSigSendType" SG_ 1028 PEPS_SmartSystemWarning3_2 0;
BA_ "GenSigSendType" SG_ 1028 PEPS_SmartSystemWarning4_2 0;
BA_ "GenSigSendType" SG_ 1028 PEPS_SmartSystemWarning4_3 0;
BA_ "GenSigSendType" SG_ 1028 PEPS_SystemWarning 0;
BA_ "GenSigSendType" SG_ 1028 PEPS_BLTKeyPESts 0;
BA_ "E2EDataLength" SG_ 1291 BMS_2_G_CRC 64;
BA_ "E2EProfile" SG_ 1291 BMS_2_G_CRC "P01";
BA_ "E2EDataId" SG_ 1291 BMS_2_G_CRC 117;
BA_ "GenSigSendType" SG_ 1291 BMS_2_G_CRC 0;
BA_ "E2EDataLength" SG_ 1291 BMS_2_G_RollgCntr 64;
BA_ "E2EProfile" SG_ 1291 BMS_2_G_RollgCntr "P01";
BA_ "E2EDataId" SG_ 1291 BMS_2_G_RollgCntr 117;
BA_ "GenSigSendType" SG_ 1291 BMS_2_G_RollgCntr 0;
BA_ "E2EDataLength" SG_ 1291 BMS_2_G_Resd 64;
BA_ "E2EProfile" SG_ 1291 BMS_2_G_Resd "P01";
BA_ "E2EDataId" SG_ 1291 BMS_2_G_Resd 117;
BA_ "GenSigSendType" SG_ 1291 BMS_2_G_Resd 0;
BA_ "E2EDataLength" SG_ 1291 BMS_TBOXInsulation_R 64;
BA_ "E2EProfile" SG_ 1291 BMS_TBOXInsulation_R "P01";
BA_ "E2EDataId" SG_ 1291 BMS_TBOXInsulation_R 117;
BA_ "GenSigSendType" SG_ 1291 BMS_TBOXInsulation_R 0;
BA_ "E2EDataLength" SG_ 1291 BMS_TBOXErrorNumber 64;
BA_ "E2EProfile" SG_ 1291 BMS_TBOXErrorNumber "P01";
BA_ "E2EDataId" SG_ 1291 BMS_TBOXErrorNumber 117;
BA_ "GenSigSendType" SG_ 1291 BMS_TBOXErrorNumber 0;
BA_ "E2EDataLength" SG_ 1291 BMS_TBOXHvBattMaxT 64;
BA_ "E2EProfile" SG_ 1291 BMS_TBOXHvBattMaxT "P01";
BA_ "E2EDataId" SG_ 1291 BMS_TBOXHvBattMaxT 117;
BA_ "GenSigStartValue" SG_ 1291 BMS_TBOXHvBattMaxT 255;
BA_ "GenSigSendType" SG_ 1291 BMS_TBOXHvBattMaxT 0;
BA_ "E2EDataLength" SG_ 1291 BMS_TBOXHvBattMinT 64;
BA_ "E2EProfile" SG_ 1291 BMS_TBOXHvBattMinT "P01";
BA_ "E2EDataId" SG_ 1291 BMS_TBOXHvBattMinT 117;
BA_ "GenSigStartValue" SG_ 1291 BMS_TBOXHvBattMinT 255;
BA_ "GenSigSendType" SG_ 1291 BMS_TBOXHvBattMinT 0;
BA_ "E2EDataLength" SG_ 1291 BMS_SOCLight 64;
BA_ "E2EProfile" SG_ 1291 BMS_SOCLight "P01";
BA_ "E2EDataId" SG_ 1291 BMS_SOCLight 117;
BA_ "GenSigInvalidValue" SG_ 1291 BMS_SOCLight 127;
BA_ "GenSigSendType" SG_ 1291 BMS_SOCLight 0;
BA_ "GRC_Sig_ASIL" SG_ 1291 BMS_SOCLight 3;
BA_ "E2EDataLength" SG_ 1104 RLCR_2_CRC1 64;
BA_ "E2EProfile" SG_ 1104 RLCR_2_CRC1 "P01";
BA_ "E2EDataId" SG_ 1104 RLCR_2_CRC1 69;
BA_ "GenSigSendType" SG_ 1104 RLCR_2_CRC1 0;
BA_ "E2EDataLength" SG_ 1104 RLCR_2_RollgCntr1 64;
BA_ "E2EProfile" SG_ 1104 RLCR_2_RollgCntr1 "P01";
BA_ "E2EDataId" SG_ 1104 RLCR_2_RollgCntr1 69;
BA_ "GenSigSendType" SG_ 1104 RLCR_2_RollgCntr1 0;
BA_ "E2EDataLength" SG_ 1104 RLCR_2_Resd1 64;
BA_ "E2EProfile" SG_ 1104 RLCR_2_Resd1 "P01";
BA_ "E2EDataId" SG_ 1104 RLCR_2_Resd1 69;
BA_ "GenSigSendType" SG_ 1104 RLCR_2_Resd1 0;
BA_ "E2EDataLength" SG_ 1104 RLCR_2_RCWWarn 64;
BA_ "E2EProfile" SG_ 1104 RLCR_2_RCWWarn "P01";
BA_ "E2EDataId" SG_ 1104 RLCR_2_RCWWarn 69;
BA_ "GenSigSendType" SG_ 1104 RLCR_2_RCWWarn 0;
BA_ "E2EDataLength" SG_ 1104 RLCR_2_RCTAWarn 64;
BA_ "E2EProfile" SG_ 1104 RLCR_2_RCTAWarn "P01";
BA_ "E2EDataId" SG_ 1104 RLCR_2_RCTAWarn 69;
BA_ "GenSigSendType" SG_ 1104 RLCR_2_RCTAWarn 0;
BA_ "E2EDataLength" SG_ 1104 RLCR_2_BSDLCWONOFFSts 64;
BA_ "E2EProfile" SG_ 1104 RLCR_2_BSDLCWONOFFSts "P01";
BA_ "E2EDataId" SG_ 1104 RLCR_2_BSDLCWONOFFSts 69;
BA_ "GenSigSendType" SG_ 1104 RLCR_2_BSDLCWONOFFSts 0;
BA_ "E2EDataLength" SG_ 1104 RLCR_2_DOWONOFFSts 64;
BA_ "E2EProfile" SG_ 1104 RLCR_2_DOWONOFFSts "P01";
BA_ "E2EDataId" SG_ 1104 RLCR_2_DOWONOFFSts 69;
BA_ "GenSigSendType" SG_ 1104 RLCR_2_DOWONOFFSts 0;
BA_ "E2EDataLength" SG_ 1104 RLCR_2_RCWONOFFSts 64;
BA_ "E2EProfile" SG_ 1104 RLCR_2_RCWONOFFSts "P01";
BA_ "E2EDataId" SG_ 1104 RLCR_2_RCWONOFFSts 69;
BA_ "GenSigSendType" SG_ 1104 RLCR_2_RCWONOFFSts 0;
BA_ "E2EDataLength" SG_ 1104 RLCR_2_RCTARCTBONOFFSts 64;
BA_ "E2EProfile" SG_ 1104 RLCR_2_RCTARCTBONOFFSts "P01";
BA_ "E2EDataId" SG_ 1104 RLCR_2_RCTARCTBONOFFSts 69;
BA_ "GenSigSendType" SG_ 1104 RLCR_2_RCTARCTBONOFFSts 0;
BA_ "E2EDataLength" SG_ 1271 RRCR_2_CRC1 64;
BA_ "E2EProfile" SG_ 1271 RRCR_2_CRC1 "P01";
BA_ "E2EDataId" SG_ 1271 RRCR_2_CRC1 71;
BA_ "GenSigSendType" SG_ 1271 RRCR_2_CRC1 0;
BA_ "E2EDataLength" SG_ 1271 RRCR_2_RollgCntr1 64;
BA_ "E2EProfile" SG_ 1271 RRCR_2_RollgCntr1 "P01";
BA_ "E2EDataId" SG_ 1271 RRCR_2_RollgCntr1 71;
BA_ "GenSigSendType" SG_ 1271 RRCR_2_RollgCntr1 0;
BA_ "E2EDataLength" SG_ 1271 RRCR_2_Resd1 64;
BA_ "E2EProfile" SG_ 1271 RRCR_2_Resd1 "P01";
BA_ "E2EDataId" SG_ 1271 RRCR_2_Resd1 71;
BA_ "GenSigSendType" SG_ 1271 RRCR_2_Resd1 0;
BA_ "E2EDataLength" SG_ 1271 RRCR_2_RCWWarn 64;
BA_ "E2EProfile" SG_ 1271 RRCR_2_RCWWarn "P01";
BA_ "E2EDataId" SG_ 1271 RRCR_2_RCWWarn 71;
BA_ "GenSigSendType" SG_ 1271 RRCR_2_RCWWarn 0;
BA_ "E2EDataLength" SG_ 1271 RRCR_2_RCTAWarn 64;
BA_ "E2EProfile" SG_ 1271 RRCR_2_RCTAWarn "P01";
BA_ "E2EDataId" SG_ 1271 RRCR_2_RCTAWarn 71;
BA_ "GenSigSendType" SG_ 1271 RRCR_2_RCTAWarn 0;
BA_ "E2EDataLength" SG_ 1271 RRCR_2_BSDLCWONOFFSts 64;
BA_ "E2EProfile" SG_ 1271 RRCR_2_BSDLCWONOFFSts "P01";
BA_ "E2EDataId" SG_ 1271 RRCR_2_BSDLCWONOFFSts 71;
BA_ "GenSigSendType" SG_ 1271 RRCR_2_BSDLCWONOFFSts 0;
BA_ "E2EDataLength" SG_ 1271 RRCR_2_DOWONOFFSts 64;
BA_ "E2EProfile" SG_ 1271 RRCR_2_DOWONOFFSts "P01";
BA_ "E2EDataId" SG_ 1271 RRCR_2_DOWONOFFSts 71;
BA_ "GenSigSendType" SG_ 1271 RRCR_2_DOWONOFFSts 0;
BA_ "E2EDataLength" SG_ 1271 RRCR_2_RCWONOFFSts 64;
BA_ "E2EProfile" SG_ 1271 RRCR_2_RCWONOFFSts "P01";
BA_ "E2EDataId" SG_ 1271 RRCR_2_RCWONOFFSts 71;
BA_ "GenSigSendType" SG_ 1271 RRCR_2_RCWONOFFSts 0;
BA_ "E2EDataLength" SG_ 1271 RRCR_2_RCTARCTBONOFFSts 64;
BA_ "E2EProfile" SG_ 1271 RRCR_2_RCTARCTBONOFFSts "P01";
BA_ "E2EDataId" SG_ 1271 RRCR_2_RCTARCTBONOFFSts 71;
BA_ "GenSigSendType" SG_ 1271 RRCR_2_RCTARCTBONOFFSts 0;
BA_ "GenSigSendType" SG_ 587 IPB_SandABSSwSts_24Bh 0;
BA_ "GenSigSendType" SG_ 587 IPB_SandABSAvl_24Bh 0;
BA_ "GenSigInvalidValue" SG_ 587 ONEBOX_4_LHFWheelSpeedRPM 65535;
BA_ "GenSigSendType" SG_ 587 ONEBOX_4_LHFWheelSpeedRPM 0;
BA_ "GRC_Sig_ASIL" SG_ 587 ONEBOX_4_LHFWheelSpeedRPM 5;
BA_ "GenSigInvalidValue" SG_ 587 ONEBOX_4_RHFWheelSpeedRPM 65535;
BA_ "GenSigSendType" SG_ 587 ONEBOX_4_RHFWheelSpeedRPM 0;
BA_ "GRC_Sig_ASIL" SG_ 587 ONEBOX_4_RHFWheelSpeedRPM 5;
BA_ "GenSigInvalidValue" SG_ 587 LHRWheelSpeedRPM 65535;
BA_ "GenSigSendType" SG_ 587 LHRWheelSpeedRPM 0;
BA_ "GRC_Sig_ASIL" SG_ 587 LHRWheelSpeedRPM 3;
BA_ "GenSigInvalidValue" SG_ 587 RHRWheelSpeedRPM 65535;
BA_ "GenSigSendType" SG_ 587 RHRWheelSpeedRPM 0;
BA_ "GRC_Sig_ASIL" SG_ 587 RHRWheelSpeedRPM 3;
BA_ "GenSigSendType" SG_ 587 LHRPulseCounterFailSts 0;
BA_ "GRC_Sig_ASIL" SG_ 587 LHRPulseCounterFailSts 3;
BA_ "GenSigSendType" SG_ 587 LHRPulseCounter 0;
BA_ "GRC_Sig_ASIL" SG_ 587 LHRPulseCounter 3;
BA_ "GenSigSendType" SG_ 587 RHRPulseCounterFailSts 0;
BA_ "GRC_Sig_ASIL" SG_ 587 RHRPulseCounterFailSts 3;
BA_ "GenSigSendType" SG_ 587 RHRPulseCounter 0;
BA_ "GRC_Sig_ASIL" SG_ 587 RHRPulseCounter 3;
BA_ "GenSigSendType" SG_ 587 RHFPulseCounterFailSts 0;
BA_ "GRC_Sig_ASIL" SG_ 587 RHFPulseCounterFailSts 3;
BA_ "GenSigSendType" SG_ 587 RHFPulseCounter 0;
BA_ "GRC_Sig_ASIL" SG_ 587 RHFPulseCounter 3;
BA_ "GenSigSendType" SG_ 587 LHFPulseCounterFailSts 0;
BA_ "GRC_Sig_ASIL" SG_ 587 LHFPulseCounterFailSts 3;
BA_ "GenSigSendType" SG_ 587 LHFPulseCounter 0;
BA_ "GRC_Sig_ASIL" SG_ 587 LHFPulseCounter 3;
BA_ "GenSigInvalidValue" SG_ 587 LHFWheelDriveDirection 4;
BA_ "GenSigSendType" SG_ 587 LHFWheelDriveDirection 0;
BA_ "GRC_Sig_ASIL" SG_ 587 LHFWheelDriveDirection 3;
BA_ "GenSigInvalidValue" SG_ 587 RHFWheelDriveDirection 4;
BA_ "GenSigSendType" SG_ 587 RHFWheelDriveDirection 0;
BA_ "GRC_Sig_ASIL" SG_ 587 RHFWheelDriveDirection 3;
BA_ "GenSigInvalidValue" SG_ 587 LHRWheelDriveDirection 4;
BA_ "GenSigSendType" SG_ 587 LHRWheelDriveDirection 0;
BA_ "GRC_Sig_ASIL" SG_ 587 LHRWheelDriveDirection 3;
BA_ "GenSigInvalidValue" SG_ 587 RHRWheelDriveDirection 4;
BA_ "GenSigSendType" SG_ 587 RHRWheelDriveDirection 0;
BA_ "GRC_Sig_ASIL" SG_ 587 RHRWheelDriveDirection 3;
BA_ "GenSigSendType" SG_ 1338 FMCU_ErrLvlDis 0;
BA_ "GenSigStartValue" SG_ 1338 FMCU_SpdAct_EDR 32767;
BA_ "GenSigInvalidValue" SG_ 1338 FMCU_SpdAct_EDR 65535;
BA_ "GenSigSendType" SG_ 1338 FMCU_SpdAct_EDR 0;
BA_ "GenSigSendType" SG_ 777 ISGF_ErrLvl 0;
BA_ "GenSigSendType" SG_ 1403 RMCU_ErrLvlDis 0;
BA_ "GenSigSendType" SG_ 1403 RMCU_Speed_EDR 0;
BA_ "GenSigStartValue" SG_ 1299 BMS_PackVoltageDis 65535;
BA_ "GenSigInvalidValue" SG_ 1299 BMS_PackVoltageDis 65535;
BA_ "GenSigSendType" SG_ 1299 BMS_PackVoltageDis 0;
BA_ "GenSigStartValue" SG_ 1299 BMS_PackCurrentDis 65535;
BA_ "GenSigInvalidValue" SG_ 1299 BMS_PackCurrentDis 65535;
BA_ "GenSigSendType" SG_ 1299 BMS_PackCurrentDis 0;
BA_ "GenSigSendType" SG_ 1099 ISGF_SysTempOvrInd 0;
BA_ "GenSigSendType" SG_ 1130 TCU_23_GBFaultstatus 0;
BA_ "GenSigSendType" SG_ 1130 TCU_23_TeachInState 0;
BA_ "GRC_Sig_ASIL" SG_ 1130 TCU_23_TeachInState 1;
BA_ "E2EDataLength" SG_ 1180 New_Signal_49C_8 64;
BA_ "E2EProfile" SG_ 1180 New_Signal_49C_8 "P01";
BA_ "E2EDataId" SG_ 1180 New_Signal_49C_8 173;
BA_ "GenSigSendType" SG_ 1180 New_Signal_49C_8 0;
BA_ "E2EDataLength" SG_ 1180 New_Signal_49C_7 64;
BA_ "E2EProfile" SG_ 1180 New_Signal_49C_7 "P01";
BA_ "E2EDataId" SG_ 1180 New_Signal_49C_7 173;
BA_ "GenSigSendType" SG_ 1180 New_Signal_49C_7 0;
BA_ "E2EDataLength" SG_ 1180 New_Signal_49C_6 64;
BA_ "E2EProfile" SG_ 1180 New_Signal_49C_6 "P01";
BA_ "E2EDataId" SG_ 1180 New_Signal_49C_6 173;
BA_ "GenSigSendType" SG_ 1180 New_Signal_49C_6 0;
BA_ "E2EDataLength" SG_ 1180 New_Signal_49C_5 64;
BA_ "E2EProfile" SG_ 1180 New_Signal_49C_5 "P01";
BA_ "E2EDataId" SG_ 1180 New_Signal_49C_5 173;
BA_ "GenSigSendType" SG_ 1180 New_Signal_49C_5 0;
BA_ "E2EDataLength" SG_ 1180 New_Signal_49C_4 64;
BA_ "E2EProfile" SG_ 1180 New_Signal_49C_4 "P01";
BA_ "E2EDataId" SG_ 1180 New_Signal_49C_4 173;
BA_ "GenSigSendType" SG_ 1180 New_Signal_49C_4 0;
BA_ "E2EDataLength" SG_ 1180 New_Signal_49C_3 64;
BA_ "E2EProfile" SG_ 1180 New_Signal_49C_3 "P01";
BA_ "E2EDataId" SG_ 1180 New_Signal_49C_3 173;
BA_ "GenSigSendType" SG_ 1180 New_Signal_49C_3 0;
BA_ "E2EDataLength" SG_ 1180 New_Signal_49C_2 64;
BA_ "E2EProfile" SG_ 1180 New_Signal_49C_2 "P01";
BA_ "E2EDataId" SG_ 1180 New_Signal_49C_2 173;
BA_ "GenSigSendType" SG_ 1180 New_Signal_49C_2 0;
BA_ "E2EDataLength" SG_ 1180 New_Signal_49C_1 64;
BA_ "E2EProfile" SG_ 1180 New_Signal_49C_1 "P01";
BA_ "E2EDataId" SG_ 1180 New_Signal_49C_1 173;
BA_ "GenSigSendType" SG_ 1180 New_Signal_49C_1 0;
BA_ "E2EDataLength" SG_ 1180 ABM_1_Rollover_Status 64;
BA_ "E2EProfile" SG_ 1180 ABM_1_Rollover_Status "P01";
BA_ "E2EDataId" SG_ 1180 ABM_1_Rollover_Status 173;
BA_ "GenSigSendType" SG_ 1180 ABM_1_Rollover_Status 0;
BA_ "E2EDataLength" SG_ 1180 ACU_1_Resd1 64;
BA_ "E2EProfile" SG_ 1180 ACU_1_Resd1 "P01";
BA_ "E2EDataId" SG_ 1180 ACU_1_Resd1 173;
BA_ "GenSigSendType" SG_ 1180 ACU_1_Resd1 0;
BA_ "E2EDataLength" SG_ 1180 ACU_1_RollgCntr1 64;
BA_ "E2EProfile" SG_ 1180 ACU_1_RollgCntr1 "P01";
BA_ "E2EDataId" SG_ 1180 ACU_1_RollgCntr1 173;
BA_ "GenSigSendType" SG_ 1180 ACU_1_RollgCntr1 0;
BA_ "E2EDataLength" SG_ 1180 ACU_1_CRC1 64;
BA_ "E2EProfile" SG_ 1180 ACU_1_CRC1 "P01";
BA_ "E2EDataId" SG_ 1180 ACU_1_CRC1 173;
BA_ "GenSigSendType" SG_ 1180 ACU_1_CRC1 0;
BA_ "E2EDataLength" SG_ 1180 ACU_1_AirBagFailSts 64;
BA_ "E2EProfile" SG_ 1180 ACU_1_AirBagFailSts "P01";
BA_ "E2EDataId" SG_ 1180 ACU_1_AirBagFailSts 173;
BA_ "GenSigStartValue" SG_ 1180 ACU_1_AirBagFailSts 3;
BA_ "GenSigSendType" SG_ 1180 ACU_1_AirBagFailSts 0;
BA_ "E2EDataLength" SG_ 1180 ACU_1_ThdRowLBeltWarning 64;
BA_ "E2EProfile" SG_ 1180 ACU_1_ThdRowLBeltWarning "P01";
BA_ "E2EDataId" SG_ 1180 ACU_1_ThdRowLBeltWarning 173;
BA_ "GenSigSendType" SG_ 1180 ACU_1_ThdRowLBeltWarning 0;
BA_ "E2EDataLength" SG_ 1180 ACU_1_ThdRowRBeltWarning 64;
BA_ "E2EProfile" SG_ 1180 ACU_1_ThdRowRBeltWarning "P01";
BA_ "E2EDataId" SG_ 1180 ACU_1_ThdRowRBeltWarning 173;
BA_ "GenSigSendType" SG_ 1180 ACU_1_ThdRowRBeltWarning 0;
BA_ "E2EDataLength" SG_ 1180 ACU_1_PsngrSeatBeltWarning 64;
BA_ "E2EProfile" SG_ 1180 ACU_1_PsngrSeatBeltWarning "P01";
BA_ "E2EDataId" SG_ 1180 ACU_1_PsngrSeatBeltWarning 173;
BA_ "GenSigSendType" SG_ 1180 ACU_1_PsngrSeatBeltWarning 0;
BA_ "E2EDataLength" SG_ 1180 ACU_1_SecRowLBeltWarning 64;
BA_ "E2EProfile" SG_ 1180 ACU_1_SecRowLBeltWarning "P01";
BA_ "E2EDataId" SG_ 1180 ACU_1_SecRowLBeltWarning 173;
BA_ "GenSigSendType" SG_ 1180 ACU_1_SecRowLBeltWarning 0;
BA_ "E2EDataLength" SG_ 1180 ACU_1_SecRowMBeltWarning 64;
BA_ "E2EProfile" SG_ 1180 ACU_1_SecRowMBeltWarning "P01";
BA_ "E2EDataId" SG_ 1180 ACU_1_SecRowMBeltWarning 173;
BA_ "GenSigSendType" SG_ 1180 ACU_1_SecRowMBeltWarning 0;
BA_ "E2EDataLength" SG_ 1180 ACU_1_SecRowRBeltWarning 64;
BA_ "E2EProfile" SG_ 1180 ACU_1_SecRowRBeltWarning "P01";
BA_ "E2EDataId" SG_ 1180 ACU_1_SecRowRBeltWarning 173;
BA_ "GenSigSendType" SG_ 1180 ACU_1_SecRowRBeltWarning 0;
BA_ "E2EDataLength" SG_ 1180 ACU_1_PsngrSeatOccupiedSts 64;
BA_ "E2EProfile" SG_ 1180 ACU_1_PsngrSeatOccupiedSts "P01";
BA_ "E2EDataId" SG_ 1180 ACU_1_PsngrSeatOccupiedSts 173;
BA_ "GenSigSendType" SG_ 1180 ACU_1_PsngrSeatOccupiedSts 0;
BA_ "GenSigStartValue" SG_ 1341 BMS_44_PackPowerRealTime 10240;
BA_ "GenSigInvalidValue" SG_ 1341 BMS_44_PackPowerRealTime 16383;
BA_ "GenSigSendType" SG_ 1341 BMS_44_PackPowerRealTime 0;
BA_ "GenSigInvalidValue" SG_ 811 BMS_Chg_Sts 15;
BA_ "GenSigSendType" SG_ 811 BMS_Chg_Sts 0;
BA_ "GenSigSendType" SG_ 1269 LISDShowCMDSts 0;
BA_ "GenSigSendType" SG_ 1269 LISDShowModeSts 0;
BA_ "GenSigSendType" SG_ 1269 LISD_TransmitStatus 0;
BA_ "GenSigSendType" SG_ 1269 LISD_DisplayStatus 0;
BA_ "GenSigSendType" SG_ 1269 LISD_ParkingShowModSts 0;
BA_ "GenSigSendType" SG_ 1269 LISD_ParkingShowCMDSts 0;
BA_ "GenSigSendType" SG_ 1233 RISDShowCMDSts 0;
BA_ "GenSigSendType" SG_ 1233 RISDShowModeSts 0;
BA_ "GenSigSendType" SG_ 1233 RISD_TransmitStatus 0;
BA_ "GenSigSendType" SG_ 1233 RISD_DisplayStatus 0;
BA_ "GenSigSendType" SG_ 1233 RISD_ParkingShowModSts 0;
BA_ "GenSigSendType" SG_ 1233 RISD_ParkingShowCMDSts 0;
BA_ "GenSigSendType" SG_ 1169 LC_DIYMusicShowModSts 0;
BA_ "GenSigSendType" SG_ 1169 LC_RandomMusicShowSts 0;
BA_ "GenSigSendType" SG_ 1169 LC_LiShowModSts 0;
BA_ "GenSigStartValue" SG_ 1427 ILCF_1_LogoParkingSts 1;
BA_ "GenSigSendType" SG_ 1427 ILCF_1_LogoParkingSts 0;
BA_ "GenSigSendType" SG_ 1427 ILCF_1_LogoChargingSts 0;
BA_ "GenSigSendType" SG_ 1427 ILCF_1_DIYMusicShowModSts 0;
BA_ "GenSigSendType" SG_ 1427 ILCF_1_RandomMusicShowSts 0;
BA_ "GenSigStartValue" SG_ 1427 ILCF_1_LogoColorAdjSts 117;
BA_ "GenSigSendType" SG_ 1427 ILCF_1_LogoColorAdjSts 0;
BA_ "GenSigSendType" SG_ 821 ADS_5_CRC1 0;
BA_ "GenSigSendType" SG_ 821 ADS_5_RollgCntr1 0;
BA_ "GenSigSendType" SG_ 821 ADS_5_Resd1 0;
BA_ "GenSigSendType" SG_ 821 ADS_5_ILOASts 0;
BA_ "GenSigSendType" SG_ 821 ADS_5_ICAQuitReason 0;
BA_ "GenSigSendType" SG_ 821 ADS_5_ISLISt 0;
BA_ "GenSigSendType" SG_ 821 ADS_5_ILOATextInfo 0;
BA_ "GenSigSendType" SG_ 821 ADS_5_ILOAActdirection 0;
BA_ "GenSigSendType" SG_ 821 ADS_5_LKS_warning 0;
BA_ "GenSigSendType" SG_ 821 ADS_5_ISLIOverSpeedWarn 0;
BA_ "GenSigSendType" SG_ 821 ADS_5_ISLISpeedLimitSign 0;
BA_ "GenSigSendType" SG_ 821 ADS_5_EgoLeftLineHeatgAg 0;
BA_ "GenSigSendType" SG_ 821 ADS_5_EgoLeLineID 0;
BA_ "GenSigSendType" SG_ 821 ADS_5_EgoLeLineColor 0;
BA_ "GenSigSendType" SG_ 821 ADS_5_EgoLeLineTyp 0;
BA_ "GenSigSendType" SG_ 821 ADS_5_EgoLeLineHozlDst 0;
BA_ "GenSigSendType" SG_ 821 ADS_5_CRC2 0;
BA_ "GenSigSendType" SG_ 821 ADS_5_RollgCntr2 0;
BA_ "GenSigSendType" SG_ 821 ADS_5_Resd2 0;
BA_ "GenSigSendType" SG_ 821 ADS_5_NeborLeLineID 0;
BA_ "GenSigSendType" SG_ 821 ADS_5_NeborLeLineColor 0;
BA_ "GenSigSendType" SG_ 821 ADS_5_NeborLeLineTyp 0;
BA_ "GenSigSendType" SG_ 821 ADS_5_EgoLeLineCrvt 0;
BA_ "GenSigSendType" SG_ 821 ADS_5_NeborLeLineHozlDst 0;
BA_ "GenSigSendType" SG_ 821 ADS_5_NeborRiLineID 0;
BA_ "GenSigSendType" SG_ 821 ADS_5_NeborRiLineColor 0;
BA_ "GenSigSendType" SG_ 821 ADS_5_NeborRiLineTyp 0;
BA_ "GenSigSendType" SG_ 821 ADS_5_NeborLeLineCrvt 0;
BA_ "GenSigSendType" SG_ 821 ADS_5_NeborRiLineHozlDst 0;
BA_ "GenSigSendType" SG_ 821 ADS_5_CRC3 0;
BA_ "GenSigSendType" SG_ 821 ADS_5_RollgCntr3 0;
BA_ "GenSigSendType" SG_ 821 ADS_5_Resd3 0;
BA_ "GenSigSendType" SG_ 821 ADS_5_ELKSettingSt 0;
BA_ "GenSigSendType" SG_ 821 ADS_5_LDWLDPSnvtySet 0;
BA_ "GenSigSendType" SG_ 821 ADS_5_LDWWarnType 0;
BA_ "GenSigSendType" SG_ 821 ADS_5_NeborRiLineCrvt 0;
BA_ "GenSigSendType" SG_ 821 ADS_5_IESSwtSet 0;
BA_ "GenSigSendType" SG_ 821 ADS_5_IHCSettingSt 0;
BA_ "GenSigSendType" SG_ 821 ADS_5_ISLIWarningMod 0;
BA_ "GenSigSendType" SG_ 821 ADS_5_ICAEnableBtnSts 0;
BA_ "GenSigSendType" SG_ 821 ADS_5_FCM_Camera_textinfo 0;
BA_ "GenSigSendType" SG_ 821 ADS_5_EgoRiLineID 0;
BA_ "GenSigSendType" SG_ 821 ADS_5_EgoRiLineTyp 0;
BA_ "GenSigSendType" SG_ 821 ADS_5_EgoRiLineColor 0;
BA_ "GenSigInvalidValue" SG_ 821 ADS_5_EgoRiLineHozlDst 511;
BA_ "GenSigSendType" SG_ 821 ADS_5_EgoRiLineHozlDst 0;
BA_ "GenSigSendType" SG_ 821 ADS_5_CRC4 0;
BA_ "GenSigSendType" SG_ 821 ADS_5_RollgCntr4 0;
BA_ "GenSigSendType" SG_ 821 ADS_5_Resd4 0;
BA_ "GenSigInvalidValue" SG_ 821 ADS_5_EgoRightLineHeatgAg 511;
BA_ "GenSigSendType" SG_ 821 ADS_5_EgoRightLineHeatgAg 0;
BA_ "GenSigInvalidValue" SG_ 821 ADS_5_EgoRiLineCrvt 1023;
BA_ "GenSigSendType" SG_ 821 ADS_5_EgoRiLineCrvt 0;
BA_ "GenSigInvalidValue" SG_ 821 ADS_5_NeborLeftLineHeatgAg 511;
BA_ "GenSigSendType" SG_ 821 ADS_5_NeborLeftLineHeatgAg 0;
BA_ "GenSigInvalidValue" SG_ 821 ADS_5_NeborRightLineHeatgAg 511;
BA_ "GenSigSendType" SG_ 821 ADS_5_NeborRightLineHeatgAg 0;
BA_ "GenSigSendType" SG_ 819 ADS_4_CRC1 0;
BA_ "GenSigSendType" SG_ 819 ADS_4_RollgCntr1 0;
BA_ "GenSigSendType" SG_ 819 ADS_4_Resd1 0;
BA_ "GenSigSendType" SG_ 819 ADS_4_AEBStatus 0;
BA_ "GenSigSendType" SG_ 819 ADS_4_ACCSts 0;
BA_ "GenSigSendType" SG_ 819 ADS_4_TimeGapSet 0;
BA_ "GenSigSendType" SG_ 819 ADS_4_FcwMode 0;
BA_ "GenSigSendType" SG_ 819 ADS_4_AEBReqType 0;
BA_ "GenSigSendType" SG_ 819 ADS_4_SetSpd 0;
BA_ "GenSigSendType" SG_ 819 ADS_4_DAIStatus 0;
BA_ "GenSigSendType" SG_ 819 ADS_4_ACCTextMessage 0;
BA_ "GenSigSendType" SG_ 819 ADS_4_LongiTakeOverReq 0;
BA_ "GenSigSendType" SG_ 819 ADS_4_SetSpdUnit 0;
BA_ "GenSigSendType" SG_ 819 ADS_4_GoNotifier 0;
BA_ "GenSigSendType" SG_ 819 ADS_4_DAISts 0;
BA_ "GenSigSendType" SG_ 819 ADS_4_Radar_textinfo 0;
BA_ "GenSigSendType" SG_ 819 ADS_4_SCF_PopoverReq 0;
BA_ "GenSigSendType" SG_ 819 ADS_4_DrvrCfmSCFDispFb 0;
BA_ "GenSigSendType" SG_ 819 ADS_4_SCF_SpdLimUnit 0;
BA_ "GenSigSendType" SG_ 819 ADS_4_SCF_SpdLimSts 0;
BA_ "GenSigSendType" SG_ 819 ADS_4_CRC2 0;
BA_ "GenSigSendType" SG_ 819 ADS_4_RollgCntr2 0;
BA_ "GenSigSendType" SG_ 819 ADS_4_Resd2 0;
BA_ "GenSigSendType" SG_ 819 ADS_4_ACCObjTyp 0;
BA_ "GenSigSendType" SG_ 819 ADS_4_FrntFarObjTyp 0;
BA_ "GenSigSendType" SG_ 819 ADS_4_ACCObjLgtDstX 0;
BA_ "GenSigSendType" SG_ 819 ADS_4_FrntFarObjID 0;
BA_ "GenSigSendType" SG_ 819 ADS_4_Resd 0;
BA_ "GenSigSendType" SG_ 819 ADS_4_ACCObjID 0;
BA_ "GenSigSendType" SG_ 819 ADS_4_ACCObjHozDstY 0;
BA_ "GenSigSendType" SG_ 819 ADS_4_FrntFarObjHozDstY 0;
BA_ "GenSigSendType" SG_ 819 ADS_4_FrntFarObjLgtDstX 0;
BA_ "GenSigSendType" SG_ 819 ADS_4_CRC3 0;
BA_ "GenSigSendType" SG_ 819 ADS_4_RollgCntr3 0;
BA_ "GenSigSendType" SG_ 819 ADS_4_Resd3 0;
BA_ "GenSigSendType" SG_ 819 ADS_4_Resd_1 0;
BA_ "GenSigSendType" SG_ 819 ADS_4_LeObjID 0;
BA_ "GenSigSendType" SG_ 819 ADS_4_LeObjTyp 0;
BA_ "GenSigSendType" SG_ 819 ADS_4_LeObjHozDstY 0;
BA_ "GenSigSendType" SG_ 819 ADS_4_LeObjLgtDstX 0;
BA_ "GenSigSendType" SG_ 819 ADS_4_RiObjID 0;
BA_ "GenSigSendType" SG_ 819 ADS_4_RiObjTyp 0;
BA_ "GenSigSendType" SG_ 819 ADS_4_RiObjHozDstY 0;
BA_ "GenSigSendType" SG_ 819 ADS_4_RiObjLgtDstX 0;
BA_ "GenSigSendType" SG_ 819 ADS_4_CRC4 0;
BA_ "GenSigSendType" SG_ 819 ADS_4_RollgCntr4 0;
BA_ "GenSigSendType" SG_ 819 ADS_4_Resd4 0;
BA_ "GenSigSendType" SG_ 819 ADS_4_SCFSwtSet 0;
BA_ "GenSigSendType" SG_ 819 ADS_4_AEBSettingSt 0;
BA_ "GenSigSendType" SG_ 819 ADS_4_FCWSettingSt 0;
BA_ "GenSigSendType" SG_ 819 ADS_4_DAISwtSet 0;
BA_ "GenSigSendType" SG_ 819 ADS_4_CruiseAccelerateSts 0;
BA_ "GenSigStartValue" SG_ 1172 ExternalTemperature_F 225;
BA_ "GenSigSendType" SG_ 1172 ExternalTemperature_F 0;
BA_ "GenSigStartValue" SG_ 1172 ExternalTemperature_C 254;
BA_ "GenSigInvalidValue" SG_ 1172 ExternalTemperature_C 254;
BA_ "GenSigSendType" SG_ 1172 ExternalTemperature_C 0;
BA_ "GenSigSendType" SG_ 1172 BlowSpeedLevelDisplaySts 0;
BA_ "GenSigStartValue" SG_ 1147 CCP_1_FLTempSwitchReq 31;
BA_ "GenSigInvalidValue" SG_ 1147 CCP_1_FLTempSwitchReq 31;
BA_ "GenSigSendType" SG_ 1147 CCP_1_FLTempSwitchReq 0;
BA_ "GenSigSendType" SG_ 1147 CCP_1_FrontAutoACSwitchReq 0;
BA_ "GenSigSendType" SG_ 1147 CCP_1_FrontOFFSwitchReq 0;
BA_ "GenSigSendType" SG_ 1147 CCP_1_FBlowSpdCtrlSwitchReq 0;
BA_ "GenSigSendType" SG_ 1147 FLCCP_MainSetHeatReq 0;
BA_ "GenSigSendType" SG_ 1147 FLCCP_MainSetVentilationReq 0;
BA_ "GenSigSendType" SG_ 1147 CCP_1_ACFastCool 0;
BA_ "GenSigSendType" SG_ 1107 TMS_PM25_Detect 0;
BA_ "GenSigStartValue" SG_ 1107 TMS_CCP_FLTempSts 31;
BA_ "GenSigInvalidValue" SG_ 1107 TMS_CCP_FLTempSts 31;
BA_ "GenSigSendType" SG_ 1107 TMS_CCP_FLTempSts 0;
BA_ "GenSigSendType" SG_ 1107 TMS_CCP_FrontAutoACSts 0;
BA_ "GenSigSendType" SG_ 1107 TMS_CCP_ACStatus 0;
BA_ "GenSigSendType" SG_ 1107 TMS_CCP_FrontOFFSts 0;
BA_ "GenSigSendType" SG_ 1107 TMS_CCP_FBlowSpdCtrlSts 0;
BA_ "GenSigStartValue" SG_ 1107 TMS_CCP_FRTempSts 31;
BA_ "GenSigInvalidValue" SG_ 1107 TMS_CCP_FRTempSts 31;
BA_ "GenSigSendType" SG_ 1107 TMS_CCP_FRTempSts 0;
BA_ "GenSigSendType" SG_ 1107 TMS_CCP_RecyMode 0;
BA_ "GenSigSendType" SG_ 1107 TMS_CCP_FrontDefrostSts 0;
BA_ "GenSigSendType" SG_ 1107 TMS_UVC_WorkingBfReq 0;
BA_ "GenSigSendType" SG_ 1107 TMS_UVC_LuminanceBfReq 0;
BA_ "GenSigSendType" SG_ 1107 TMS_CCP_ACFastCool 0;
BA_ "GenSigSendType" SG_ 1107 TMS_CCP_ACFastHeat 0;
BA_ "GenSigSendType" SG_ 1175 FRCCP_ZoneSelectionKeyReq 0;
BA_ "GenSigStartValue" SG_ 1175 CCP_2_FRTempSwitchReq 31;
BA_ "GenSigInvalidValue" SG_ 1175 CCP_2_FRTempSwitchReq 31;
BA_ "GenSigSendType" SG_ 1175 CCP_2_FRTempSwitchReq 0;
BA_ "GenSigSendType" SG_ 1175 CCP_2_RecyModeReq 0;
BA_ "GenSigSendType" SG_ 1175 CCP_2_DefrostModeSwitchReq 0;
BA_ "GenSigSendType" SG_ 1175 CCP_2_RearDefrostSwitchReq 0;
BA_ "GenSigSendType" SG_ 1175 CCP_2_ACFastHeat 0;
BA_ "GenSigSendType" SG_ 1175 CCP_2_FrontBlowSpdCtrlSwitchReq 0;
BA_ "GenSigSendType" SG_ 1175 FRCCP_DeputySetHeatReq 0;
BA_ "GenSigSendType" SG_ 1175 FRCCP_DeputySetVentilationReq 0;
BA_ "GenSigSendType" SG_ 1175 CCP_2_ACSwitchReq 0;
BA_ "GenSigSendType" SG_ 1292 CHB_App_Sts 0;
BA_ "GenSigSendType" SG_ 1292 CHB_AppMem_Sts 0;
BA_ "GenSigSendType" SG_ 1292 CHB_AppDelay_Sts 0;
BA_ "GenSigInvalidValue" SG_ 1292 CHB_AppTimeset_Sts 31;
BA_ "GenSigSendType" SG_ 1292 CHB_AppTimeset_Sts 0;
BA_ "GenSigSendType" SG_ 1292 CHB_AppCoolorheat_Sts 0;
BA_ "GenSigSendType" SG_ 1292 CHB_AppCoolset_Sts 0;
BA_ "GenSigSendType" SG_ 1292 CHB_AppHeatset_Sts 0;
BA_ "GenSigSendType" SG_ 1292 CHB_AppSterilization_Sts 0;
BA_ "GenSigSendType" SG_ 1292 CHB_AppItemsLeft_Sts 0;
BA_ "GenSigSendType" SG_ 1292 CHB_AppItemsLeftset_Sts 0;
BA_ "GenSigSendType" SG_ 1292 CHB_AppChbDoor_Sts 0;
BA_ "GenSigSendType" SG_ 1241 FuelTankLidSystemFailureSts 0;
BA_ "GenSigSendType" SG_ 1241 FuelTankPressureConditionReached 0;
BA_ "GenSigStartValue" SG_ 49 ACU_2_LateralAcceleration 2000;
BA_ "GenSigInvalidValue" SG_ 49 ACU_2_LateralAcceleration 65535;
BA_ "GenSigSendType" SG_ 49 ACU_2_LateralAcceleration 0;
BA_ "GRC_Sig_ASIL" SG_ 49 ACU_2_LateralAcceleration 3;
BA_ "GenSigStartValue" SG_ 49 ACU_2_YawRate 18000;
BA_ "GenSigInvalidValue" SG_ 49 ACU_2_YawRate 65535;
BA_ "GenSigSendType" SG_ 49 ACU_2_YawRate 0;
BA_ "GRC_Sig_ASIL" SG_ 49 ACU_2_YawRate 3;
BA_ "GenSigStartValue" SG_ 49 ACU_2_YawrateSigValidData 3;
BA_ "GenSigSendType" SG_ 49 ACU_2_YawrateSigValidData 0;
BA_ "GRC_Sig_ASIL" SG_ 49 ACU_2_YawrateSigValidData 3;
BA_ "GenSigStartValue" SG_ 49 ACU_2_LateralAccelerationSigVD 3;
BA_ "GenSigSendType" SG_ 49 ACU_2_LateralAccelerationSigVD 0;
BA_ "GRC_Sig_ASIL" SG_ 49 ACU_2_LateralAccelerationSigVD 3;
BA_ "GenSigSendType" SG_ 1024 FRZCU_QueenSeatPosSts 0;
BA_ "GenSigSendType" SG_ 1024 FRZCU_ADSLightFltSts 0;
BA_ "GenSigSendType" SG_ 1024 FRZCU_ADSLightSts 0;
BA_ "GenSigSendType" SG_ 1024 FRZCU_QueenSeatEnterSts 0;
BA_ "GenSigSendType" SG_ 1024 FRZCU_QueenSeatMovFailCause 0;
BA_ "GenSigSendType" SG_ 1024 FRZCU_QueenSeatSts 0;
BA_ "GenSigSendType" SG_ 1024 FRZCU_PasgerSeatMovFailCause 0;
BA_ "GenSigSendType" SG_ 1024 CSunshadeSts 0;
BA_ "GenSigSendType" SG_ 1024 CSunshadePercentSts 0;
BA_ "GenSigSendType" SG_ 1024 FRZCU_SeatHeatLvlFR2 0;
BA_ "GenSigSendType" SG_ 1024 FRZCU_SeatVentLvlFR2 0;
BA_ "GenSigSendType" SG_ 1024 FRZCU_SeatVentLvlRR2 0;
BA_ "GenSigSendType" SG_ 1024 FRZCU_SeatHeatLvlRR2 0;
BA_ "GenSigSendType" SG_ 1024 FRZCU_ContainerlightSts 0;
BA_ "GenSigSendType" SG_ 1024 FRZCU_FRWinThermalSts 0;
BA_ "GenSigSendType" SG_ 1024 FRZCU_RRWinThermalSts 0;
BA_ "GenSigSendType" SG_ 1024 FRZCU_CSunshadeThermalSts 0;
BA_ "GenSigSendType" SG_ 1182 OBC_InnerDischgVolt 0;
BA_ "GRC_Sig_ASIL" SG_ 1182 OBC_InnerDischgVolt 2;
BA_ "GenSigSendType" SG_ 1182 OBC_InnerDischgCurr 0;
BA_ "GRC_Sig_ASIL" SG_ 1182 OBC_InnerDischgCurr 2;
BA_ "GenSigSendType" SG_ 1182 OBC_ElectronicLockSts 0;
BA_ "GenSigSendType" SG_ 1182 OBC_WorkingMode 0;
BA_ "GRC_Sig_ASIL" SG_ 1182 OBC_WorkingMode 2;
BA_ "GenSigSendType" SG_ 1182 OBC_OutDischgCurr 0;
BA_ "GRC_Sig_ASIL" SG_ 1182 OBC_OutDischgCurr 2;
BA_ "GenSigSendType" SG_ 1182 OBC_OutDischgVolt 0;
BA_ "GRC_Sig_ASIL" SG_ 1182 OBC_OutDischgVolt 2;
BA_ "E2EDataLength" SG_ 290 EPS_1_CRC 64;
BA_ "E2EProfile" SG_ 290 EPS_1_CRC "P01";
BA_ "E2EDataId" SG_ 290 EPS_1_CRC 46;
BA_ "GenSigSendType" SG_ 290 EPS_1_CRC 0;
BA_ "E2EDataLength" SG_ 290 EPS_1_RollgCntr 64;
BA_ "E2EProfile" SG_ 290 EPS_1_RollgCntr "P01";
BA_ "E2EDataId" SG_ 290 EPS_1_RollgCntr 46;
BA_ "GenSigSendType" SG_ 290 EPS_1_RollgCntr 0;
BA_ "E2EDataLength" SG_ 290 EPSFailSts 64;
BA_ "E2EProfile" SG_ 290 EPSFailSts "P01";
BA_ "E2EDataId" SG_ 290 EPSFailSts 46;
BA_ "GenSigSendType" SG_ 290 EPSFailSts 0;
BA_ "GRC_Sig_ASIL" SG_ 290 EPSFailSts 3;
BA_ "E2EDataLength" SG_ 290 EPSSteeringAngleCalibrationSts 64;
BA_ "E2EProfile" SG_ 290 EPSSteeringAngleCalibrationSts "P01";
BA_ "E2EDataId" SG_ 290 EPSSteeringAngleCalibrationSts 46;
BA_ "GenSigSendType" SG_ 290 EPSSteeringAngleCalibrationSts 0;
BA_ "E2EDataLength" SG_ 290 EPS_EOTLearning_Sts 64;
BA_ "E2EProfile" SG_ 290 EPS_EOTLearning_Sts "P01";
BA_ "E2EDataId" SG_ 290 EPS_EOTLearning_Sts 46;
BA_ "GenSigSendType" SG_ 290 EPS_EOTLearning_Sts 0;
BA_ "GenSigSendType" SG_ 513 MFSL_UP_SW 0;
BA_ "GenSigSendType" SG_ 513 MFSL_DW_SW 0;
BA_ "GenSigSendType" SG_ 513 MFSL_Left_SW 0;
BA_ "GenSigSendType" SG_ 513 MFSL_Right_SW 0;
BA_ "GenSigSendType" SG_ 513 MFSL_OK_SW 0;
BA_ "GenSigSendType" SG_ 513 MFSL_AVM_SW 0;
BA_ "GenSigSendType" SG_ 513 MFSL_Customize 0;
BA_ "GenSigStartValue" SG_ 1152 TBOX_PetmodeSetTemperature 31;
BA_ "GenSigInvalidValue" SG_ 1152 TBOX_PetmodeSetTemperature 31;
BA_ "GenSigSendType" SG_ 1152 TBOX_PetmodeSetTemperature 5;
BA_ "GenSigSendType" SG_ 1208 PPMID_1_PPMICounter 0;
BA_ "GenSigStartValue" SG_ 1208 PPMID_1_PPMISt 1;
BA_ "GenSigSendType" SG_ 1208 PPMID_1_PPMISt 0;
BA_ "GenSigStartValue" SG_ 1208 PPMID_1_HWSts 1;
BA_ "GenSigSendType" SG_ 1208 PPMID_1_HWSts 0;
BA_ "GenSigStartValue" SG_ 1208 PPMID_1_BSRBPASts 1;
BA_ "GenSigSendType" SG_ 1208 PPMID_1_BSRBPASts 0;
BA_ "GenSigSendType" SG_ 794 ADS_3_ICAStatus 0;
BA_ "GenSigSendType" SG_ 794 ADS_3_ICATextinfo 0;
BA_ "GenSigSendType" SG_ 794 ADS_3_ACCSts 0;
BA_ "GenSigSendType" SG_ 794 ADS_3_DriverHandsoffWarning 0;
BA_ "GenSigSendType" SG_ 794 ADS_3_LKSMod 0;
BA_ "GenSigSendType" SG_ 794 ADS_3_LKSSts 0;
BA_ "GenSigSendType" SG_ 794 ADS_3_ELKSts 0;
BA_ "GenSigSendType" SG_ 794 ADS_3_LKSLeftTrackingSt 0;
BA_ "GenSigSendType" SG_ 794 ADS_3_LKSRightTrackingSt 0;
BA_ "GenSigSendType" SG_ 794 ADS_3_ELKLeftActiveSt 0;
BA_ "GenSigSendType" SG_ 794 ADS_3_ELKRightActiveSt 0;
BA_ "GenSigSendType" SG_ 1155 ASU_3_horizontalSts 0;
BA_ "GenSigSendType" SG_ 1155 ASU_3_horizontalmodeFb 0;
BA_ "GenSigSendType" SG_ 1164 OBC_DischgSts 0;
BA_ "GenSigSendType" SG_ 789 ATCM_ASU_LowerSet 5;
BA_ "GenSigSendType" SG_ 789 ATCM_ASU_LiftSet 5;
BA_ "GenSigSendType" SG_ 789 ATCM_DriveModeSw 5;
BA_ "GenSigSendType" SG_ 789 ATCM_XModeSw 5;
BA_ "GenSigSendType" SG_ 789 ATCM_SwitchUTurnModeSet 5;
BA_ "GenSigSendType" SG_ 1214 BNCM_16_CRC1 1;
BA_ "GenSigSendType" SG_ 1214 BNCM_16_RollgCntr1 1;
BA_ "GenSigSendType" SG_ 1214 BNCM_16_Resd1 1;
BA_ "GenSigSendType" SG_ 1214 BNCM_16_CMD 1;
BA_ "GenSigSendType" SG_ 1214 BNCM_16_PDU1 1;
BA_ "GenSigSendType" SG_ 1214 BNCM_16_PDU2 1;
BA_ "GenSigSendType" SG_ 1214 BNCM_16_PDU3 1;
BA_ "GenSigSendType" SG_ 1214 BNCM_16_PDU4 1;
BA_ "E2EDataLength" SG_ 1095 RLCR_1_CRC1 64;
BA_ "E2EProfile" SG_ 1095 RLCR_1_CRC1 "P01";
BA_ "E2EDataId" SG_ 1095 RLCR_1_CRC1 68;
BA_ "GenSigSendType" SG_ 1095 RLCR_1_CRC1 0;
BA_ "E2EDataLength" SG_ 1095 RLCR_1_RollgCntr1 64;
BA_ "E2EProfile" SG_ 1095 RLCR_1_RollgCntr1 "P01";
BA_ "E2EDataId" SG_ 1095 RLCR_1_RollgCntr1 68;
BA_ "GenSigSendType" SG_ 1095 RLCR_1_RollgCntr1 0;
BA_ "E2EDataLength" SG_ 1095 RLCR_1_Resd1 64;
BA_ "E2EProfile" SG_ 1095 RLCR_1_Resd1 "P01";
BA_ "E2EDataId" SG_ 1095 RLCR_1_Resd1 68;
BA_ "GenSigSendType" SG_ 1095 RLCR_1_Resd1 0;
BA_ "E2EDataLength" SG_ 1095 RLCR_1_SysSt 64;
BA_ "E2EProfile" SG_ 1095 RLCR_1_SysSt "P01";
BA_ "E2EDataId" SG_ 1095 RLCR_1_SysSt 68;
BA_ "GenSigSendType" SG_ 1095 RLCR_1_SysSt 0;
BA_ "E2EDataLength" SG_ 1095 RLCR_1_BlkSts 64;
BA_ "E2EProfile" SG_ 1095 RLCR_1_BlkSts "P01";
BA_ "E2EDataId" SG_ 1095 RLCR_1_BlkSts 68;
BA_ "GenSigSendType" SG_ 1095 RLCR_1_BlkSts 0;
BA_ "E2EDataLength" SG_ 1095 RLCR_1_BSDWarn 64;
BA_ "E2EProfile" SG_ 1095 RLCR_1_BSDWarn "P01";
BA_ "E2EDataId" SG_ 1095 RLCR_1_BSDWarn 68;
BA_ "GenSigSendType" SG_ 1095 RLCR_1_BSDWarn 0;
BA_ "E2EDataLength" SG_ 1095 RLCR_1_DOWWarn 64;
BA_ "E2EProfile" SG_ 1095 RLCR_1_DOWWarn "P01";
BA_ "E2EDataId" SG_ 1095 RLCR_1_DOWWarn 68;
BA_ "GenSigSendType" SG_ 1095 RLCR_1_DOWWarn 0;
BA_ "E2EDataLength" SG_ 1095 RLCR_1_DowLock 64;
BA_ "E2EProfile" SG_ 1095 RLCR_1_DowLock "P01";
BA_ "E2EDataId" SG_ 1095 RLCR_1_DowLock 68;
BA_ "GenSigSendType" SG_ 1095 RLCR_1_DowLock 0;
BA_ "E2EDataLength" SG_ 1095 RLCR_1_ELK_Collision_flag 64;
BA_ "E2EProfile" SG_ 1095 RLCR_1_ELK_Collision_flag "P01";
BA_ "E2EDataId" SG_ 1095 RLCR_1_ELK_Collision_flag 68;
BA_ "GenSigSendType" SG_ 1095 RLCR_1_ELK_Collision_flag 0;
BA_ "E2EDataLength" SG_ 1095 RLCR_1_ELK_CollisionFlagValid 64;
BA_ "E2EProfile" SG_ 1095 RLCR_1_ELK_CollisionFlagValid "P01";
BA_ "E2EDataId" SG_ 1095 RLCR_1_ELK_CollisionFlagValid 68;
BA_ "GenSigSendType" SG_ 1095 RLCR_1_ELK_CollisionFlagValid 0;
BA_ "E2EDataLength" SG_ 1267 RRCR_1_CRC1 64;
BA_ "E2EProfile" SG_ 1267 RRCR_1_CRC1 "P01";
BA_ "E2EDataId" SG_ 1267 RRCR_1_CRC1 70;
BA_ "GenSigSendType" SG_ 1267 RRCR_1_CRC1 0;
BA_ "E2EDataLength" SG_ 1267 RRCR_1_RollgCntr1 64;
BA_ "E2EProfile" SG_ 1267 RRCR_1_RollgCntr1 "P01";
BA_ "E2EDataId" SG_ 1267 RRCR_1_RollgCntr1 70;
BA_ "GenSigSendType" SG_ 1267 RRCR_1_RollgCntr1 0;
BA_ "E2EDataLength" SG_ 1267 RRCR_1_Resd1 64;
BA_ "E2EProfile" SG_ 1267 RRCR_1_Resd1 "P01";
BA_ "E2EDataId" SG_ 1267 RRCR_1_Resd1 70;
BA_ "GenSigSendType" SG_ 1267 RRCR_1_Resd1 0;
BA_ "E2EDataLength" SG_ 1267 RRCR_1_SysSt 64;
BA_ "E2EProfile" SG_ 1267 RRCR_1_SysSt "P01";
BA_ "E2EDataId" SG_ 1267 RRCR_1_SysSt 70;
BA_ "GenSigSendType" SG_ 1267 RRCR_1_SysSt 0;
BA_ "E2EDataLength" SG_ 1267 RRCR_1_BlkSts 64;
BA_ "E2EProfile" SG_ 1267 RRCR_1_BlkSts "P01";
BA_ "E2EDataId" SG_ 1267 RRCR_1_BlkSts 70;
BA_ "GenSigSendType" SG_ 1267 RRCR_1_BlkSts 0;
BA_ "E2EDataLength" SG_ 1267 RRCR_1_BSDWarn 64;
BA_ "E2EProfile" SG_ 1267 RRCR_1_BSDWarn "P01";
BA_ "E2EDataId" SG_ 1267 RRCR_1_BSDWarn 70;
BA_ "GenSigSendType" SG_ 1267 RRCR_1_BSDWarn 0;
BA_ "E2EDataLength" SG_ 1267 RRCR_1_DOWWarn 64;
BA_ "E2EProfile" SG_ 1267 RRCR_1_DOWWarn "P01";
BA_ "E2EDataId" SG_ 1267 RRCR_1_DOWWarn 70;
BA_ "GenSigSendType" SG_ 1267 RRCR_1_DOWWarn 0;
BA_ "E2EDataLength" SG_ 1267 RRCR_1_DowLock 64;
BA_ "E2EProfile" SG_ 1267 RRCR_1_DowLock "P01";
BA_ "E2EDataId" SG_ 1267 RRCR_1_DowLock 70;
BA_ "GenSigSendType" SG_ 1267 RRCR_1_DowLock 0;
BA_ "E2EDataLength" SG_ 1267 RRCR_1_ELK_Collision_flag 64;
BA_ "E2EProfile" SG_ 1267 RRCR_1_ELK_Collision_flag "P01";
BA_ "E2EDataId" SG_ 1267 RRCR_1_ELK_Collision_flag 70;
BA_ "GenSigSendType" SG_ 1267 RRCR_1_ELK_Collision_flag 0;
BA_ "E2EDataLength" SG_ 1267 RRCR_1_ELK_CollisionFlagValid 64;
BA_ "E2EProfile" SG_ 1267 RRCR_1_ELK_CollisionFlagValid "P01";
BA_ "E2EDataId" SG_ 1267 RRCR_1_ELK_CollisionFlagValid 70;
BA_ "GenSigSendType" SG_ 1267 RRCR_1_ELK_CollisionFlagValid 0;
BA_ "GenSigSendType" SG_ 788 SentinelModeExitReasonSts_314h 0;
BA_ "GenSigSendType" SG_ 788 SentinelModeWorkingSts_314h 0;
BA_ "GenSigSendType" SG_ 788 SentinelModeAlarmSts_314h 0;
BA_ "GenSigSendType" SG_ 788 SentinelModeSts_314h 0;
BA_ "GenSigSendType" SG_ 788 SentinelModeSensitivitySts_314h 0;
BA_ "GenSigSendType" SG_ 788 SentinelModeSwitchSts_314h 0;
BA_ "GenSigSendType" SG_ 788 ADS_2_AEBStatus 0;
BA_ "GenSigSendType" SG_ 788 ADS_2_FCWStatus 0;
BA_ "GenSigSendType" SG_ 788 FCM_2_IHCfunctionSts 0;
BA_ "GenSigSendType" SG_ 571 LHTurnlightSts 0;
BA_ "GRC_Sig_ASIL" SG_ 571 LHTurnlightSts 3;
BA_ "GenSigSendType" SG_ 571 RHTurnlightSts 0;
BA_ "GRC_Sig_ASIL" SG_ 571 RHTurnlightSts 3;
BA_ "GenSigSendType" SG_ 571 LHFdoorSts 0;
BA_ "GRC_Sig_ASIL" SG_ 571 LHFdoorSts 2;
BA_ "GenSigStartValue" SG_ 571 LHFDoorLockSts 3;
BA_ "GenSigSendType" SG_ 571 LHFDoorLockSts 0;
BA_ "GRC_Sig_ASIL" SG_ 571 LHFDoorLockSts 2;
BA_ "GenSigSendType" SG_ 571 LHTurnSW 0;
BA_ "GenSigSendType" SG_ 571 RHTurnSW 0;
BA_ "GenSigSendType" SG_ 571 HazardLightSW 0;
BA_ "GenSigSendType" SG_ 571 LHFSeatBeltSW 0;
BA_ "GRC_Sig_ASIL" SG_ 571 LHFSeatBeltSW 2;
BA_ "GenSigSendType" SG_ 571 DirectionIndLeft 0;
BA_ "GRC_Sig_ASIL" SG_ 571 DirectionIndLeft 3;
BA_ "GenSigSendType" SG_ 571 DirectionIndRight 0;
BA_ "GRC_Sig_ASIL" SG_ 571 DirectionIndRight 3;
BA_ "GenSigSendType" SG_ 699 LHRdoorSts 0;
BA_ "GRC_Sig_ASIL" SG_ 699 LHRdoorSts 2;
BA_ "GenSigSendType" SG_ 787 ChrgHoodSts 0;
BA_ "GenSigSendType" SG_ 787 FRZCU_FRSitPosnSts 0;
BA_ "GenSigSendType" SG_ 524 New_Signal_20C_1 0;
BA_ "GenSigSendType" SG_ 524 New_Signal_20C 0;
BA_ "E2EDataLength" SG_ 524 ADS_6_CRC1 64;
BA_ "E2EProfile" SG_ 524 ADS_6_CRC1 "P01";
BA_ "E2EDataId" SG_ 524 ADS_6_CRC1 249;
BA_ "GenSigSendType" SG_ 524 ADS_6_CRC1 0;
BA_ "E2EDataLength" SG_ 524 ADS_6_RollgCntr1 64;
BA_ "E2EProfile" SG_ 524 ADS_6_RollgCntr1 "P01";
BA_ "E2EDataId" SG_ 524 ADS_6_RollgCntr1 249;
BA_ "GenSigSendType" SG_ 524 ADS_6_RollgCntr1 0;
BA_ "E2EDataLength" SG_ 524 ADS_6_Resd1 64;
BA_ "E2EProfile" SG_ 524 ADS_6_Resd1 "P01";
BA_ "E2EDataId" SG_ 524 ADS_6_Resd1 249;
BA_ "GenSigSendType" SG_ 524 ADS_6_Resd1 0;
BA_ "E2EDataLength" SG_ 524 ADS_6_AVM_FuncSts 64;
BA_ "E2EProfile" SG_ 524 ADS_6_AVM_FuncSts "P01";
BA_ "E2EDataId" SG_ 524 ADS_6_AVM_FuncSts 249;
BA_ "GenSigSendType" SG_ 524 ADS_6_AVM_FuncSts 0;
BA_ "E2EDataLength" SG_ 524 ADS_6_AVM_ButtonClick 64;
BA_ "E2EProfile" SG_ 524 ADS_6_AVM_ButtonClick "P01";
BA_ "E2EDataId" SG_ 524 ADS_6_AVM_ButtonClick 249;
BA_ "GenSigSendType" SG_ 524 ADS_6_AVM_ButtonClick 0;
BA_ "E2EDataLength" SG_ 524 ADS_6_Customize_buttonsFB 64;
BA_ "E2EProfile" SG_ 524 ADS_6_Customize_buttonsFB "P01";
BA_ "E2EDataId" SG_ 524 ADS_6_Customize_buttonsFB 249;
BA_ "GenSigSendType" SG_ 524 ADS_6_Customize_buttonsFB 0;
BA_ "E2EDataLength" SG_ 524 ADS_6_PAS_AudioTone 64;
BA_ "E2EProfile" SG_ 524 ADS_6_PAS_AudioTone "P01";
BA_ "E2EDataId" SG_ 524 ADS_6_PAS_AudioTone 249;
BA_ "GenSigSendType" SG_ 524 ADS_6_PAS_AudioTone 0;
BA_ "GenSigSendType" SG_ 572 ONEBOX_7_TAB_HighTemp 0;
BA_ "GenSigSendType" SG_ 572 ONEBOX_7_TAB_Active 0;
BA_ "GenSigSendType" SG_ 572 ONEBOX_7_BSW_Active 0;
BA_ "GenSigSendType" SG_ 572 ONEBOX_7_iCCO_TgtVel 0;
BA_ "GenSigSendType" SG_ 1212 VCU_3_G_ActWheelTorqueFA 0;
BA_ "GRC_Sig_ASIL" SG_ 1212 VCU_3_G_ActWheelTorqueFA 3;
BA_ "GenSigSendType" SG_ 1212 VCU_3_G_ActWheelTorqueRA 0;
BA_ "GRC_Sig_ASIL" SG_ 1212 VCU_3_G_ActWheelTorqueRA 3;
BA_ "GenSigSendType" SG_ 783 ADCC_SysReadySts 0;
BA_ "GenSigSendType" SG_ 1110 IMMO_Chall_ICC 2;
BA_ "GenSigSendType" SG_ 1149 IMMO_Teach_VCC 2;
BA_ "GenSigSendType" SG_ 1037 ADS_RCTAWarn_Left 0;
BA_ "GenSigSendType" SG_ 1037 ADS_RCTAWarn_Rigth 0;
BA_ "GenSigSendType" SG_ 1037 ADS_FCTAWarn_Left 0;
BA_ "GenSigSendType" SG_ 1037 ADS_FCTAWarn_Right 0;
BA_ "GenSigSendType" SG_ 943 Fraxlebearingrate 0;
BA_ "GenSigSendType" SG_ 943 CSA_3_CRC1 0;
BA_ "GenSigSendType" SG_ 943 CSA_3_RollgCntr1 0;
BA_ "GenSigSendType" SG_ 943 CSA_3_Resd1 0;
BA_ "GenSigInvalidValue" SG_ 943 FlwheelBearing 4095;
BA_ "GenSigSendType" SG_ 943 FlwheelBearing 0;
BA_ "GenSigInvalidValue" SG_ 943 FrwheelBearing 4095;
BA_ "GenSigSendType" SG_ 943 FrwheelBearing 0;
BA_ "GenSigInvalidValue" SG_ 943 BlwheelBearing 4095;
BA_ "GenSigSendType" SG_ 943 BlwheelBearing 0;
BA_ "GenSigInvalidValue" SG_ 943 BrwheelBearing 4095;
BA_ "GenSigSendType" SG_ 943 BrwheelBearing 0;
BA_ "GenSigSendType" SG_ 943 CSA_3_CRC2 0;
BA_ "GenSigSendType" SG_ 943 CSA_3_RollgCntr2 0;
BA_ "GenSigInvalidValue" SG_ 943 VehicleBearing_kg 4095;
BA_ "GenSigSendType" SG_ 943 VehicleBearing_kg 0;
BA_ "GenSigInvalidValue" SG_ 943 VehicleBearing_lb 4095;
BA_ "GenSigSendType" SG_ 943 VehicleBearing_lb 0;
BA_ "GenSigInvalidValue" SG_ 943 GoodsWeight_kg 4095;
BA_ "GenSigSendType" SG_ 943 GoodsWeight_kg 0;
BA_ "GenSigInvalidValue" SG_ 943 Goods_Weight_Ratio 1023;
BA_ "GenSigSendType" SG_ 943 Goods_Weight_Ratio 0;
BA_ "GenSigSendType" SG_ 943 CSA_3_CRC3 0;
BA_ "GenSigSendType" SG_ 943 CSA_3_RollgCntr3 0;
BA_ "GenSigSendType" SG_ 943 CSA_3_Resd3 0;
BA_ "GenSigInvalidValue" SG_ 943 GoodsWeight_lb 4095;
BA_ "GenSigSendType" SG_ 943 GoodsWeight_lb 0;
BA_ "GenSigInvalidValue" SG_ 943 OverWeightValue_kg 4095;
BA_ "GenSigSendType" SG_ 943 OverWeightValue_kg 0;
BA_ "GenSigInvalidValue" SG_ 943 OverWeightValue_lb 4095;
BA_ "GenSigSendType" SG_ 943 OverWeightValue_lb 0;
BA_ "GenSigSendType" SG_ 943 OverWeightRatio 0;
BA_ "GenSigSendType" SG_ 943 OverWeightWarning 0;
BA_ "GenSigSendType" SG_ 943 OverLoadWarnShieldSetFed 0;
BA_ "GenSigInvalidValue" SG_ 1120 RLHS_2_AmbBrightness 4095;
BA_ "GenSigSendType" SG_ 1120 RLHS_2_AmbBrightness 0;
BA_ "GenSigSendType" SG_ 1120 RLHS_LiSwithReason 0;
BA_ "GenSigSendType" SG_ 850 ASU_trekthrough_352h 0;
BA_ "GenSigSendType" SG_ 850 ASU_undergroundmode_352h 0;
BA_ "GenSigSendType" SG_ 850 ASU_inflate_352h 0;
BA_ "GenSigSendType" SG_ 850 ASU_6_HMIFailFb_JT 0;
BA_ "GRC_Sig_ASIL" SG_ 850 ASU_6_HMIFailFb_JT 3;
BA_ "GenSigSendType" SG_ 1199 TCM_1_TrailerSts 0;
BA_ "GRC_Sig_ASIL" SG_ 1199 TCM_1_TrailerSts 3;
VAL_ 1224 BMS_HvBattCellVoltMax_Num 254 "Abnormal" 255 "Invalid" ;
VAL_ 1224 BMS_HvBattCellVoltMax 65534 "Abnormal" 65535 "Invalid" ;
VAL_ 1224 BMS_HvBattCellVoltMin_Num 254 "Abnormal" 255 "Invalid" ;
VAL_ 1224 BMS_HvBattCellVoltMin 65534 "Abnormal" 65535 "Invalid" ;
VAL_ 1224 BMS_Chg_Sts 1 "Parking chagre" 2 "Driving charge" 3 "no charge" 4 "charge complete" 14 "Abnomal" 15 "Invalid" ;
VAL_ 1235 EPS_2_Steer_ReturnRmd_Sts 0 "No_Active" 1 "ON" 2 "OFF" 3 "Reserved" ;
VAL_ 1235 EPS_2_Steer_ReturnRmd 0 "No Tip" 1 "Tip return finish" 2 "Tip return left" 3 "Tip return right" ;
VAL_ 1235 EPS_2_MFS_ShakeSts 0 "No_Active" 1 "ON" 2 "OFF" 3 "reserved" ;
VAL_ 1330 DWD_TextDisp 0 "No Active" 1 "Speed exceed 10km/h" 2 "Speed exceed 5km/h" 3 "Controller pedal undeploy" 4 "Slope exceed 10°" 5 "Driving mode is snow、mud、sand" 6 "Keep low speed" 7 "Out rearview mirror undeploy" 8 "Doors are open" 9 "Trunk are open" 10 "System is fail" 11 "System is not available" 12 "Sys exit" ;
VAL_ 1330 DWD_SoundIndcn 0 "No warning" 1 "Long beep" 2 "3Hz" 3 "1.5Hz" ;
VAL_ 1330 LSensorFailSts 0 "Sensor normal" 1 "Sensor fault" ;
VAL_ 1330 RSensorFailSts 0 "Sensor normal" 1 "Sensor fault" ;
VAL_ 1330 DWD_Distance 0 "No object" 1 "Object in zone 1, 0~5cm" 2 "Object in zone 2, 6~10cm" 3 "Object in zone 3, 11~15cm" 4 "Object in zone 4, 16~20cm" 5 "Object in zone 5, 21~25cm" 6 "Object in zone 6, 26~30cm" 7 "Object in zone 7, 31~35cm" 8 "Object in zone 8, 36~40cm" 9 "Object in zone 9, 41~45cm" 10 "Object in zone 10, 46~50cm" 11 "Object in zone 11, 51~55cm" 12 "Object in zone 12, 56~60cm" 13 "Object in zone 13, 61~65cm" 14 "Object in zone 14, 66~70cm" 15 "Object in zone 15, 71~75cm" 16 "Object in zone 16, 76~80cm" 17 "Object in zone 17, 81~85cm" 18 "Object in zone 18, 86~90cm" 19 "Object in zone 19, 91~95cm" 20 "Object in zone 20, 96~100cm" 21 "Object in zone 21, 101~105cm" 22 "Object in zone 22, 105~110cm" 23 "Object in zone 23, 111~115cm" 24 "Object in zone 24, 116~120cm" 25 "Object in zone 25, 121~125cm" 26 "Object in zone 26, 126~130cm" 27 "Object in zone 27, 131~135cm" 28 "Object in zone 28, 136~140cm" 29 "Object in zone 29, 141~145cm" 30 "Object in zone 30, 146~150cm" ;
VAL_ 1330 DWD_Switch 0 "Not Active" 1 "ON" 2 "OFF" 3 "Reserved" ;
VAL_ 1328 RADAR_1_RadarDetectSts 0 "No_Detecting_Startup" 1 "Front_Radar_Detecting" 2 "Rear_Radar_Detecting" 3 "Not_Used" ;
VAL_ 1328 RADAR_1_RadarWorkSts 0 "Not_Active" 1 "Active" ;
VAL_ 1328 RADAR_1_LHRRadarSensorDistance 63 "Sensor_Err" 62 "Startup" ;
VAL_ 1328 RADAR_1_RHMRRadarSensorDistance 63 "Sensor_Err" 62 "Startup" ;
VAL_ 1328 RADAR_1_LHMRRadarSensorDistance 63 "Sensor_Err" 62 "Startup" ;
VAL_ 1328 RADAR_1_RHRRadarSensorDistance 63 "Sensor_Err" 62 "Startup" ;
VAL_ 1328 RADAR_1_LHFRadarSensorDistance 31 "Sensor_Err" 30 "Startup" ;
VAL_ 1328 RADAR_1_RHFRadarSensorDistance 31 "Sensor_Err" 28 "Not_Used" 29 "Not_Used" 30 "Startup" ;
VAL_ 1328 RADAR_1_ParkingRadarSwSts 0 "Off" 1 "On" ;
VAL_ 1328 RADAR_1_RHMFRadarSensorDistance 31 "Sensor_Err" 30 "Startup" ;
VAL_ 1328 RADAR_1_LHMFRadarSensorDistance 31 "Sensor_Err" 30 "Startup" ;
VAL_ 1328 RADAR_1_AudibleBeepRate 0 "Off" 1 "On" 2 "4Hz" 3 "2Hz" 4 "1Hz" ;
VAL_ 259 EMS_EngineSpeed_Actual 65535 "Invalid" ;
VAL_ 1234 FRZCU_FRSeatHeiFb 0 "Not active" ;
VAL_ 1234 FRZCU_FRSeatLvlFb 0 "Not active" ;
VAL_ 1234 FRZCU_FRSeatBackAgFb 0 "Not active" ;
VAL_ 1234 FRZCU_FRSeatLegSpprtFb 0 "Not active" ;
VAL_ 1234 FRZCU_FRWinSts 0 "Not Active" 1 "Comfort" 2 "Close" 3 "Open" 4 "Other Position" 5 "Closing" 6 "Opening" 7 "Reserved" ;
VAL_ 1234 FRZCU_RRWinSts 0 "Not Active" 1 "Comfort" 2 "Close" 3 "Open" 4 "Other Position" 5 "Closing" 6 "Opening" 7 "Reserved" ;
VAL_ 1234 FRZCU_FRSeatLegRestAngleFb 0 "Not Active" ;
VAL_ 1234 FRZCU_FRSeatCushFb 0 "Not Active" ;
VAL_ 1234 FRZCU_FRSeatNeedMemory 0 "No Request" 1 "Request" ;
VAL_ 1234 FRZCU_FRMemoryFb 0 "Not Active" 1 "Success" 2 "Fail" 3 "Ongoing" ;
VAL_ 1234 FRZCU_FRRecoverFb 0 "Not Active" 1 "Success" 2 "Fail" 3 "Ongoing" ;
VAL_ 1234 FRZCU_EasyEntryExitFb 0 "Not Active" 1 "ON" 2 "OFF" 3 "Not Used" ;
VAL_ 1234 FRZCU_EnjoyableSeatWarning 0 "Not Active" 1 "Buckle tied" 2 "Occupied" ;
VAL_ 1234 FRZCU_EnjoyableSeatSts 0 "Not Active" 1 "Forward Moving" 2 "Backward Moving" ;
VAL_ 1234 SeatHeatLevelsFR 0 "OFF" 1 "Level1" 2 "Level2" 3 "Level3" 4 "AUTO(Reserved)" ;
VAL_ 1234 SeatVentLevelsFR 0 "OFF" 1 "Level1" 2 "Level2" 3 "Level3" ;
VAL_ 1234 SeatHeatLevelsRR 0 "OFF" 1 "Level1" 2 "Level2" 3 "Level3" 4 "AUTO(Reserved)" ;
VAL_ 1234 SeatVentLevelsRR 0 "OFF" 1 "Level1" 2 "Level2" 3 "Level3" ;
VAL_ 1234 FRZCU_FRSeatFoldFb 0 "Not Active" ;
VAL_ 517 MFSR_UP_SW 0 "Not_action" 1 "Pressed" 2 "Stuck" 3 "invalid" ;
VAL_ 517 MFSR_DW_SW 0 "Not_action" 1 "Pressed" 2 "Stuck" 3 "invalid" ;
VAL_ 517 MFSR_Left_SW 0 "Not_action" 1 "Pressed" 2 "Stuck" 3 "invalid" ;
VAL_ 517 MFSR_Right_SW 0 "Not_action" 1 "Pressed" 2 "Stuck" 3 "invalid" ;
VAL_ 517 MFSR_OK_SW 0 "Not_action" 1 "Pressed" 2 "Stuck" 3 "invalid" ;
VAL_ 517 MFSR_Voice_SW 0 "Not_action" 1 "Pressed" 2 "Stuck" 3 "invalid" ;
VAL_ 517 MFSR_Customize 0 "Not_action" 1 "Pressed" 2 "Stuck" 3 "invalid" ;
VAL_ 1096 TMS_AirPurgeReminderSts 0 "Not_Active" 1 "ON" 2 "OFF" 3 "Not_Used" ;
VAL_ 1096 TMS_BT_Reduce_Wind_SpeedSts 0 "Off" 1 "Active" ;
VAL_ 1096 TMS_First_BlowingSts 0 "Off" 1 "Active" ;
VAL_ 1096 TMS_CirculationInTunnelsSts 0 "Off" 1 "Active" ;
VAL_ 1096 TMS_crosscountry_coolingSts 0 "No_Request" 1 "Active" 2 "Not_Active" ;
VAL_ 1096 TMS_ParkingAirConditioningStatus 0 "Inactive" 1 "AUTO" 2 "ventilate" ;
VAL_ 1096 TMS_CoolantFillSts 0 "No_Request" 1 "Request" ;
VAL_ 1096 TMS_UVC_ControlSts 0 "No_Request" 1 "Close_Request" 2 "Open_Request" 3 "AUTO" ;
VAL_ 1096 TMS_UVC_LuminanceSts 0 "No_Request" 1 "level_1" 2 "level_2" 3 "Reserved" 4 "Reserved" 5 "Reserved" 6 "Reserved" 7 "Reserved" ;
VAL_ 1096 TMS_ICC_Lightoff_Sts 0 "No_Request" 1 "FraganceLight_on_Sts" 2 "FraganceLight_off_Sts" 3 "Reserved" ;
VAL_ 1096 TMS_ICC_Memoff_Sts 0 "No_Request" 1 "FraganceMem_on" 2 "FraganceMem_off" 3 "Reserved" ;
VAL_ 1096 TMS_keepwarmSet_TemperatureSts 0 "Temperature_20°C" 1 "Temperature_25°C" 2 "Temperature_30°C" 3 "Temperature_35°C" 4 "Temperature_40°C" 5 "Temperature_45°C" 6 "Temperature_50°C" 7 "Temperature_55°C" 8 "Temperature_60°C" 9 "reserved" 10 "reserved" 11 "reserved" 12 "reserved" 13 "reserved" 14 "reserved" 15 "reserved" 16 "reserved" 17 "reserved" 18 "reserved" 19 "reserved" 20 "reserved" 21 "reserved" 22 "reserved" 23 "reserved" 24 "reserved" 25 "reserved" 26 "reserved" 27 "reserved" 28 "reserved" 29 "reserved" 30 "reserved" 31 "reserved" 32 "reserved" 33 "reserved" 34 "reserved" 35 "reserved" 36 "reserved" 37 "reserved" 38 "reserved" 39 "reserved" 40 "reserved" 41 "reserved" 42 "reserved" 43 "reserved" 44 "reserved" 45 "reserved" 46 "reserved" 47 "reserved" 48 "reserved" 49 "reserved" 50 "reserved" 51 "reserved" 52 "reserved" 53 "reserved" 54 "reserved" 55 "reserved" 56 "reserved" 57 "reserved" 58 "reserved" 59 "reserved" 60 "reserved" 61 "reserved" 62 "reserved" 63 "reserved" 64 "reserved" 65 "reserved" 66 "reserved" 67 "reserved" 68 "reserved" 69 "reserved" 70 "reserved" 71 "reserved" 72 "reserved" 73 "reserved" 74 "reserved" 75 "reserved" 76 "reserved" 77 "reserved" 78 "reserved" 79 "reserved" 80 "reserved" 81 "reserved" 82 "reserved" 83 "reserved" 84 "reserved" 85 "reserved" 86 "reserved" 87 "reserved" 88 "reserved" 89 "reserved" 90 "reserved" 91 "reserved" 92 "reserved" 93 "reserved" 94 "reserved" 95 "reserved" 96 "reserved" 97 "reserved" 98 "reserved" 99 "reserved" 100 "reserved" 101 "reserved" 102 "reserved" 103 "reserved" 104 "reserved" 105 "reserved" 106 "reserved" 107 "reserved" 108 "reserved" 109 "reserved" 110 "reserved" 111 "reserved" 112 "reserved" 113 "reserved" 114 "reserved" 115 "reserved" 116 "reserved" 117 "reserved" 118 "reserved" 119 "reserved" 120 "reserved" 121 "reserved" 122 "reserved" 123 "reserved" 124 "reserved" 125 "reserved" 126 "reserved" 127 "reserved" 128 "reserved" 129 "reserved" 130 "reserved" 131 "reserved" 132 "reserved" 133 "reserved" 134 "reserved" 135 "reserved" 136 "reserved" 137 "reserved" 138 "reserved" 139 "reserved" 140 "reserved" 141 "reserved" 142 "reserved" 143 "reserved" 144 "reserved" 145 "reserved" 146 "reserved" 147 "reserved" 148 "reserved" 149 "reserved" 150 "reserved" 151 "reserved" 152 "reserved" 153 "reserved" 154 "reserved" 155 "reserved" 156 "reserved" 157 "reserved" 158 "reserved" 159 "reserved" 160 "reserved" 161 "reserved" 162 "reserved" 163 "reserved" 164 "reserved" 165 "reserved" 166 "reserved" 167 "reserved" 168 "reserved" 169 "reserved" 170 "reserved" 171 "reserved" 172 "reserved" 173 "reserved" 174 "reserved" 175 "reserved" 176 "reserved" 177 "reserved" 178 "reserved" 179 "reserved" 180 "reserved" 181 "reserved" 182 "reserved" 183 "reserved" 184 "reserved" 185 "reserved" 186 "reserved" 187 "reserved" 188 "reserved" 189 "reserved" 190 "reserved" 191 "reserved" 192 "reserved" 193 "reserved" 194 "reserved" 195 "reserved" 196 "reserved" 197 "reserved" 198 "reserved" 199 "reserved" 200 "reserved" 201 "reserved" 202 "reserved" 203 "reserved" 204 "reserved" 205 "reserved" 206 "reserved" 207 "reserved" 208 "reserved" 209 "reserved" 210 "reserved" 211 "reserved" 212 "reserved" 213 "reserved" 214 "reserved" 215 "reserved" 216 "reserved" 217 "reserved" 218 "reserved" 219 "reserved" 220 "reserved" 221 "reserved" 222 "reserved" 223 "reserved" 224 "reserved" 225 "reserved" 226 "reserved" 227 "reserved" 228 "reserved" 229 "reserved" 230 "reserved" 231 "reserved" 232 "reserved" 233 "reserved" 234 "reserved" 235 "reserved" 236 "reserved" 237 "reserved" 238 "reserved" 239 "reserved" 240 "reserved" 241 "reserved" 242 "reserved" 243 "reserved" 244 "reserved" 245 "reserved" 246 "reserved" 247 "reserved" 248 "reserved" 249 "reserved" 250 "reserved" 251 "reserved" 252 "reserved" 253 "reserved" 254 "reserved" ;
VAL_ 1096 TMS_BiochemicalFuncSts 0 "Not Active" 1 "ON" 2 "OFF" 3 "Reserved" ;
VAL_ 1096 TMS_TimedVentilationSts 0 "Not Active" 1 "ON" 2 "OFF" 3 "Reserved" ;
VAL_ 1240 TMS_CFSSwitchFb 0 "OFF" 1 "ON" ;
VAL_ 1240 TDU_CFSPosOneType 0 "No Frag" 1 "Type 1" 2 "Type 2" 3 "Type 3" 4 "Type 4" 5 "Type 5" 6 "Unfilled" 7 "Position one active" 8 "Type 6" 9 "Type7" 10 "Type8" 11 "Type9" 12 "Type10" 13 "Type11" 14 "Type12" 15 "Not Active" ;
VAL_ 1240 TDU_CFSPosTwoType 0 "No Frag" 1 "Type 1" 2 "Type 2" 3 "Type 3" 4 "Type 4" 5 "Type 5" 6 "Unfilled" 7 "Position one active" 8 "Type 6" 9 "Type7" 10 "Type8" 11 "Type9" 12 "Type10" 13 "Type11" 14 "Type12" 15 "Not Active" ;
VAL_ 1240 TDU_CFSPosThreeType 0 "No Frag" 1 "Type 1" 2 "Type 2" 3 "Type 3" 4 "Type 4" 5 "Type 5" 6 "Unfilled" 7 "Position one active" 8 "Type 6" 9 "Type7" 10 "Type8" 11 "Type9" 12 "Type10" 13 "Type11" 14 "Type12" 15 "Not Active" ;
VAL_ 1240 TDU_CFSRunOut 0 "No Unset" 1 "Position One Runout" 2 "Position Two Runout" 3 "Position One and Two Runout" 4 "Position Three Runout" 5 "Position One and Three Runout" 6 "Position Two and Three Runout" 7 "Position One and Two and Three Runout" 8 "Reserved" 9 "Reserved" 10 "Reserved" 11 "Reserved" 12 "Reserved" 13 "Reserved" 14 "Reserved" 15 "Not Active" ;
VAL_ 1240 TMS_CFSShortWarn 0 "No Unset" 1 "Position One ShortWarn" 2 "Position Two ShortWarn" 3 "Position One and Two ShortWarn" 4 "Position Three ShortWarn" 5 "Position One and Three ShortWarn" 6 "Position Two and Three ShortWarn" 7 "Position One and Two and Three ShortWarn" 8 "Reserved" 9 "Reserved" 10 "Reserved" 11 "Reserved" 12 "Reserved" 13 "Reserved" 14 "Reserved" 15 "Not Active" ;
VAL_ 1240 TMS_CFSLevelSetFb 0 "Not Active" 1 "Level 1" 2 "Level 2" 3 "Level 3" 4 "Reserved" 5 "Reserved" 6 "Reserved" 7 "Reserved" 8 "Reserved" 9 "Reserved" 10 "Reserved" 11 "Reserved" 12 "Reserved" 13 "Reserved" 14 "Reserved" 15 "Reserved" ;
VAL_ 1240 TMS_CFSPosSetFb 0 "Not Active" 1 "Position One" 2 "Position Two" 3 "Position Three" ;
VAL_ 1240 TMS_PM25SwitchFb 0 "OFF" 1 "On" ;
VAL_ 1240 TMS_ThrModeStsFb 0 "Blow Face" 1 "Blow Face and Blow Foot" 2 "Blow Foot" 3 "Auto" 4 "Reserved" 5 "Reserved" 6 "Reserved" 7 "Not Active" ;
VAL_ 1240 TMS_ThrSetTempFb_C 31 "Not active" ;
VAL_ 1240 TMS_ThrCLMSwitchFb 0 "OFF" 1 "On" ;
VAL_ 1240 TMS_ThrAutoSwitchFb 0 "Auto OFF" 1 "Auto On" ;
VAL_ 1240 TMS_ThrBlowSpeedLevelKeyStsFb 0 "Not Active" 1 "Level  1" 2 "Level  2" 3 "Level  3" 4 "Level  4" 5 "Level  5" 6 "Level  6" 7 "Level  7" 8 "Level  0" 9 "Reserved" 10 "Reserved" 11 "Reserved" 12 "Reserved" 13 "Reserved" 14 "Reserved" 15 "Reserved" ;
VAL_ 638 FRZCU_HoodSts 0 "Close" 1 "Ajar_" 2 "full_open" 3 "Reserved" ;
VAL_ 638 FRZCU_AuthenResult 0 "not_success" 1 "success_" ;
VAL_ 638 FRZCU_PowerMode 0 "Off" 1 "Comfortable" 2 "ON" 3 "Reserved" ;
VAL_ 638 FRZCU_TrunkSts 0 "Close" 1 "Ajar_" 2 "full_open" 3 "Reserved" ;
VAL_ 638 FRZCU_HandleSwitchStsFL 0 "Not_Active" 1 "Outside" 2 "Inside" 3 "Bothside" ;
VAL_ 638 FRZCU_HandleSwitchStsFR 0 "Not_Active" 1 "Outside" 2 "Inside" 3 "Bothside" ;
VAL_ 638 FRZCU_HandleSwitchStsRR 0 "Not_Active" 1 "Outside" 2 "Inside" 3 "Bothside" ;
VAL_ 638 FRZCU_HandleSwitchStsRL 0 "Not_Active" 1 "Outside" 2 "Inside" 3 "Bothside" ;
VAL_ 638 SeatLength_target_Passenger 0 "Not_active" 1 "0" 2 "10%" 3 "20%" 4 "30%" 5 "40%" 6 "50%" 7 "60%" 8 "70%" 9 "80%" 10 "90%" 11 "100%" 12 "Reserved" 13 "Reserved" 14 "Reserved" 15 "Reserved" ;
VAL_ 638 SeatBackrest_target_Passenger 0 "Not_active" 1 "0" 2 "5%" 3 "10%" 4 "15%" 5 "20%" 6 "25%" 7 "30%" 8 "35%" 9 "40%" 10 "45%" 11 "50%" 12 "55%" 13 "60%" 14 "65%" 15 "70%" 16 "75%" 17 "80%" 18 "85%" 19 "90%" 20 "95%" 21 "100%" 22 "Reserved" 23 "Reserved" 24 "Reserved" 25 "Reserved" 26 "Reserved" 27 "Reserved" 28 "Reserved" 29 "Reserved" 30 "Reserved" 31 "Reserved" ;
VAL_ 638 FRZCU_TrunkLockSts 0 "Locked" 1 "Unlocked" 2 "Superlocked" 3 "Unknown" ;
VAL_ 638 FRZCU_HoodLockSts 0 "Locked" 1 "Unlocked" 2 "Superlocked" 3 "Unknown" ;
VAL_ 638 FrontBackSpeedAdj_Cmd 0 "No_Request" 1 "Low" 2 "Medium" 3 "High" 4 "Reserved" 5 "Reserved" 6 "Reserved" 7 "invalid" ;
VAL_ 638 FRZCU_GloveboxSW 0 "OFF" 1 "ON" ;
VAL_ 638 FRZCU_FRReleaseLockSts 0 "None" 1 "Releasing" 2 "Released" 3 "Reset" 4 "Resetting" 5 "Reserved" 6 "Reserved" 7 "Reserved" ;
VAL_ 638 FRZCU_RRReleaseLockSts 0 "None" 1 "Releasing" 2 "Released" 3 "Reset" 4 "Resetting" 5 "Reserved" 6 "Reserved" 7 "Reserved" ;
VAL_ 638 FRZCU_PELockInKeyWarning 0 "Not_Active" 1 "Active" ;
VAL_ 638 FRZCU_PowerOFFWarning 0 "Not_Active" 1 "Active" ;
VAL_ 638 FRZCU_KeylessWarning 0 "Not_Active" 1 "Active" ;
VAL_ 638 FRZCU_OTAPwrDwnReqFb 0 "No_Command" 1 "Success" 2 "Fail" 3 "Resrved" ;
VAL_ 638 FRZCU_OTAPwrOnReqFb 0 "No_Command" 1 "Success" 2 "Fail" 3 "Resrved" ;
VAL_ 949 PEPS_InformationSource 0 "Not_Active" 1 "Smart_Information" 2 "RKE_Information" 3 "Near_Access" ;
VAL_ 949 PEPS_OrderInformation 0 "OFF" 1 "Lock" 2 "Unlock" 4 "Trunk" 5 "Welcome_On" 6 "Welcome_Off" 7 "RKE_Search_Car" 8 "Power_Slide_Door_Left" ;
VAL_ 949 PEPS_IDInformation 0 "Not_Active" 1 "Transmitter_1" 2 "Transmitter_2" 3 "Transmitter_3" 4 "Transmitter_4" 5 "Transmitter_BLT1" 6 "Transmitter_BLT2" 7 "Transmitter_BLT3" 8 "Transmitter_NFC1" 9 "Transmitter_NFC2" 10 "Transmitter_NFC3" ;
VAL_ 949 PEPS_KeySts 0 "Not_Active" 1 "PEPS_Key_In" 2 "PEPS_Key_Near_Flant" 3 "PEPS_Key_Near_Frant" 4 "PEPS_Key_Near_Trunkant" 5 "Unknow" ;
VAL_ 949 PEPS_ETRUnLockReq 0 "Not_Request" 1 "Request" ;
VAL_ 1028 PEPS_WelcomeON 0 "Default_value" 1 "Welcome_light_OFF" 2 "Welcome_light_ON" 3 "Reserved" ;
VAL_ 1028 PEPS_VehicleSearchReq 0 "No_Request" 1 "Request" 2 "Reseved" 3 "Reseved" ;
VAL_ 1028 PEPS_SATOReminder 0 "No_Command" 1 "Remind_stop" 2 "Remind_start" 3 "Reseved" ;
VAL_ 1028 PEPS_PLGUnlockReq 0 "Not_Request" 1 "Request" 2 "Reseved" 3 "Reseved" ;
VAL_ 1028 PEPS_RKETrunkSts 0 "Not_Active" 1 "Long_Press" 2 "Short_Press" 3 "Not_Used" ;
VAL_ 1028 PEPS_SSBInhibitCWCSts 0 "Default" 1 "Disable" 2 "Reseved" 3 "Reseved" ;
VAL_ 1028 PEPS_WirelessChargingCtrSts 0 "Default" 1 "Disable" 2 "Reseved" 3 "Reseved" ;
VAL_ 1028 PEPS_EmgyShutdown 0 "No_Happen" 1 "Happen" 2 "Reseved" 3 "Reseved" ;
VAL_ 1028 PEPS_SSBInputFailure 0 "Not_Fail" 1 "Fail" 2 "Reseved" 3 "Reseved" ;
VAL_ 1028 PEPS_SmartSystemWarning1_1 0 "Normal" 1 "Identifier_is_out_of_vehicle" 2 "Reseved" 3 "Reseved" ;
VAL_ 1028 PEPS_SmartSystemWarning2_2 0 "Normal" 1 "Identifier_is_out_of_vehicle_range_when_vehicle_starts_running" 2 "Reseved" 3 "Reseved" ;
VAL_ 1028 PEPS_SmartSystemWarning3_1 0 "Normal" 1 "Identifier_low_battery_detected" 2 "Reseved" 3 "Reseved" ;
VAL_ 1028 PEPS_SmartSystemWarning3_2 0 "Normal" 1 "Engine_start_not_possible_if_gear_box_not_in_P_or_N_position" 2 "Reseved" 3 "Reseved" ;
VAL_ 1028 PEPS_SmartSystemWarning4_2 0 "Normal_" 1 "Engine_start_attempted_without_pressing_clutch/brake_pedal" 2 "Reseved" 3 "Reseved" ;
VAL_ 1028 PEPS_SmartSystemWarning4_3 0 "Normal" 1 "Switching_OFF_while_Gear_box_not_in_P_position" 2 "Reseved" 3 "Reseved" ;
VAL_ 1028 PEPS_SystemWarning 0 "Normal" 1 "Fault" 2 "Reseved" 3 "Reseved" ;
VAL_ 1028 PEPS_BLTKeyPESts 0 "OFF" 1 "ON" 2 "Reseved" 3 "Reseved" ;
VAL_ 1291 BMS_TBOXHvBattMaxT 254 "Abnormal" 255 "Invalid" ;
VAL_ 1291 BMS_TBOXHvBattMinT 254 "Abnormal" 255 "Invalid" ;
VAL_ 1291 BMS_SOCLight 127 "Invalid" ;
VAL_ 1104 RLCR_2_RCWWarn 0 "No Warning" 1 "Level1 Warning" 2 "Level2 Warning" 3 "Not Used" ;
VAL_ 1104 RLCR_2_RCTAWarn 0 "No Warning" 1 "Warning" ;
VAL_ 1104 RLCR_2_BSDLCWONOFFSts 0 "Not active" 1 "OFF" 2 "ON" 3 "Reserved" ;
VAL_ 1104 RLCR_2_DOWONOFFSts 0 "Not active" 1 "OFF" 2 "ON" 3 "Reserved" ;
VAL_ 1104 RLCR_2_RCWONOFFSts 0 "Not active" 1 "OFF" 2 "ON" 3 "Reserved" ;
VAL_ 1104 RLCR_2_RCTARCTBONOFFSts 0 "OFF" 1 "warning" 2 "Reserved" 3 "Reserved" ;
VAL_ 1271 RRCR_2_RCWWarn 0 "No Warning" 1 "Level1 Warning" 2 "Level2 Warning" 3 "Not Used" ;
VAL_ 1271 RRCR_2_RCTAWarn 0 "No Warning" 1 "Warning" ;
VAL_ 1271 RRCR_2_BSDLCWONOFFSts 0 "Not active" 1 "OFF" 2 "ON" 3 "Reserved" ;
VAL_ 1271 RRCR_2_DOWONOFFSts 0 "Not active" 1 "OFF" 2 "ON" 3 "Reserved" ;
VAL_ 1271 RRCR_2_RCWONOFFSts 0 "Not active" 1 "OFF" 2 "ON" 3 "Reserved" ;
VAL_ 1271 RRCR_2_RCTARCTBONOFFSts 0 "OFF" 1 "warning" 2 "Reserved" 3 "Reserved" ;
VAL_ 587 LHRPulseCounterFailSts 0 "Fail Not Present" 1 "Fail Present" ;
VAL_ 587 RHRPulseCounterFailSts 0 "Fail Not Present" 1 "Fail Present" ;
VAL_ 587 RHFPulseCounterFailSts 0 "Fail Not Present" 1 "Fail Present" ;
VAL_ 587 LHFPulseCounterFailSts 0 "Fail Not Present" 1 "Fail Present" ;
VAL_ 587 LHFWheelDriveDirection 0 "Init" 1 "Forward" 2 "Backward" 3 "Stop" 4 "Invalid" 5 "reserved" 6 "reserved" 7 "reserved" ;
VAL_ 587 RHFWheelDriveDirection 0 "Init" 1 "Forward" 2 "Backward" 3 "Stop" 4 "Invalid" 5 "reserved" 6 "reserved" 7 "reserved" ;
VAL_ 587 LHRWheelDriveDirection 0 "Init" 1 "Forward" 2 "Backward" 3 "Stop" 4 "Invalid" 5 "reserved" 6 "reserved" 7 "reserved" ;
VAL_ 587 RHRWheelDriveDirection 0 "Init" 1 "Forward" 2 "Backward" 3 "Stop" 4 "Invalid" 5 "reserved" 6 "reserved" 7 "reserved" ;
VAL_ 1338 FMCU_ErrLvlDis 0 "No Error" 1 "Err_level1" 2 "Err_level2" 3 "Err_level3" 4 "Err_level4" 5 "Err_level5" 6 "Err_level6" ;
VAL_ 1338 FMCU_SpdAct_EDR 65535 "Invalid" ;
VAL_ 777 ISGF_ErrLvl 0 "No Error" 1 "Err_level1" 2 "Err_level2" 3 "Err_level3" 4 "Err_level4" 5 "Err_level5" 6 "Err_level6" ;
VAL_ 1403 RMCU_ErrLvlDis 0 "No Error" 1 "Err_level1" 2 "Err_level2" 3 "Err_level3" 4 "Err_level4" 5 "Err_level5" 6 "Err_level6" ;
VAL_ 1403 RMCU_Speed_EDR 65535 "Invalid" ;
VAL_ 1299 BMS_PackVoltageDis 65534 "Abnormal" 65535 "Invalid" ;
VAL_ 1299 BMS_PackCurrentDis 65534 "Abnormal" 65535 "Invalid" ;
VAL_ 1099 ISGF_SysTempOvrInd 0 "Lamp off" 1 "Lamp on" ;
VAL_ 1130 TCU_23_GBFaultstatus 0 "No failure" 1 "GB failure" 2 "High oil over temperature" 3 "Clutch over temperature" ;
VAL_ 1130 TCU_23_TeachInState 0 "Default" 1 "Successful" 2 "Fault" 3 "Teach in process" 4 "require teach in" ;
VAL_ 1180 ACU_1_AirBagFailSts 0 "Fail no present, lamp off" 1 "Fail no present, lamp flashing" 2 "Fail present, lamp on" 3 "Lamp on, but no warning information displaying on the LCD" ;
VAL_ 1180 ACU_1_ThdRowLBeltWarning 0 "No Warning" 1 "Warning" ;
VAL_ 1180 ACU_1_ThdRowRBeltWarning 0 "No Warning" 1 "Warning" ;
VAL_ 1180 ACU_1_PsngrSeatBeltWarning 0 "Not warning" 1 "Reserve" 2 "Warning" 3 "Not used" ;
VAL_ 1180 ACU_1_SecRowLBeltWarning 0 "No Warning" 1 "Warning" ;
VAL_ 1180 ACU_1_SecRowMBeltWarning 0 "No Warning" 1 "Warning" ;
VAL_ 1180 ACU_1_SecRowRBeltWarning 0 "No Warning" 1 "Warning" ;
VAL_ 1180 ACU_1_PsngrSeatOccupiedSts 0 "not occupied" 1 "occupied" 2 "open circuit" 3 "short circuit" ;
VAL_ 811 BMS_Chg_Sts 1 "Parking chagre" 2 "Driving charge" 3 "no charge" 4 "charge complete" 14 "Abnomal" 15 "Invalid" ;
VAL_ 1269 LISDShowCMDSts 0 "OFF" 1 "ON" ;
VAL_ 1269 LISDShowModeSts 0 "Default value" 1 "BatteryCharging" 2 "Brand" 3 "TiresPressures" 4 "Weather" 5 "Greetings" 6 "Package" 7 "Panda" 8 "PredestrianCrossing" 9 "PingPong" 10 "Kite" 11 "Coffee" 12 "Reserved" 13 "Reserved" 14 "Reserved" 15 "Reserved" ;
VAL_ 1269 LISD_TransmitStatus 0 "Default value" 1 "Success" 2 "Fail" 3 "Idle" ;
VAL_ 1269 LISD_DisplayStatus 0 "Not Active" 1 "ON" 2 "OFF" 3 "Reserved" ;
VAL_ 1269 LISD_ParkingShowModSts 0 "Default value" 1 "Mode1" 2 "Mode2" 3 "Mode3" 4 "Mode4" 5 "Reserved" 6 "Reserved" 7 "Reserved" 8 "Reserved" 9 "Reserved" 10 "Reserved" 11 "Reserved" 12 "Reserved" 13 "Reserved" 14 "Reserved" 15 "Reserved" ;
VAL_ 1269 LISD_ParkingShowCMDSts 0 "Not Active" 1 "ON" 2 "OFF" 3 "Reserved" ;
VAL_ 1233 RISDShowCMDSts 0 "OFF" 1 "ON" ;
VAL_ 1233 RISDShowModeSts 0 "Default value" 1 "BatteryCharging" 2 "Brand" 3 "TiresPressures" 4 "Weather" 5 "Greetings" 6 "Package" 7 "Panda" 8 "PredestrianCrossing" 9 "PingPong" 10 "Kite" 11 "Coffee" 12 "Reserved" 13 "Reserved" 14 "Reserved" 15 "Reserved" ;
VAL_ 1233 RISD_TransmitStatus 0 "Default value" 1 "Success" 2 "Fail" 3 "Idle" ;
VAL_ 1233 RISD_DisplayStatus 0 "Not Active" 1 "ON" 2 "OFF" ;
VAL_ 1233 RISD_ParkingShowModSts 0 "Default value" 1 "Mode1" 2 "Mode2" 3 "Mode3" 4 "Mode4" 5 "Reserved" 6 "Reserved" 7 "Reserved" 8 "Reserved" 9 "Reserved" 10 "Reserved" 11 "Reserved" 12 "Reserved" 13 "Reserved" 14 "Reserved" 15 "Reserved" ;
VAL_ 1233 RISD_ParkingShowCMDSts 0 "Not Active" 1 "ON" 2 "OFF" ;
VAL_ 1169 LC_DIYMusicShowModSts 0 "Not Active" 1 "Mode1" 2 "Mode2" 3 "Reserved" ;
VAL_ 1169 LC_RandomMusicShowSts 0 "Not Active" 1 "Active" 2 "Reserved" 3 "Reserved" ;
VAL_ 1169 LC_LiShowModSts 0 "Not Active" 1 "OFF" 2 "Mode1" 3 "Mode2" 4 "Mode3" 5 "Mode4(Reserved)" 6 "Mode5(Reserved)" ;
VAL_ 1427 ILCF_1_LogoParkingSts 0 "Not Active" 1 "ON" 2 "OFF" 3 "Reserved" ;
VAL_ 1427 ILCF_1_LogoChargingSts 0 "Not Active" 1 "ON" 2 "OFF" 3 "Reserved" ;
VAL_ 1427 ILCF_1_DIYMusicShowModSts 0 "Not Active" 1 "Mode1" 2 "Mode2" 3 "Mode3" ;
VAL_ 1427 ILCF_1_RandomMusicShowSts 0 "Not Active" 1 "Active" 2 "Reserved" 3 "Reserved" ;
VAL_ 1427 ILCF_1_LogoColorAdjSts 0 "Not Active" ;
VAL_ 821 ADS_5_ILOASts 0 "Off" 1 "On" 2 "Evasioning" 3 "Retreat" 4 "Evasion finished" 5 "None" 6 "Reserved" 7 "Reserved" ;
VAL_ 821 ADS_5_ICAQuitReason 0 "None" 1 "Bad Weather" 2 "Large curve" 3 "ODD not meet" 4 "reserved" 5 "reserved" 6 "reserved" 7 "reserved" ;
VAL_ 821 ADS_5_ISLISt 0 "OFF" 1 "ON" 2 "failure" 3 "Reserved" ;
VAL_ 821 ADS_5_ILOATextInfo 0 "None" 1 "Evading oversized vehicle" 2 "Avoiding obstacles" 3 "Reserved" ;
VAL_ 821 ADS_5_ILOAActdirection 0 "Not active" 1 "Left" 2 "Right" 3 "Reserved" ;
VAL_ 821 ADS_5_LKS_warning 0 "no warning" 1 "warning" ;
VAL_ 821 ADS_5_ISLIOverSpeedWarn 0 "No warning" 1 "Waning1" 2 "Waning2" 3 "Waning3" ;
VAL_ 821 ADS_5_ISLISpeedLimitSign 0 "No display" 1 "Cancellation sign" 2 "5" 3 "10" 4 "15" 5 "20" 6 "25" 7 "30" 8 "35" 9 "40" 10 "45" 11 "50" 12 "55" 13 "60" 14 "65" 15 "70" 16 "75" 17 "80" 18 "85" 19 "90" 20 "95" 21 "100" 22 "105" 23 "110" 24 "115" 25 "120" 26 "125" 27 "130" 28 "135" 29 "140" 30 "145" 31 "150" 32 "155" 33 "160" 34 "165" 35 "170" 36 "175" 37 "180" 38 "185" 39 "190" 40 "195" 41 "200" 42 "Reserved" 43 "Reserved" 44 "Reserved" 45 "Reserved" 46 "Reserved" 47 "Reserved" 48 "Reserved" 49 "Reserved" 50 "Reserved" 51 "Reserved" 52 "Reserved" 53 "Reserved" 54 "Reserved" 55 "Reserved" 56 "Reserved" 57 "Reserved" 58 "Reserved" 59 "Reserved" 60 "Reserved" 61 "Reserved" 62 "Reserved" 63 "Reserved" 64 "Reserved" 65 "Reserved" 66 "Reserved" 67 "Reserved" 68 "Reserved" 69 "Reserved" 70 "Reserved" 71 "Reserved" 72 "Reserved" 73 "Reserved" 74 "Reserved" 75 "Reserved" 76 "Reserved" 77 "Reserved" 78 "Reserved" 79 "Reserved" 80 "Reserved" 81 "Reserved" 82 "Reserved" 83 "Reserved" 84 "Reserved" 85 "Reserved" 86 "Reserved" 87 "Reserved" 88 "Reserved" 89 "Reserved" 90 "Reserved" 91 "Reserved" 92 "Reserved" 93 "Reserved" 94 "Reserved" 95 "Reserved" 96 "Reserved" 97 "Reserved" 98 "Reserved" 99 "Reserved" 100 "Reserved" 101 "Reserved" 102 "Reserved" 103 "Reserved" 104 "Reserved" 105 "Reserved" 106 "Reserved" 107 "Reserved" 108 "Reserved" 109 "Reserved" 110 "Reserved" 111 "Reserved" 112 "Reserved" 113 "Reserved" 114 "Reserved" 115 "Reserved" 116 "Reserved" 117 "Reserved" 118 "Reserved" 119 "Reserved" 120 "Reserved" 121 "Reserved" 122 "Reserved" 123 "Reserved" 124 "Reserved" 125 "Reserved" 126 "Reserved" 127 "Reserved" 128 "Reserved" 129 "Reserved" 130 "Reserved" 131 "Reserved" 132 "Reserved" 133 "Reserved" 134 "Reserved" 135 "Reserved" 136 "Reserved" 137 "Reserved" 138 "Reserved" 139 "Reserved" 140 "Reserved" 141 "Reserved" 142 "Reserved" 143 "Reserved" 144 "Reserved" 145 "Reserved" 146 "Reserved" 147 "Reserved" 148 "Reserved" 149 "Reserved" 150 "Reserved" 151 "Reserved" 152 "Reserved" 153 "Reserved" 154 "Reserved" 155 "Reserved" 156 "Reserved" 157 "Reserved" 158 "Reserved" 159 "Reserved" 160 "Reserved" 161 "Reserved" 162 "Reserved" 163 "Reserved" 164 "Reserved" 165 "Reserved" 166 "Reserved" 167 "Reserved" 168 "Reserved" 169 "Reserved" 170 "Reserved" 171 "Reserved" 172 "Reserved" 173 "Reserved" 174 "Reserved" 175 "Reserved" 176 "Reserved" 177 "Reserved" 178 "Reserved" 179 "Reserved" 180 "Reserved" 181 "Reserved" 182 "Reserved" 183 "Reserved" 184 "Reserved" 185 "Reserved" 186 "Reserved" 187 "Reserved" 188 "Reserved" 189 "Reserved" 190 "Reserved" 191 "Reserved" 192 "Reserved" 193 "Reserved" 194 "Reserved" 195 "Reserved" 196 "Reserved" 197 "Reserved" 198 "Reserved" 199 "Reserved" 200 "Reserved" 201 "Reserved" 202 "Reserved" 203 "Reserved" 204 "Reserved" 205 "Reserved" 206 "Reserved" 207 "Reserved" 208 "Reserved" 209 "Reserved" 210 "Reserved" 211 "Reserved" 212 "Reserved" 213 "Reserved" 214 "Reserved" 215 "Reserved" 216 "Reserved" 217 "Reserved" 218 "Reserved" 219 "Reserved" 220 "Reserved" 221 "Reserved" 222 "Reserved" 223 "Reserved" 224 "Reserved" 225 "Reserved" 226 "Reserved" 227 "Reserved" 228 "Reserved" 229 "Reserved" 230 "Reserved" 231 "Reserved" 232 "Reserved" 233 "Reserved" 234 "Reserved" 235 "Reserved" 236 "Reserved" 237 "Reserved" 238 "Reserved" 239 "Reserved" 240 "Reserved" 241 "Reserved" 242 "Reserved" 243 "Reserved" 244 "Reserved" 245 "Reserved" 246 "Reserved" 247 "Reserved" 248 "Reserved" 249 "Reserved" 250 "Reserved" 251 "Reserved" 252 "Reserved" 253 "Reserved" 254 "Reserved" 255 "Reserved" ;
VAL_ 821 ADS_5_EgoLeftLineHeatgAg 511 "Invalid" ;
VAL_ 821 ADS_5_EgoLeLineID 0 "Invalid" 1 "Valid" ;
VAL_ 821 ADS_5_EgoLeLineColor 0 "No display" 1 "Color_Unknown" 2 "Color_White" 3 "Color_Yellow" ;
VAL_ 821 ADS_5_EgoLeLineTyp 0 "No display" 1 "Type_Unknown" 2 "Type_Solid_Line" 3 "Type_Dashed_Line" ;
VAL_ 821 ADS_5_EgoLeLineHozlDst 511 "Invalid" ;
VAL_ 821 ADS_5_NeborLeLineID 0 "Invalid" 1 "Valid" ;
VAL_ 821 ADS_5_NeborLeLineColor 0 "No display" 1 "Color_Unknown" 2 "Color_White" 3 "Color_Yellow" ;
VAL_ 821 ADS_5_NeborLeLineTyp 0 "No display" 1 "Type_Unknown" 2 "Type_Solid_Line" 3 "Type_Dashed_Line" ;
VAL_ 821 ADS_5_EgoLeLineCrvt 1023 "Invalid" ;
VAL_ 821 ADS_5_NeborLeLineHozlDst 511 "Invalid" ;
VAL_ 821 ADS_5_NeborRiLineID 0 "Invalid" 1 "Valid" ;
VAL_ 821 ADS_5_NeborRiLineColor 0 "No display" 1 "Color_Unknown" 2 "Color_White" 3 "Color_Yellow" ;
VAL_ 821 ADS_5_NeborRiLineTyp 0 "No display" 1 "Type_Unknown" 2 "Type_Solid_Line" 3 "Type_Dashed_Line" ;
VAL_ 821 ADS_5_NeborLeLineCrvt 1023 "Invalid" ;
VAL_ 821 ADS_5_NeborRiLineHozlDst 511 "Invalid" ;
VAL_ 821 ADS_5_ELKSettingSt 0 "None" 1 "On" 2 "Off" 3 "reserved" ;
VAL_ 821 ADS_5_LDWLDPSnvtySet 0 "None" 1 "high" 2 "low" 3 "reserved" ;
VAL_ 821 ADS_5_LDWWarnType 0 "None" 1 "warning only" 2 "vibration  only" 3 "warning and vibration" ;
VAL_ 821 ADS_5_NeborRiLineCrvt 1023 "Invalid" ;
VAL_ 821 ADS_5_IESSwtSet 0 "None" 1 "ON" 2 "Off" 3 "reserved" ;
VAL_ 821 ADS_5_IHCSettingSt 0 "None" 1 "ON" 2 "OFF" 3 "reserved" ;
VAL_ 821 ADS_5_ISLIWarningMod 0 "None" 1 "Display warning;" 2 "Sound+display warning" 3 "Off" ;
VAL_ 821 ADS_5_ICAEnableBtnSts 0 "None" 1 "ON" 2 "Off" 3 "reserved" ;
VAL_ 821 ADS_5_FCM_Camera_textinfo 0 "Camera normal" 1 "Camera failure" 2 "Camera blocked" 3 "Camera high temperature" ;
VAL_ 821 ADS_5_EgoRiLineID 0 "Invalid" 1 "Valid" ;
VAL_ 821 ADS_5_EgoRiLineTyp 0 "No display" 1 "Type_Unknown" 2 "Type_Solid_Line" 3 "Type_Dashed_Line" ;
VAL_ 821 ADS_5_EgoRiLineColor 0 "No display" 1 "Color_Unknown" 2 "Color_White" 3 "Color_Yellow" ;
VAL_ 819 ADS_4_AEBStatus 0 "OFF" 1 "ON" 2 "Failure" 3 "available" 4 "active" 5 "pre-fill" 6 "blindness" 7 "Reserved" ;
VAL_ 819 ADS_4_ACCSts 0 "Off" 1 "Passive" 2 "Standby" 3 "Active_Control" 4 "BrakeOnly" 5 "Override" 6 "StandWait" 7 "failure" 8 "StandActive" 9 "reserved" 10 "reserved" 11 "reserved" 12 "reserved" 13 "reserved" 14 "reserved" 15 "reserved" ;
VAL_ 819 ADS_4_TimeGapSet 0 "None" 1 "Time Gap1" 2 "Time Gap2" 3 "Time Gap3" 4 "Time Gap4" 5 "Time Gap5" 6 "Reserved" 7 "Reserved" ;
VAL_ 819 ADS_4_FcwMode 0 "OFF" 1 "ON" 2 "Failure" 3 "Active" 4 "blindness" 5 "Reserved" 6 "Reserved" 7 "Reserved" ;
VAL_ 819 ADS_4_AEBReqType 0 "NoReq" 1 "AEBm" 2 "AEBp" 3 "AEBVru" 4 "EBA" 5 "LTA" 6 "CPTA" 7 "Reserved" ;
VAL_ 819 ADS_4_SetSpd 255 "Invalid" ;
VAL_ 819 ADS_4_DAIStatus 0 "On" 1 "Off" 2 "Failure" 3 "None" ;
VAL_ 819 ADS_4_ACCTextMessage 0 "No Display" 1 "ACC Activated" 2 "ACC Cannot Be Activated" 3 "ACC Cancelled" 4 "ACC failure" 5 "Weather abnormal" 6 "Driver Override" 7 "Active Decelerate" 8 "Cruise speed can not be added" 9 "ACC abort and take over request" 10 "Maximum decelerate to ahead speed sign" 11 "System add timegap to front big vehicle" 12 "Cut in reminder" 13 "Large curve remider" 14 "Auto drive off reminder" 15 "takeover timeout" ;
VAL_ 819 ADS_4_LongiTakeOverReq 0 "No Request" 1 "Request" ;
VAL_ 819 ADS_4_SetSpdUnit 0 "Km/h" 1 "Mile/h" ;
VAL_ 819 ADS_4_GoNotifier 0 "None" 1 "Go Notifier" 2 "Go Visual Notifier" 3 "Handson visual warning" 4 "Handson and DMS warning" 5 "Press gas reminder" 6 "Reserved" 7 "Reserved" ;
VAL_ 819 ADS_4_DAISts 0 "None" 1 "active Drive Off" 2 "Reserved" 3 "Reserved" ;
VAL_ 819 ADS_4_Radar_textinfo 0 "Radar normal" 1 "Radar failure" 2 "Radar blocked" 3 "Reserved" 4 "Reserved" 5 "Reserved" 6 "Reserved" 7 "Reserved" ;
VAL_ 819 ADS_4_SCF_PopoverReq 0 "No Request" 1 "Driver confirm Request" ;
VAL_ 819 ADS_4_DrvrCfmSCFDispFb 0 "not confirmed" 1 "confirme" ;
VAL_ 819 ADS_4_SCF_SpdLimUnit 0 "Unknown" 1 "km/h" 2 "Miles/h" 3 "Reserved" ;
VAL_ 819 ADS_4_SCF_SpdLimSts 0 "OFF" 1 "STANDBY" 2 "ACTIVE" 3 "REVERSIBLE_FAILURE" 4 "IREVERSIBLE FAILURE" 5 "Reserved" 6 "Reserved" 7 "Reserved" ;
VAL_ 819 ADS_4_ACCObjTyp 0 "No type" 1 "Car" 2 "Truck" 3 "Motorcycle" 4 "Pedestrian" 5 "Cyclist" 6 "Bus" 7 "Reserved" 8 "Reserved" 9 "Reserved" 10 "Reserved" 11 "Reserved" 12 "Reserved" 13 "Reserved" 14 "Reserved" 15 "Reserved" ;
VAL_ 819 ADS_4_FrntFarObjTyp 0 "No type" 1 "Car" 2 "Truck" 3 "Motorcycle" 4 "Pedestrian" 5 "Cyclist" 6 "Bus" 7 "Reserved" 8 "Reserved" 9 "Reserved" 10 "Reserved" 11 "Reserved" 12 "Reserved" 13 "Reserved" 14 "Reserved" 15 "Reserved" ;
VAL_ 819 ADS_4_FrntFarObjID 0 "Invalid" 1 "Valid" ;
VAL_ 819 ADS_4_ACCObjID 0 "Invalid" 1 "Valid" ;
VAL_ 819 ADS_4_LeObjID 0 "Invalid" 1 "Valid" ;
VAL_ 819 ADS_4_LeObjTyp 0 "No type" 1 "Car" 2 "Truck" 3 "Motorcycle" 4 "Pedestrian" 5 "Cyclist" 6 "Bus" 7 "Reserved" 8 "Reserved" 9 "Reserved" 10 "Reserved" 11 "Reserved" 12 "Reserved" 13 "Reserved" 14 "Reserved" 15 "Reserved" ;
VAL_ 819 ADS_4_RiObjID 0 "Invalid" 1 "Valid" ;
VAL_ 819 ADS_4_RiObjTyp 0 "No type" 1 "Car" 2 "Truck" 3 "Motorcycle" 4 "Pedestrian" 5 "Cyclist" 6 "Bus" 7 "Reserved" 8 "Reserved" 9 "Reserved" 10 "Reserved" 11 "Reserved" 12 "Reserved" 13 "Reserved" 14 "Reserved" 15 "Reserved" ;
VAL_ 819 ADS_4_SCFSwtSet 0 "None" 1 "ON" 2 "Off" 3 "reserved" ;
VAL_ 819 ADS_4_AEBSettingSt 0 "None" 1 "ON" 2 "Off" 3 "reserved" ;
VAL_ 819 ADS_4_FCWSettingSt 0 "None" 1 "Off" 2 "high" 3 "middle" 4 "low" 5 "reserved" 6 "reserved" 7 "reserved" ;
VAL_ 819 ADS_4_DAISwtSet 0 "None" 1 "ON" 2 "Off" 3 "reserved" ;
VAL_ 819 ADS_4_CruiseAccelerateSts 0 "None" 1 "Accelerating" 2 "Decelerating" 3 "Reserved" ;
VAL_ 1172 ExternalTemperature_C 254 "invalid" ;
VAL_ 1172 BlowSpeedLevelDisplaySts 0 "Not_Active" 1 "Level_1" 2 "Level_2" 3 "Level_3" 4 "Level_4" 5 "Level_5" 6 "Level_6" 7 "Level_7" 8 "Level_8" 9 "Level_9" 10 "Level_10" 11 "Reserved" 12 "Level_0" 13 "Reserved" 14 "Reserved" 15 "Reserved" ;
VAL_ 1147 CCP_1_FrontAutoACSwitchReq 0 "No_Pressed" 1 "Pressed" ;
VAL_ 1147 CCP_1_FrontOFFSwitchReq 0 "No_Pressed" 1 "Pressed" ;
VAL_ 1147 CCP_1_FBlowSpdCtrlSwitchReq 0 "No_Request" 1 "Speed_1_Request" 2 "Speed_2_Request" 3 "Speed_3_Request" 4 "Speed_4_Request" 5 "Speed_5_Request" 6 "Speed_6_Request" 7 "Speed_7_Request" 8 "Speed_8_Request" 9 "Speed_9_Request" 10 "Speed_10_Request" 12 "Speed_0_Request" 15 "Invalid" ;
VAL_ 1147 FLCCP_MainSetHeatReq 0 "Not_Active" 1 "OFF" 2 "Seat_heating_Level1" 3 "Seat_heating_Level2" 4 "Seat_heating_Level3" ;
VAL_ 1147 FLCCP_MainSetVentilationReq 0 "Not_Active" 1 "OFF" 2 "Seat_Ventilation_Level1" 3 "Seat_Ventilation_Level2" 4 "Seat_Ventilation_Level3" ;
VAL_ 1147 CCP_1_ACFastCool 0 "Not_Active" 1 "On" 2 "Off" 3 "Not_Used" ;
VAL_ 1107 TMS_PM25_Detect 0 "NotActive" 1 "Active" ;
VAL_ 1107 TMS_CCP_FrontAutoACSts 0 "NotActive" 1 "Active" ;
VAL_ 1107 TMS_CCP_ACStatus 0 "NotActive" 1 "Active" ;
VAL_ 1107 TMS_CCP_FrontOFFSts 0 "NotActive" 1 "Active" ;
VAL_ 1107 TMS_CCP_FBlowSpdCtrlSts 0 "No_Request" 1 "Speed_1_Request" 2 "Speed_2_Request" 3 "Speed_3_Request" 4 "Speed_4_Request" 5 "Speed_5_Request" 6 "Speed_6_Request" 7 "Speed_7_Request" 8 "Speed_8_Request" 9 "Speed_9_Request" 10 "Speed_10_Request" 12 "Speed_0_Request" 15 "Invalid" ;
VAL_ 1107 TMS_CCP_RecyMode 0 "no_Request" 1 "internal_Recycle_Request" 2 "external_Recycle_Request" 3 "auto_Recycle_Request" ;
VAL_ 1107 TMS_CCP_FrontDefrostSts 0 "NotActive" 1 "Active" ;
VAL_ 1107 TMS_UVC_WorkingBfReq 0 "No_Request" 1 "Open_Request" 2 "Close_Request" 3 "AUTO" ;
VAL_ 1107 TMS_UVC_LuminanceBfReq 0 "No_Request" 1 "Higher" 2 "Lower" 3 "Reserved" ;
VAL_ 1107 TMS_CCP_ACFastCool 0 "Not_Active" 1 "ON" 2 "OFF" 3 "Not_Used" ;
VAL_ 1107 TMS_CCP_ACFastHeat 0 "Not_Active" 1 "ON" 2 "OFF" 3 "Not_Used" ;
VAL_ 1175 CCP_2_RecyModeReq 0 "no_Request" 1 "internal_Recycle_Request" 2 "external_Recycle_Request" ;
VAL_ 1175 CCP_2_DefrostModeSwitchReq 0 "No_Pressed" 1 "Pressed" ;
VAL_ 1175 CCP_2_RearDefrostSwitchReq 0 "No_Pressed" 1 "Pressed" ;
VAL_ 1175 CCP_2_ACFastHeat 0 "Not_Active" 1 "ON" 2 "OFF" 3 "Not_Used" ;
VAL_ 1175 CCP_2_FrontBlowSpdCtrlSwitchReq 0 "No_Request" 1 "Speed_1_Request" 2 "Speed_2_Request" 3 "Speed_3_Request" 4 "Speed_4_Request" 5 "Speed_5_Request" 6 "Speed_6_Request" 7 "Speed_7_Request" 8 "Speed_8_Request" 9 "Speed_9_Request" 10 "Speed_10_Request" 12 "Speed_0_Request" 15 "Invalid" ;
VAL_ 1175 FRCCP_DeputySetHeatReq 0 "Not_Active" 1 "OFF" 2 "Seat_heating_Level1" 3 "Seat_heating_Level2" 4 "Seat_heating_Level3" ;
VAL_ 1175 FRCCP_DeputySetVentilationReq 0 "Not_Active" 1 "OFF" 2 "Seat_Ventilation_Level1" 3 "Seat_Ventilation_Level2" 4 "Seat_Ventilation_Level3" ;
VAL_ 1175 CCP_2_ACSwitchReq 0 "No_Pressed" 1 "Pressed" ;
VAL_ 1292 CHB_App_Sts 0 "NotActive" 1 "Chb_ON" 2 "Chb_OFF" 3 "reserved" ;
VAL_ 1292 CHB_AppMem_Sts 0 "NotActive" 1 "ChbMem_ON" 2 "ChbMem_OFF" 3 "reserved" ;
VAL_ 1292 CHB_AppDelay_Sts 0 "NotActive" 1 "ChbDelay_ON" 2 "ChbDelay_OFF" 3 "reserved" ;
VAL_ 1292 CHB_AppCoolorheat_Sts 0 "NotActive" 1 "ChbCool_on" 2 "ChbHeat_on" 3 "Close" 4 "ColdDrinkMode" 5 "IceCreamMode" 6 "WarmMilkMode" 7 "WarmDrinkMode" ;
VAL_ 1292 CHB_AppCoolset_Sts 0 "Not_Active" 1 "ChbCoolset_-6" 2 "ChbCoolset_-5" 3 "ChbCoolset_-4" 4 "ChbCoolset_-3" 5 "ChbCoolset_-2" 6 "ChbCoolset_-1" 7 "ChbCoolset_0" 8 "ChbCoolset_1" 9 "ChbCoolset_2" 10 "ChbCoolset_3" 11 "ChbCoolset_4" 12 "ChbCoolset_5" 13 "ChbCoolset_6" 14 "ChbCoolset_-18" 15 "ChbCoolset_-17" 16 "ChbCoolset_-16" 17 "ChbCoolset_-15" 18 "ChbCoolset_-14" 19 "ChbCoolset_-13" 20 "ChbCoolset_-12" 21 "ChbCoolset_-11" 22 "ChbCoolset_-10" 23 "ChbCoolset_-9" 24 "ChbCoolset_-8" 25 "ChbCoolset_-7" 26 "Reserved" 27 "Reserved" 28 "Reserved" 29 "Reserved" 30 "Reserved" 31 "Reserved" ;
VAL_ 1292 CHB_AppHeatset_Sts 0 "Not_Active" 1 "ChbHeatset_35" 2 "ChbHeatset_36" 3 "ChbHeatset_37" 4 "ChbHeatset_38" 5 "ChbHeatset_39" 6 "ChbHeatset_40" 7 "ChbHeatset_41" 8 "ChbHeatset_42" 9 "ChbHeatset_43" 10 "ChbHeatset_44" 11 "ChbHeatset_45" 12 "ChbHeatset_46" 13 "ChbHeatset_47" 14 "ChbHeatset_48" 15 "ChbHeatset_49" 16 "ChbHeatset_50" ;
VAL_ 1292 CHB_AppSterilization_Sts 0 "NotActive" 1 "Chbsterilize_ON" 2 "Chbsterilize_OFF" 3 "Chbsterilize_Stop" ;
VAL_ 1292 CHB_AppItemsLeft_Sts 0 "NotActive" 1 "ChbItemsLeft_ON" 2 "ChbItemsLeft_OFF" 3 "reserved" ;
VAL_ 1292 CHB_AppItemsLeftset_Sts 0 "NotActive" 1 "CHB_ItemsLeftset_ON" 2 "CHB_ItemsLeftset_OFF" 3 "Reserved" ;
VAL_ 1292 CHB_AppChbDoor_Sts 0 "NotActive" 1 "ChbDoor_ON" 2 "ChbDoor_OFF" 3 "reserved" ;
VAL_ 1241 FuelTankLidSystemFailureSts 0 "No failure" 1 "Failure" ;
VAL_ 1241 FuelTankPressureConditionReached 0 "Not Active" 1 "Wait to refuel" 2 "Ready to refuel" 3 "Reserved" ;
VAL_ 49 ACU_2_LateralAcceleration 65535 "Invalid" ;
VAL_ 49 ACU_2_YawRate 65535 "Invalid" ;
VAL_ 49 ACU_2_YawrateSigValidData 0 "Valid" 1 "Reserved" 2 "Invalid" 3 "Initialize" ;
VAL_ 49 ACU_2_LateralAccelerationSigVD 0 "Valid" 1 "Reserved" 2 "Invalid" 3 "Initialize" ;
VAL_ 1024 CSunshadeSts 0 "Not Active" 1 "Open" 2 "Close" 3 "Half_Open" 4 "Opening" 5 "Closing" 6 "Stop" 7 "Error" ;
VAL_ 1024 CSunshadePercentSts 0 "Not Active" 1 "0%" 2 "10%" 3 "20%" 4 "30%" 5 "40%" 6 "50%" 7 "60%" 8 "70%" 9 "80%" 10 "90%" 11 "100%" 12 "reserved" 13 "reserved" 14 "reserved" 15 "reserved" ;
VAL_ 1024 FRZCU_SeatHeatLvlFR2 0 "Not Active" 1 "OFF" 2 "Level1" 3 "Level2" 4 "Level3" 5 "Level4" 6 "Level5" 7 "Level6" 8 "Level7" 9 "Level8" 10 "Level9" ;
VAL_ 1024 FRZCU_SeatVentLvlFR2 0 "Not Active" 1 "OFF" 2 "Level1" 3 "Level2" 4 "Level3" 5 "Level4" 6 "Level5" 7 "Level6" 8 "Level7" 9 "Level8" 10 "Level9" ;
VAL_ 1024 FRZCU_SeatVentLvlRR2 0 "Not Active" 1 "OFF" 2 "Level1" 3 "Level2" 4 "Level3" 5 "Level4" 6 "Level5" 7 "Level6" 8 "Level7" 9 "Level8" 10 "Level9" ;
VAL_ 1024 FRZCU_SeatHeatLvlRR2 0 "Not Active" 1 "OFF" 2 "Level1" 3 "Level2" 4 "Level3" 5 "Level4" 6 "Level5" 7 "Level6" 8 "Level7" 9 "Level8" 10 "Level9" ;
VAL_ 1024 FRZCU_ContainerlightSts 0 "Not Active" 1 "ON" 2 "OFF" 3 "reserved" ;
VAL_ 1024 FRZCU_FRWinThermalSts 0 "Normal" 1 "Thermal protection" ;
VAL_ 1024 FRZCU_RRWinThermalSts 0 "Normal" 1 "Thermal protection" ;
VAL_ 1024 FRZCU_CSunshadeThermalSts 0 "Normal" 1 "Thermal protection" ;
VAL_ 1182 OBC_ElectronicLockSts 0 "Unlock" 1 "Lock" 2 "Lock error" 3 "Unlock error" 4 "Elock error" ;
VAL_ 1182 OBC_WorkingMode 0 "Init" 1 "Standby" 2 "Chg" 3 "Default" 4 "Preheat" 5 "Keepwarm" 6 "V2L" 7 "V2V" 8 "Powerdown" 9 "Afterrun" 10 "Fault" 11 "Reserved" 12 "Reserved" 13 "Reserved" 14 "Reserved" 15 "Reserved" ;
VAL_ 1182 OBC_OutDischgCurr 1023 "Invalid" ;
VAL_ 1182 OBC_OutDischgVolt 8191 "Invalid" ;
VAL_ 290 EPSFailSts 0 "Not present" 1 "Fail present" 2 "Reserved" 3 "Reserved" ;
VAL_ 290 EPSSteeringAngleCalibrationSts 0 "Calibration is fine" 1 "No calibration or no initialization" ;
VAL_ 290 EPS_EOTLearning_Sts 0 "Learnt" 1 "Not Learnt" ;
VAL_ 513 MFSL_UP_SW 0 "Not_action" 1 "Pressed" 2 "Stuck" 3 "invalid" ;
VAL_ 513 MFSL_DW_SW 0 "Not_action" 1 "Pressed" 2 "Stuck" 3 "invalid" ;
VAL_ 513 MFSL_Left_SW 0 "Not_action" 1 "Pressed" 2 "Stuck" 3 "invalid" ;
VAL_ 513 MFSL_Right_SW 0 "Not_action" 1 "Pressed" 2 "Stuck" 3 "invalid" ;
VAL_ 513 MFSL_OK_SW 0 "Not_action" 1 "Pressed" 2 "Stuck" 3 "invalid" ;
VAL_ 513 MFSL_AVM_SW 0 "Not_action" 1 "Pressed" 2 "Stuck" 3 "invalid" ;
VAL_ 513 MFSL_Customize 0 "Not_action" 1 "Pressed" 2 "Stuck" 3 "invalid" ;
VAL_ 1208 PPMID_1_PPMICounter 0 "Count not full" 1 "Count is full" ;
VAL_ 1208 PPMID_1_PPMISt 0 "PPMI no error" 1 "PPMI initialization" 2 "PPMI internal error" 3 "External error" 4 "Reserved" 5 "Reserved" 6 "Reserved" 7 "Reserved" ;
VAL_ 1208 PPMID_1_HWSts 0 "Not active" 1 "ON" 2 "OFF" 3 "Reserved" ;
VAL_ 1208 PPMID_1_BSRBPASts 0 "Not active" 1 "ON" 2 "OFF" 3 "Reserved" ;
VAL_ 794 ADS_3_ICAStatus 0 "Off" 1 "Passive" 2 "Standby" 3 "Active" 4 "Failure" 5 "Suspend" 6 "reserved" 7 "reserved" ;
VAL_ 794 ADS_3_ICATextinfo 0 "No dispaly" 1 "TJAICA Activated" 2 "TJAICA Cannot Be Activated" 3 "TJAICA Cancelled" 4 "TJAICA failure" 5 "TJAICA Suspend" 6 "TJAICA resumed" 7 "TJAICA degrade to ACC" 8 "Urgent TOR request" 9 "uncentered" 10 "Too Large curve" 11 "Abnormal tire pressure" 12 "Camera block" 13 "Master switch is off" 14 "reserved" 15 "reserved" ;
VAL_ 794 ADS_3_ACCSts 0 "Off" 1 "Passive" 2 "Standby" 3 "Active_Control" 4 "Brake Only" 5 "Override" 6 "Stand Wait" 7 "failure" 8 "Stand Active" 9 "reserved" 10 "reserved" 11 "reserved" 12 "reserved" 13 "reserved" 14 "reserved" 15 "reserved" ;
VAL_ 794 ADS_3_DriverHandsoffWarning 0 "None" 1 "Warning 1 for stage1" 2 "Warning 2  for stage2" 3 "Warning 3 for stage3(TOR)" 4 "Warning 4 for stage4(Punishment)" 5 "reserved" 6 "reserved" 7 "reserved" ;
VAL_ 794 ADS_3_LKSMod 0 "Off" 1 "Warning" 2 "Warning+intervention" 3 "reserved" ;
VAL_ 794 ADS_3_LKSSts 0 "OFF" 1 "Standby" 2 "Active" 3 "Failure" 4 "Passive" 5 "Reserved" 6 "Blindness(捷途使用)" 7 "Reserved" ;
VAL_ 794 ADS_3_ELKSts 0 "OFF" 1 "Standby" 2 "Active" 3 "Failure" 4 "Passive" 5 "Reserved" 6 "Blindness(捷途使用)" 7 "Reserved" ;
VAL_ 794 ADS_3_LKSLeftTrackingSt 0 "Inactive" 1 "Lane Tracking" 2 "Intervention" 3 "warning" ;
VAL_ 794 ADS_3_LKSRightTrackingSt 0 "Inactive" 1 "Lane Tracking" 2 "Intervention" 3 "warning" ;
VAL_ 794 ADS_3_ELKLeftActiveSt 0 "no warning" 1 "tracking" 2 "intervention" ;
VAL_ 794 ADS_3_ELKRightActiveSt 0 "no warning" 1 "tracking" 2 "intervention" ;
VAL_ 1155 ASU_3_horizontalSts 0 "Not Active" 1 "ON" 2 "OFF" 3 "Not use" ;
VAL_ 1155 ASU_3_horizontalmodeFb 0 "Not Active" 1 "Working" 2 "Complete" 3 "Abort" 4 "Failure" 5 "Reserved" 6 "Reserved" 7 "Reserved" ;
VAL_ 1164 OBC_DischgSts 0 "NoDischarge" 1 "Discharging" 2 "Discharging-Interior" 3 "Discharging_AND_Discharging-Interior" ;
VAL_ 789 ATCM_DriveModeSw 0 "Not Active" 1 "Plus" 2 "Minus" 3 "Reserved" ;
VAL_ 789 ATCM_XModeSw 0 "Not_Active" 1 "ON" 2 "OFF" 3 "Reserved" ;
VAL_ 789 ATCM_SwitchUTurnModeSet 0 "Release" 1 "Press" ;
VAL_ 1095 RLCR_1_SysSt 0 "Off" 1 "On" 2 "Temporary Error" 3 "System Error" ;
VAL_ 1095 RLCR_1_BlkSts 0 "Not Blockage" 1 "Blockage" ;
VAL_ 1095 RLCR_1_BSDWarn 0 "No Warning" 1 "Standard Warning" 2 "Critical Warning" 3 "Not Used" ;
VAL_ 1095 RLCR_1_DOWWarn 0 "No Warning" 1 "Level1 Warning" 2 "Level2 Warning" 3 "Not Used" ;
VAL_ 1095 RLCR_1_DowLock 0 "No Warning" 1 "Dow lock" 2 "Dow unlock" 3 "Not Used" ;
VAL_ 1095 RLCR_1_ELK_Collision_flag 0 "No critical situation of collision" 1 "Critical situation of collision" ;
VAL_ 1095 RLCR_1_ELK_CollisionFlagValid 0 "Not valid" 1 "Valid" ;
VAL_ 1267 RRCR_1_SysSt 0 "Off" 1 "On" 2 "Temporary Error" 3 "System Error" ;
VAL_ 1267 RRCR_1_BlkSts 0 "Not Blockage" 1 "Blockage" ;
VAL_ 1267 RRCR_1_BSDWarn 0 "No Warning" 1 "Standard Warning" 2 "Critical Warning" 3 "Not Used" ;
VAL_ 1267 RRCR_1_DOWWarn 0 "No Warning" 1 "Level1 Warning" 2 "Level2 Warning" 3 "Not Used" ;
VAL_ 1267 RRCR_1_DowLock 0 "No Warning" 1 "Dow lock" 2 "Dow unlock" 3 "Not Used" ;
VAL_ 1267 RRCR_1_ELK_Collision_flag 0 "No critical situation of collision" 1 "Critical situation of collision" ;
VAL_ 1267 RRCR_1_ELK_CollisionFlagValid 0 "Not valid" 1 "Valid" ;
VAL_ 788 ADS_2_AEBStatus 0 "OFF" 1 "ON" 2 "Failure" 3 "available" 4 "active" 5 "pre-fill" 6 "blindness" ;
VAL_ 788 ADS_2_FCWStatus 0 "no request" 1 "level 1(low)" 2 "level 2(middle)" 3 "level 3(high)" 4 "reserved" 5 "reserved" 6 "reserved" 7 "reserved" ;
VAL_ 788 FCM_2_IHCfunctionSts 0 "Off" 1 "Standby" 2 "Active" 3 "Fault" 4 "Reserved" 5 "Reserved" 6 "Reserved" 7 "Reserved" ;
VAL_ 571 LHTurnlightSts 0 "Not Active" 1 "Active" ;
VAL_ 571 RHTurnlightSts 0 "Not Active" 1 "Active" ;
VAL_ 571 LHFdoorSts 0 "Close" 1 "Ajar" 2 "full_open" 3 "Reserved" ;
VAL_ 571 LHFDoorLockSts 0 "Locked" 1 "Unlocked" 2 "Superlocked" 3 "Unknown" ;
VAL_ 571 LHTurnSW 0 "Off" 1 "Active" ;
VAL_ 571 RHTurnSW 0 "Off" 1 "Active" ;
VAL_ 571 HazardLightSW 0 "Close" 1 "Open" ;
VAL_ 571 LHFSeatBeltSW 0 "Not Active" 1 "Active" ;
VAL_ 571 DirectionIndLeft 0 "Close" 1 "Open" ;
VAL_ 571 DirectionIndRight 0 "Close" 1 "Open" ;
VAL_ 699 LHRdoorSts 0 "Close" 1 "Ajar" 2 "full_open" 3 "Reserved" ;
VAL_ 787 ChrgHoodSts 0 "Close" 1 "Open" ;
VAL_ 787 FRZCU_FRSitPosnSts 0 "Not Active" 1 "Location1" 2 "Location2" 3 "Location3" ;
VAL_ 524 ADS_6_AVM_FuncSts 0 "default" 1 "off" 2 "active" 3 "failure" ;
VAL_ 524 ADS_6_AVM_ButtonClick 0 "none" 1 "clicked" ;
VAL_ 524 ADS_6_Customize_buttonsFB 0 "Not Active" 1 "APA" 2 "TJA/ICA/ACC/NOA" 3 "Offroad AutoPilot" 4 "HPA" 5 "Not used" 6 "Not used" 7 "Not used" ;
VAL_ 524 ADS_6_PAS_AudioTone 0 "No Object" 1 "Continous Tone" 2 "Fast Tone" 3 "Medium Tone" 4 "Slow Tone" 5 "Reserved" 6 "Reserved" 7 "Reserved" ;
VAL_ 572 ONEBOX_7_TAB_HighTemp 0 "No Active" 1 "Active" ;
VAL_ 572 ONEBOX_7_TAB_Active 0 "Not Active" 1 "Active" 2 "Stand by" 3 "Failed" ;
VAL_ 572 ONEBOX_7_BSW_Active 0 "Not Active" 1 "Active" 2 "Filed" 3 "Reserved" ;
VAL_ 783 ADCC_SysReadySts 0 "Ready" 1 "not Ready" ;
VAL_ 1037 ADS_RCTAWarn_Left 0 "No Warning" 1 "Warning" ;
VAL_ 1037 ADS_RCTAWarn_Rigth 0 "No Warning" 1 "Warning" ;
VAL_ 1037 ADS_FCTAWarn_Left 0 "No Warning" 1 "Warning" ;
VAL_ 1037 ADS_FCTAWarn_Right 0 "No Warning" 1 "Warning" ;
VAL_ 943 OverWeightRatio 0 "未超载" 1 "超载0-10%" 2 "超载10%~20%" 3 "超载20%~30%" 4 "超载30%`40%" 5 "严重超载" 6 "Reserved" 7 "Reserved" ;
VAL_ 943 OverWeightWarning 0 "No warning" 1 "Warning" ;
VAL_ 943 OverLoadWarnShieldSetFed 0 "Not Active" 1 "ON" 2 "OFF" 3 "Fault" ;
VAL_ 1120 RLHS_2_AmbBrightness 4095 "Invalid" ;
VAL_ 1120 RLHS_LiSwithReason 0 "Darkstart" 1 "Day" 2 "Night" 3 "Tunnul" ;
VAL_ 850 ASU_6_HMIFailFb_JT 0 "Not Active" 1 "SUSP IS lock" 2 "PLG is open" 3 "suspension height disable" 4 "suspension damping disable" 5 "Altitude too high" 6 "reserved" 7 "reserved" 8 "reserved" 9 "reserved" 10 "reserved" 11 "reserved" 12 "reserved" 13 "reserved" 14 "reserved" 15 "reserved" ;
VAL_ 1199 TCM_1_TrailerSts 0 "Disconnect" 1 "Connect" ;
SIG_GROUP_ 1328 RADAR_1_0x530_E2E_P01_1 1 : RADAR_1_RadarDetectSts RADAR_1_RadarWorkSts RADAR_1_Resd1 RADAR_1_LHRRadarSensorDistance RADAR_1_RHMRRadarSensorDistance RADAR_1_LHMRRadarSensorDistance RADAR_1_RHRRadarSensorDistance RADAR_1_LHFRadarSensorDistance RADAR_1_RHFRadarSensorDistance RADAR_1_ParkingRadarSwSts RADAR_1_RHMFRadarSensorDistance RADAR_1_LHMFRadarSensorDistance RADAR_1_AudibleBeepRate;
SIG_GROUP_ 1291 BMS_2_G_0x50B_E2E_P01_1 1 : BMS_2_G_CRC BMS_2_G_RollgCntr BMS_2_G_Resd BMS_TBOXInsulation_R BMS_TBOXErrorNumber BMS_TBOXHvBattMaxT BMS_TBOXHvBattMinT BMS_SOCLight;
SIG_GROUP_ 1104 RLCR_2_0x450_E2E_P01_1 1 : RLCR_2_CRC1 RLCR_2_RollgCntr1 RLCR_2_Resd1 RLCR_2_RCWWarn RLCR_2_RCTAWarn RLCR_2_BSDLCWONOFFSts RLCR_2_DOWONOFFSts RLCR_2_RCWONOFFSts RLCR_2_RCTARCTBONOFFSts;
SIG_GROUP_ 1271 RRCR_2_0x4F7_E2E_P01_1 1 : RRCR_2_CRC1 RRCR_2_RollgCntr1 RRCR_2_Resd1 RRCR_2_RCWWarn RRCR_2_RCTAWarn RRCR_2_BSDLCWONOFFSts RRCR_2_DOWONOFFSts RRCR_2_RCWONOFFSts RRCR_2_RCTARCTBONOFFSts;
SIG_GROUP_ 1180 New_Signal_Group_49C 1 : ACU_1_PsngrSeatOccupiedSts ACU_1_SecRowRBeltWarning ACU_1_SecRowMBeltWarning ACU_1_SecRowLBeltWarning ACU_1_PsngrSeatBeltWarning ACU_1_ThdRowRBeltWarning ACU_1_ThdRowLBeltWarning ACU_1_AirBagFailSts ACU_1_CRC1 ACU_1_RollgCntr1 ACU_1_Resd1 ABM_1_Rollover_Status New_Signal_49C_1 New_Signal_49C_2 New_Signal_49C_3 New_Signal_49C_4 New_Signal_49C_5 New_Signal_49C_6 New_Signal_49C_7 New_Signal_49C_8;
SIG_GROUP_ 290 EPS_1_0x122_E2E_P01_1 1 : EPS_1_CRC EPS_1_RollgCntr EPSFailSts EPSSteeringAngleCalibrationSts EPS_EOTLearning_Sts;
SIG_GROUP_ 1095 RLCR_1_0x447_E2E_P01_1 1 : RLCR_1_CRC1 RLCR_1_RollgCntr1 RLCR_1_Resd1 RLCR_1_SysSt RLCR_1_BlkSts RLCR_1_BSDWarn RLCR_1_DOWWarn RLCR_1_DowLock RLCR_1_ELK_Collision_flag RLCR_1_ELK_CollisionFlagValid;
SIG_GROUP_ 1267 RRCR_1_0x4F3_E2E_P01_1 1 : RRCR_1_CRC1 RRCR_1_RollgCntr1 RRCR_1_Resd1 RRCR_1_SysSt RRCR_1_BlkSts RRCR_1_BSDWarn RRCR_1_DOWWarn RRCR_1_DowLock RRCR_1_ELK_Collision_flag RRCR_1_ELK_CollisionFlagValid;
SIG_GROUP_ 524 ADS_6_0x20C_E2E_P01_1 1 : New_Signal_20C New_Signal_20C_1 ADS_6_CRC1 ADS_6_RollgCntr1 ADS_6_Resd1 ADS_6_AVM_FuncSts ADS_6_AVM_ButtonClick ADS_6_Customize_buttonsFB ADS_6_PAS_AudioTone;
